VERSION "dbc-export 1 2025.20.8"

NS_ :

BS_:

BU_: ADSP APB APP APS APSB BB BMS CC CMP CMPD CP DAS DI DIF DIR DPB EPAS3P EPAS3S EPASTP EPASTS EPBL EPBR ESP EVSE FC GTW HCML HCMR HVP IBST ICR IDB LS OCS1P ODIN PARK PCS PLG PM PMF PMR PNCD PTC RADC RCM RCM2 RCM3 RCU SCCM SCM SCS SDCR TAS TCU TPMS TRCM UDS UI UIS UMC USM VC VCFRONT VCLEFT VCRIGHT VCSEC VEH

BO_ 1835 TAS_alertLog: 8 TAS
 SG_ TAS_alertID M : 0|9@1+ (1,0) [0|511] "" Vector__XXX
 SG_ TAS_alertState : 15|1@1+ (1,0) [0|1] "" Vector__XXX
 SG_ TAS_a001_InternalWatchdog m1 : 16|1@1+ (1,0) [0|1] "" Vector__XXX
 SG_ TAS_a002_CPUUndervoltage m2 : 16|1@1+ (1,0) [0|1] "" Vector__XXX
 SG_ TAS_a002_PowerOnReset m2 : 17|1@1+ (1,0) [0|1] "" Vector__XXX
 SG_ TAS_a003_AssertID m3 : 16|16@1+ (1,0) [0|65535] "" Vector__XXX
 SG_ TAS_a003_LineNumber m3 : 32|16@1+ (1,0) [0|65535] "" Vector__XXX
 SG_ TAS_a003_Data m3 : 48|16@1+ (1,0) [0|65535] "" Vector__XXX
 SG_ TAS_a012_ClockError m12 : 16|1@1+ (1,0) [0|1] "" Vector__XXX
 SG_ TAS_a012_FlashError m12 : 17|1@1+ (1,0) [0|1] "" Vector__XXX
 SG_ TAS_a012_SoftwareReset m12 : 18|1@1+ (1,0) [0|1] "" Vector__XXX
 SG_ TAS_a012_CheckstopReset m12 : 19|1@1+ (1,0) [0|1] "" Vector__XXX
 SG_ TAS_a012_DebugReset m12 : 20|1@1+ (1,0) [0|1] "" Vector__XXX
 SG_ TAS_a012_ExternalReset m12 : 21|1@1+ (1,0) [0|1] "" Vector__XXX
 SG_ TAS_a021_Task1msLate m21 : 16|1@1+ (1,0) [0|1] "" Vector__XXX
 SG_ TAS_a021_Task1msStarved m21 : 17|1@1+ (1,0) [0|1] "" Vector__XXX
 SG_ TAS_a021_Task1msMissed m21 : 18|1@1+ (1,0) [0|1] "" Vector__XXX
 SG_ TAS_a021_Task10msLate m21 : 19|1@1+ (1,0) [0|1] "" Vector__XXX
 SG_ TAS_a021_Task10msStarved m21 : 20|1@1+ (1,0) [0|1] "" Vector__XXX
 SG_ TAS_a021_Task10msMissed m21 : 21|1@1+ (1,0) [0|1] "" Vector__XXX
 SG_ TAS_a021_Task100msLate m21 : 22|1@1+ (1,0) [0|1] "" Vector__XXX
 SG_ TAS_a021_Task100msStarved m21 : 23|1@1+ (1,0) [0|1] "" Vector__XXX
 SG_ TAS_a021_Task100msMissed m21 : 24|1@1+ (1,0) [0|1] "" Vector__XXX
 SG_ TAS_a021_Task1000msLate m21 : 25|1@1+ (1,0) [0|1] "" Vector__XXX
 SG_ TAS_a021_Task1000msStarved m21 : 26|1@1+ (1,0) [0|1] "" Vector__XXX
 SG_ TAS_a021_Task1000msMissed m21 : 27|1@1+ (1,0) [0|1] "" Vector__XXX
 SG_ TAS_a022_TaskInitErrorCount m22 : 16|8@1+ (1,0) [0|255] "" Vector__XXX
 SG_ TAS_a022_TaskInitError0 m22 : 24|8@1+ (1,0) [0|255] "" Vector__XXX
 SG_ TAS_a022_TaskInitError1 m22 : 32|8@1+ (1,0) [0|255] "" Vector__XXX
 SG_ TAS_a022_TaskInitError2 m22 : 40|8@1+ (1,0) [0|255] "" Vector__XXX
 SG_ TAS_a022_TaskInitError3 m22 : 48|8@1+ (1,0) [0|255] "" Vector__XXX
 SG_ TAS_a022_TaskInitError4 m22 : 56|8@1+ (1,0) [0|255] "" Vector__XXX
 SG_ TAS_a025_vehicleLockAtCrash m25 : 16|1@1+ (1,0) [0|1] "" Vector__XXX
 SG_ TAS_a025_CANCrashIsActive m25 : 17|1@1+ (1,0) [0|1] "" Vector__XXX
 SG_ TAS_a025_appCrashIsActive m25 : 18|1@1+ (1,0) [0|1] "" Vector__XXX
 SG_ TAS_a025_lastCrashEvent m25 : 24|32@1+ (1,0) [0|4294967295] "" Vector__XXX
 SG_ TAS_a030_PWMdutyCycleFL m30 : 16|16@1+ (0.0025,0) [0|163.8375] "%" Vector__XXX
 SG_ TAS_a030_PWMfrequencyFL m30 : 32|16@1+ (0.025,0) [0|1638.375] "Hz" Vector__XXX
 SG_ TAS_a030_PWMfaultFL m30 : 48|4@1+ (1,0) [0|15] "" Vector__XXX
 SG_ TAS_a031_PWMdutyCycleFR m31 : 16|16@1+ (0.0025,0) [0|163.8375] "%" Vector__XXX
 SG_ TAS_a031_PWMfrequencyFR m31 : 32|16@1+ (0.025,0) [0|1638.375] "Hz" Vector__XXX
 SG_ TAS_a031_PWMfaultFR m31 : 48|4@1+ (1,0) [0|15] "" Vector__XXX
 SG_ TAS_a032_PWMdutyCycleRL m32 : 16|16@1+ (0.0025,0) [0|163.8375] "%" Vector__XXX
 SG_ TAS_a032_PWMfrequencyRL m32 : 32|16@1+ (0.025,0) [0|1638.375] "Hz" Vector__XXX
 SG_ TAS_a032_PWMfaultRL m32 : 48|4@1+ (1,0) [0|15] "" Vector__XXX
 SG_ TAS_a033_PWMdutyCycleRR m33 : 16|16@1+ (0.0025,0) [0|163.8375] "%" Vector__XXX
 SG_ TAS_a033_PWMfrequencyRR m33 : 32|16@1+ (0.025,0) [0|1638.375] "Hz" Vector__XXX
 SG_ TAS_a033_PWMfaultRR m33 : 48|4@1+ (1,0) [0|15] "" Vector__XXX
 SG_ TAS_a034_PWMdutyCycleFL m34 : 16|16@1+ (0.0025,0) [0|163.8375] "%" Vector__XXX
 SG_ TAS_a034_PWMfrequencyFL m34 : 32|16@1+ (0.025,0) [0|1638.375] "Hz" Vector__XXX
 SG_ TAS_a034_PWMfaultFL m34 : 48|4@1+ (1,0) [0|15] "" Vector__XXX
 SG_ TAS_a035_PWMdutyCycleFR m35 : 16|16@1+ (0.0025,0) [0|163.8375] "%" Vector__XXX
 SG_ TAS_a035_PWMfrequencyFR m35 : 32|16@1+ (0.025,0) [0|1638.375] "Hz" Vector__XXX
 SG_ TAS_a035_PWMfaultFR m35 : 48|4@1+ (1,0) [0|15] "" Vector__XXX
 SG_ TAS_a036_PWMdutyCycleRL m36 : 16|16@1+ (0.0025,0) [0|163.8375] "%" Vector__XXX
 SG_ TAS_a036_PWMfrequencyRL m36 : 32|16@1+ (0.025,0) [0|1638.375] "Hz" Vector__XXX
 SG_ TAS_a036_PWMfaultRL m36 : 48|4@1+ (1,0) [0|15] "" Vector__XXX
 SG_ TAS_a037_PWMdutyCycleRR m37 : 16|16@1+ (0.0025,0) [0|163.8375] "%" Vector__XXX
 SG_ TAS_a037_PWMfrequencyRR m37 : 32|16@1+ (0.025,0) [0|1638.375] "Hz" Vector__XXX
 SG_ TAS_a037_PWMfaultRR m37 : 48|4@1+ (1,0) [0|15] "" Vector__XXX
 SG_ TAS_a038_PWMdutyCycleFL m38 : 16|16@1+ (0.0025,0) [0|163.8375] "%" Vector__XXX
 SG_ TAS_a038_PWMfrequencyFL m38 : 32|16@1+ (0.025,0) [0|1638.375] "Hz" Vector__XXX
 SG_ TAS_a038_PWMfaultFL m38 : 48|4@1+ (1,0) [0|15] "" Vector__XXX
 SG_ TAS_a039_PWMdutyCycleFR m39 : 16|16@1+ (0.0025,0) [0|163.8375] "%" Vector__XXX
 SG_ TAS_a039_PWMfrequencyFR m39 : 32|16@1+ (0.025,0) [0|1638.375] "Hz" Vector__XXX
 SG_ TAS_a039_PWMfaultFR m39 : 48|4@1+ (1,0) [0|15] "" Vector__XXX
 SG_ TAS_a040_PWMdutyCycleRL m40 : 16|16@1+ (0.0025,0) [0|163.8375] "%" Vector__XXX
 SG_ TAS_a040_PWMfrequencyRL m40 : 32|16@1+ (0.025,0) [0|1638.375] "Hz" Vector__XXX
 SG_ TAS_a040_PWMfaultRL m40 : 48|4@1+ (1,0) [0|15] "" Vector__XXX
 SG_ TAS_a041_PWMdutyCycleRR m41 : 16|16@1+ (0.0025,0) [0|163.8375] "%" Vector__XXX
 SG_ TAS_a041_PWMfrequencyRR m41 : 32|16@1+ (0.025,0) [0|1638.375] "Hz" Vector__XXX
 SG_ TAS_a041_PWMfaultRR m41 : 48|4@1+ (1,0) [0|15] "" Vector__XXX
 SG_ TAS_a070_voltage12V m70 : 16|16@1+ (0.001,0) [0|65.535] "V" Vector__XXX
 SG_ TAS_a071_voltage12V m71 : 16|16@1+ (0.001,0) [0|65.535] "V" Vector__XXX
 SG_ TAS_a072_voltage5VOnBoard m72 : 16|16@1+ (0.001,0) [0|65.535] "V" Vector__XXX
 SG_ TAS_a073_voltage5VOnBoard m73 : 16|16@1+ (0.001,0) [0|65.535] "V" Vector__XXX
 SG_ TAS_a074_voltage5VOffBoard m74 : 16|16@1+ (0.001,0) [0|65.535] "V" Vector__XXX
 SG_ TAS_a075_voltage5VOffBoard m75 : 16|16@1+ (0.001,0) [0|65.535] "V" Vector__XXX
 SG_ TAS_a076_voltage5VOffBoard m76 : 16|16@1+ (0.001,0) [0|65.535] "V" Vector__XXX
 SG_ TAS_a077_sensorVoltage m77 : 16|16@1+ (0.001,0) [0|65.535] "V" Vector__XXX
 SG_ TAS_a077_sensorRefVoltage m77 : 32|16@1+ (0.001,0) [0|65.535] "V" Vector__XXX
 SG_ TAS_a078_sensorVoltage m78 : 16|16@1+ (0.001,0) [0|65.535] "V" Vector__XXX
 SG_ TAS_a078_sensorRefVoltage m78 : 32|16@1+ (0.001,0) [0|65.535] "V" Vector__XXX
 SG_ TAS_a080_voltage5VHeight m80 : 16|16@1+ (0.001,0) [0|65.535] "V" Vector__XXX
 SG_ TAS_a081_voltage5VHeight m81 : 16|16@1+ (0.001,0) [0|65.535] "V" Vector__XXX
 SG_ TAS_a082_voltage5VHeight m82 : 16|16@1+ (0.001,0) [0|65.535] "V" Vector__XXX
 SG_ TAS_a083_voltage5VAnalog m83 : 16|16@1+ (0.001,0) [0|65.535] "V" Vector__XXX
 SG_ TAS_a084_voltage5VAnalog m84 : 16|16@1+ (0.001,0) [0|65.535] "V" Vector__XXX
 SG_ TAS_a085_voltage5VAnalog m85 : 16|16@1+ (0.001,0) [0|65.535] "V" Vector__XXX
 SG_ TAS_a086_voltage12VSwitched m86 : 16|16@1+ (0.001,0) [0|65.535] "V" Vector__XXX
 SG_ TAS_a087_voltage12VSwitched m87 : 16|16@1+ (0.001,0) [0|65.535] "V" Vector__XXX
 SG_ TAS_a093_readError m93 : 16|1@1+ (1,0) [0|1] "" Vector__XXX
 SG_ TAS_a093_IVOR2Exception m93 : 17|1@1+ (1,0) [0|1] "" Vector__XXX
 SG_ TAS_a098_VCFRONT_LVPowerState_MI m98 : 16|1@1+ (1,0) [0|1] "" Vector__XXX
 SG_ TAS_a098_VCFRONT_sensors_MIA m98 : 17|1@1+ (1,0) [0|1] "" Vector__XXX
 SG_ TAS_a098_VCFRONT_status_MIA m98 : 18|1@1+ (1,0) [0|1] "" Vector__XXX
 SG_ TAS_a098_VCFRONT_systemStatus_MI m98 : 19|1@1+ (1,0) [0|1] "" Vector__XXX
 SG_ TAS_a098_VCFRONT_vehNm_MIA m98 : 20|1@1+ (1,0) [0|1] "" Vector__XXX
 SG_ TAS_a099_UI_chassisControl_MIA m99 : 16|1@1+ (1,0) [0|1] "" Vector__XXX
 SG_ TAS_a099_UI_driverAssistMapData_ m99 : 17|1@1+ (1,0) [0|1] "" Vector__XXX
 SG_ TAS_a099_UI_suspensionControl_MI m99 : 18|1@1+ (1,0) [0|1] "" Vector__XXX
 SG_ TAS_a099_UI_vehicleModes_MIA m99 : 19|1@1+ (1,0) [0|1] "" Vector__XXX
 SG_ TAS_a100_RCM_inertial1_MIA m100 : 16|1@1+ (1,0) [0|1] "" Vector__XXX
 SG_ TAS_a100_RCM_inertial2_MIA m100 : 17|1@1+ (1,0) [0|1] "" Vector__XXX
 SG_ TAS_a101_ESP_brakeTorque_MIA m101 : 16|1@1+ (1,0) [0|1] "" Vector__XXX
 SG_ TAS_a101_ESP_status_MIA m101 : 17|1@1+ (1,0) [0|1] "" Vector__XXX
 SG_ TAS_a101_ESP_wheelRotation_MIA m101 : 18|1@1+ (1,0) [0|1] "" Vector__XXX
 SG_ TAS_a102_DI_chassisControl_MIA m102 : 16|1@1+ (1,0) [0|1] "" Vector__XXX
 SG_ TAS_a102_DI_locStatus_MIA m102 : 17|1@1+ (1,0) [0|1] "" Vector__XXX
 SG_ TAS_a102_DI_speed_MIA m102 : 18|1@1+ (1,0) [0|1] "" Vector__XXX
 SG_ TAS_a102_DI_systemStatus_MIA m102 : 19|1@1+ (1,0) [0|1] "" Vector__XXX
 SG_ TAS_a102_DI_vehicleEstimates_MIA m102 : 20|1@1+ (1,0) [0|1] "" Vector__XXX
 SG_ TAS_a102_DIF_torque_MIA m102 : 21|1@1+ (1,0) [0|1] "" Vector__XXX
 SG_ TAS_a102_DIR_torque_MIA m102 : 22|1@1+ (1,0) [0|1] "" Vector__XXX
 SG_ TAS_a103_GTW_carConfig_MIA m103 : 16|1@1+ (1,0) [0|1] "" Vector__XXX
 SG_ TAS_a103_GTW_time_MIA m103 : 17|1@1+ (1,0) [0|1] "" Vector__XXX
 SG_ TAS_a103_GTW_vehNm_MIA m103 : 18|1@1+ (1,0) [0|1] "" Vector__XXX
 SG_ TAS_a103_GTW_vin_MIA m103 : 19|1@1+ (1,0) [0|1] "" Vector__XXX
 SG_ TAS_a164_detectedDamperSolenoid m164 : 16|3@1+ (1,0) [0|7] "" Vector__XXX
 SG_ TAS_a164_expectedDamperSolenoid m164 : 19|3@1+ (1,0) [0|7] "" Vector__XXX
 SG_ TAS_a165_damperValveFault m165 : 16|4@1+ (1,0) [0|15] "" Vector__XXX
 SG_ TAS_a166_damperValveFault m166 : 16|4@1+ (1,0) [0|15] "" Vector__XXX
 SG_ TAS_a167_damperValveFault m167 : 16|4@1+ (1,0) [0|15] "" Vector__XXX
 SG_ TAS_a168_damperValveFault m168 : 16|4@1+ (1,0) [0|15] "" Vector__XXX
 SG_ TAS_a169_damperValveFault m169 : 16|4@1+ (1,0) [0|15] "" Vector__XXX
 SG_ TAS_a170_damperValveFault m170 : 16|4@1+ (1,0) [0|15] "" Vector__XXX
 SG_ TAS_a171_damperValveFault m171 : 16|4@1+ (1,0) [0|15] "" Vector__XXX
 SG_ TAS_a172_damperValveFault m172 : 16|4@1+ (1,0) [0|15] "" Vector__XXX
 SG_ TAS_a173_heightDelta_mm m173 : 16|8@1+ (1,-128) [-128|127] "mm" Vector__XXX
 SG_ TAS_a174_heightDelta_mm m174 : 16|8@1+ (1,-128) [-128|127] "mm" Vector__XXX
 SG_ TAS_a175_heightDelta_mm m175 : 16|8@1+ (1,-128) [-128|127] "mm" Vector__XXX
 SG_ TAS_a176_heightDelta_mm m176 : 16|8@1+ (1,-128) [-128|127] "mm" Vector__XXX
 SG_ TAS_a190_a2bFaultType m190 : 16|4@1+ (1,0) [0|15] "" Vector__XXX
 SG_ TAS_a190_a2bInterruptType m190 : 24|8@1+ (1,0) [0|255] "" Vector__XXX
 SG_ TAS_a190_a2bFaultSource m190 : 32|2@1+ (1,0) [0|3] "" Vector__XXX
 SG_ TAS_a191_a2bFaultType m191 : 16|4@1+ (1,0) [0|15] "" Vector__XXX
 SG_ TAS_a191_a2bInterruptType m191 : 24|8@1+ (1,0) [0|255] "" Vector__XXX
 SG_ TAS_a191_a2bFaultSource m191 : 32|2@1+ (1,0) [0|3] "" Vector__XXX
 SG_ TAS_a192_rideHeightVelDspFL m192 : 16|5@1- (0.2,0) [-3.2|3] "mps" Vector__XXX
 SG_ TAS_a192_rideHeightVelDspFR m192 : 24|5@1- (0.2,0) [-3.2|3] "mps" Vector__XXX
 SG_ TAS_a192_rideHeightVelDspRL m192 : 32|5@1- (0.2,0) [-3.2|3] "mps" Vector__XXX
 SG_ TAS_a192_rideHeightVelDspRR m192 : 37|5@1- (0.2,0) [-3.2|3] "mps" Vector__XXX
 SG_ TAS_a192_rideHeightVelObserverFL m192 : 42|5@1- (0.2,0) [-3.2|3] "mps" Vector__XXX
 SG_ TAS_a192_rideHeightVelObserverFR m192 : 47|5@1- (0.2,0) [-3.2|3] "mps" Vector__XXX
 SG_ TAS_a192_rideHeightVelObserverRL m192 : 52|5@1- (0.2,0) [-3.2|3] "mps" Vector__XXX
 SG_ TAS_a192_rideHeightVelObserverRR m192 : 57|5@1- (0.2,0) [-3.2|3] "mps" Vector__XXX
 SG_ TAS_a192_alertVersion m192 : 62|2@1+ (1,0) [0|3] "" Vector__XXX
 SG_ TAS_a193_EPAS3P_sysStatus_MIA m193 : 16|1@1+ (1,0) [0|1] "" Vector__XXX
 SG_ TAS_a210_heightSensorDeltaFL m210 : 16|8@1+ (1,-128) [-128|127] "mm" Vector__XXX
 SG_ TAS_a210_heightSensorDeltaFR m210 : 24|8@1+ (1,-128) [-128|127] "mm" Vector__XXX
 SG_ TAS_a210_heightSensorDeltaRL m210 : 32|8@1+ (1,-128) [-128|127] "mm" Vector__XXX
 SG_ TAS_a210_heightSensorDeltaRR m210 : 40|8@1+ (1,-128) [-128|127] "mm" Vector__XXX
 SG_ TAS_a220_galleryPressure m220 : 16|8@1+ (0.1,0) [0|25.5] "bara" Vector__XXX
 SG_ TAS_a220_timeInExhaust m220 : 24|32@1+ (1,0) [0|4294967295] "ms" Vector__XXX
 SG_ TAS_a221_galleryPressureDelta m221 : 16|8@1+ (0.1,0) [0|25.5] "bar" Vector__XXX
 SG_ TAS_a221_timeInIdle m221 : 24|32@1+ (1,0) [0|4294967295] "ms" Vector__XXX
 SG_ TAS_a222_galleryPressureDelta m222 : 16|8@1+ (0.1,0) [0|25.5] "bar" Vector__XXX
 SG_ TAS_a223_galleryPressure m223 : 16|8@1+ (0.1,0) [0|25.5] "bara" Vector__XXX
 SG_ TAS_a223_valveOnFL m223 : 24|1@1+ (1,0) [0|1] "" Vector__XXX
 SG_ TAS_a223_valveOnFR m223 : 25|1@1+ (1,0) [0|1] "" Vector__XXX
 SG_ TAS_a223_valveOnRL m223 : 26|1@1+ (1,0) [0|1] "" Vector__XXX
 SG_ TAS_a223_valveOnRR m223 : 27|1@1+ (1,0) [0|1] "" Vector__XXX
 SG_ TAS_a223_valveOnReservoir m223 : 28|1@1+ (1,0) [0|1] "" Vector__XXX
 SG_ TAS_a224_galleryPressure m224 : 16|8@1+ (0.1,0) [0|25.5] "bara" Vector__XXX
 SG_ TAS_a224_valveOnFL m224 : 24|1@1+ (1,0) [0|1] "" Vector__XXX
 SG_ TAS_a224_valveOnFR m224 : 25|1@1+ (1,0) [0|1] "" Vector__XXX
 SG_ TAS_a224_valveOnRL m224 : 26|1@1+ (1,0) [0|1] "" Vector__XXX
 SG_ TAS_a224_valveOnRR m224 : 27|1@1+ (1,0) [0|1] "" Vector__XXX
 SG_ TAS_a224_valveOnReservoir m224 : 28|1@1+ (1,0) [0|1] "" Vector__XXX
 SG_ TAS_a225_galleryPressure m225 : 16|8@1+ (0.1,0) [0|25.5] "bara" Vector__XXX
 SG_ TAS_a226_PWMdutyCycleFL m226 : 16|16@1+ (0.0025,0) [0|163.8375] "%" Vector__XXX
 SG_ TAS_a226_PWMfrequencyFL m226 : 32|16@1+ (0.025,0) [0|1638.375] "Hz" Vector__XXX
 SG_ TAS_a226_PWMfaultFL m226 : 48|4@1+ (1,0) [0|15] "" Vector__XXX
 SG_ TAS_a227_PWMdutyCycleFR m227 : 16|16@1+ (0.0025,0) [0|163.8375] "%" Vector__XXX
 SG_ TAS_a227_PWMfrequencyFR m227 : 32|16@1+ (0.025,0) [0|1638.375] "Hz" Vector__XXX
 SG_ TAS_a227_PWMfaultFR m227 : 48|4@1+ (1,0) [0|15] "" Vector__XXX
 SG_ TAS_a228_PWMdutyCycleRL m228 : 16|16@1+ (0.0025,0) [0|163.8375] "%" Vector__XXX
 SG_ TAS_a228_PWMfrequencyRL m228 : 32|16@1+ (0.025,0) [0|1638.375] "Hz" Vector__XXX
 SG_ TAS_a228_PWMfaultRL m228 : 48|4@1+ (1,0) [0|15] "" Vector__XXX
 SG_ TAS_a229_PWMdutyCycleRR m229 : 16|16@1+ (0.0025,0) [0|163.8375] "%" Vector__XXX
 SG_ TAS_a229_PWMfrequencyRR m229 : 32|16@1+ (0.025,0) [0|1638.375] "Hz" Vector__XXX
 SG_ TAS_a229_PWMfaultRR m229 : 48|4@1+ (1,0) [0|15] "" Vector__XXX
 SG_ TAS_a232_detectedSuspensionType m232 : 16|3@1+ (1,0) [0|7] "" Vector__XXX
 SG_ TAS_a232_expectedSuspensionType m232 : 19|3@1+ (1,0) [0|7] "" Vector__XXX
 SG_ TAS_a234_detectedDamperHydraulic m234 : 16|2@1+ (1,0) [0|3] "" Vector__XXX
 SG_ TAS_a234_expectedDamperHydraulic m234 : 18|2@1+ (1,0) [0|3] "" Vector__XXX
 SG_ TAS_a240_highAdjustCountRatio m240 : 16|1@1+ (1,0) [0|1] "" Vector__XXX
 SG_ TAS_a240_highAdjustTimeRatio m240 : 17|1@1+ (1,0) [0|1] "" Vector__XXX
 SG_ TAS_a240_highCrossPressure m240 : 18|1@1+ (1,0) [0|1] "" Vector__XXX
 SG_ TAS_a240_highCompExhTimeRatio m240 : 19|1@1+ (1,0) [0|1] "" Vector__XXX
 SG_ TAS_a240_adjustCountRatioSpring m240 : 20|3@1+ (1,0) [0|7] "" Vector__XXX
 SG_ TAS_a240_adjustCountRatio m240 : 24|8@1+ (0.02952756,0) [0|7.50000024] "InflateCount/DeflateCount" Vector__XXX
 SG_ TAS_a240_adjustTimeRatioSpring m240 : 32|3@1+ (1,0) [0|7] "" Vector__XXX
 SG_ TAS_a240_adjustTimeRatio m240 : 40|8@1+ (0.02952756,0) [0|7.50000024] "InflateTime/DeflateTime" Vector__XXX
 SG_ TAS_a240_compExhTimeRatio m240 : 48|8@1+ (0.0294117648154,0) [0|7.50000002793] "CompressorTime/ExhaustTime" Vector__XXX
 SG_ TAS_a240_crossPressure m240 : 56|8@1- (0.1,0) [-12.8|12.7] "bara/bara" Vector__XXX
 SG_ TAS_a285_twistLevel m285 : 16|8@1+ (1,-128) [-128|127] "mm" Vector__XXX
 SG_ TAS_a290_twistLevel m290 : 16|8@1+ (1,-128) [-128|127] "mm" Vector__XXX
 SG_ TAS_a291_frontAxleHeight m291 : 16|8@1+ (1,-128) [-128|127] "mm" Vector__XXX
 SG_ TAS_a292_rearAxleHeight m292 : 16|8@1+ (1,-128) [-128|127] "mm" Vector__XXX
 SG_ TAS_a293_frontAxleHeight m293 : 16|8@1+ (1,-128) [-128|127] "mm" Vector__XXX
 SG_ TAS_a294_rearAxleHeight m294 : 16|8@1+ (1,-128) [-128|127] "mm" Vector__XXX
 SG_ TAS_a295_targetHeight m295 : 16|8@1+ (1,-128) [-128|127] "mm" Vector__XXX
 SG_ TAS_a296_detectedChassisType m296 : 16|3@1+ (1,0) [0|7] "" Vector__XXX
 SG_ TAS_a296_expectedChassisType m296 : 19|3@1+ (1,0) [0|7] "" Vector__XXX
 SG_ TAS_a319_detectedDrivetrainType m319 : 16|2@1+ (1,0) [0|3] "" Vector__XXX
 SG_ TAS_a319_expectedDrivetrainType m319 : 18|2@1+ (1,0) [0|3] "" Vector__XXX

BO_ 852 TAS_alertMatrix: 8 TAS
 SG_ TAS_matrixIndex M : 0|4@1+ (1,0) [0|15] "" Vector__XXX
 SG_ TAS_a001_WatchdogReset m0 : 4|1@1+ (1,0) [0|1] "" Vector__XXX
 SG_ TAS_a002_PowerLossReset m0 : 5|1@1+ (1,0) [0|1] "" Vector__XXX
 SG_ TAS_a003_SWAssertion m0 : 6|1@1+ (1,0) [0|1] "" Vector__XXX
 SG_ TAS_a012_CPUReset m0 : 15|1@1+ (1,0) [0|1] "" Vector__XXX
 SG_ TAS_a015_NVMMError m0 : 18|1@1+ (1,0) [0|1] "" Vector__XXX
 SG_ TAS_a016_NVMMRecordError m0 : 19|1@1+ (1,0) [0|1] "" Vector__XXX
 SG_ TAS_a021_TaskSchedulerError m0 : 24|1@1+ (1,0) [0|1] "" Vector__XXX
 SG_ TAS_a022_TaskInitError m0 : 25|1@1+ (1,0) [0|1] "" Vector__XXX
 SG_ TAS_a023_rtosResetRequested m0 : 26|1@1+ (1,0) [0|1] "" Vector__XXX
 SG_ TAS_a024_prefetchAbort m0 : 27|1@1+ (1,0) [0|1] "" Vector__XXX
 SG_ TAS_a025_CrashEvent m0 : 28|1@1+ (1,0) [0|1] "" Vector__XXX
 SG_ TAS_a030_PWMerrorFL m0 : 33|1@1+ (1,0) [0|1] "" Vector__XXX
 SG_ TAS_a031_PWMerrorFR m0 : 34|1@1+ (1,0) [0|1] "" Vector__XXX
 SG_ TAS_a032_PWMerrorRL m0 : 35|1@1+ (1,0) [0|1] "" Vector__XXX
 SG_ TAS_a033_PWMerrorRR m0 : 36|1@1+ (1,0) [0|1] "" Vector__XXX
 SG_ TAS_a034_PWMshortFL m0 : 37|1@1+ (1,0) [0|1] "" Vector__XXX
 SG_ TAS_a035_PWMshortFR m0 : 38|1@1+ (1,0) [0|1] "" Vector__XXX
 SG_ TAS_a036_PWMshortRL m0 : 39|1@1+ (1,0) [0|1] "" Vector__XXX
 SG_ TAS_a037_PWMshortRR m0 : 40|1@1+ (1,0) [0|1] "" Vector__XXX
 SG_ TAS_a038_PWMopenFL m0 : 41|1@1+ (1,0) [0|1] "" Vector__XXX
 SG_ TAS_a039_PWMopenFR m0 : 42|1@1+ (1,0) [0|1] "" Vector__XXX
 SG_ TAS_a040_PWMopenRL m0 : 43|1@1+ (1,0) [0|1] "" Vector__XXX
 SG_ TAS_a041_PWMopenRR m0 : 44|1@1+ (1,0) [0|1] "" Vector__XXX
 SG_ TAS_a043_Task1msError m0 : 46|1@1+ (1,0) [0|1] "" Vector__XXX
 SG_ TAS_a044_Task10msError m0 : 47|1@1+ (1,0) [0|1] "" Vector__XXX
 SG_ TAS_a045_Task100msError m0 : 48|1@1+ (1,0) [0|1] "" Vector__XXX
 SG_ TAS_a046_Task1000msError m0 : 49|1@1+ (1,0) [0|1] "" Vector__XXX
 SG_ TAS_a061_XCPConnected m1 : 4|1@1+ (1,0) [0|1] "" Vector__XXX
 SG_ TAS_a062_XCPWasConnected m1 : 5|1@1+ (1,0) [0|1] "" Vector__XXX
 SG_ TAS_a063_abortFault m1 : 6|1@1+ (1,0) [0|1] "" Vector__XXX
 SG_ TAS_a064_abortFaultExt m1 : 7|1@1+ (1,0) [0|1] "" Vector__XXX
 SG_ TAS_a065_ahbWriteFault m1 : 8|1@1+ (1,0) [0|1] "" Vector__XXX
 SG_ TAS_a066_undefinedInstructionAbo m1 : 9|1@1+ (1,0) [0|1] "" Vector__XXX
 SG_ TAS_a067_reservedHandlerAbort m1 : 10|1@1+ (1,0) [0|1] "" Vector__XXX
 SG_ TAS_a070_underVoltage12V m1 : 13|1@1+ (1,0) [0|1] "" Vector__XXX
 SG_ TAS_a071_overVoltage12V m1 : 14|1@1+ (1,0) [0|1] "" Vector__XXX
 SG_ TAS_a072_shortCircuit5VOnBoard m1 : 15|1@1+ (1,0) [0|1] "" Vector__XXX
 SG_ TAS_a073_underVoltage5VOnBoard m1 : 16|1@1+ (1,0) [0|1] "" Vector__XXX
 SG_ TAS_a074_shortCircuit5VOffBoard m1 : 17|1@1+ (1,0) [0|1] "" Vector__XXX
 SG_ TAS_a075_underVoltage5VOffBoard m1 : 18|1@1+ (1,0) [0|1] "" Vector__XXX
 SG_ TAS_a076_overVoltage5VOffBoard m1 : 19|1@1+ (1,0) [0|1] "" Vector__XXX
 SG_ TAS_a077_pressureSigVTooLow m1 : 20|1@1+ (1,0) [0|1] "" Vector__XXX
 SG_ TAS_a078_pressureSigVTooHigh m1 : 21|1@1+ (1,0) [0|1] "" Vector__XXX
 SG_ TAS_a080_shortCircuit5VHeight m1 : 23|1@1+ (1,0) [0|1] "" Vector__XXX
 SG_ TAS_a081_underVoltage5VHeight m1 : 24|1@1+ (1,0) [0|1] "" Vector__XXX
 SG_ TAS_a082_overVoltage5VHeight m1 : 25|1@1+ (1,0) [0|1] "" Vector__XXX
 SG_ TAS_a083_shortCircuit5VAnalog m1 : 26|1@1+ (1,0) [0|1] "" Vector__XXX
 SG_ TAS_a084_underVoltage5VAnalog m1 : 27|1@1+ (1,0) [0|1] "" Vector__XXX
 SG_ TAS_a085_overVoltage5VAnalog m1 : 28|1@1+ (1,0) [0|1] "" Vector__XXX
 SG_ TAS_a086_underVoltage12VSwtchd m1 : 29|1@1+ (1,0) [0|1] "" Vector__XXX
 SG_ TAS_a087_overVoltage12VSwtchd m1 : 30|1@1+ (1,0) [0|1] "" Vector__XXX
 SG_ TAS_a093_OTPError m1 : 36|1@1+ (1,0) [0|1] "" Vector__XXX
 SG_ TAS_a098_VCFRONT_MIA m1 : 41|1@1+ (1,0) [0|1] "" Vector__XXX
 SG_ TAS_a099_UI_MIA m1 : 42|1@1+ (1,0) [0|1] "" Vector__XXX
 SG_ TAS_a100_RCM_MIA m1 : 43|1@1+ (1,0) [0|1] "" Vector__XXX
 SG_ TAS_a101_ESP_MIA m1 : 44|1@1+ (1,0) [0|1] "" Vector__XXX
 SG_ TAS_a102_DI_MIA m1 : 45|1@1+ (1,0) [0|1] "" Vector__XXX
 SG_ TAS_a103_GTW_MIA m1 : 46|1@1+ (1,0) [0|1] "" Vector__XXX
 SG_ TAS_a105_ECUDebugMode m1 : 48|1@1+ (1,0) [0|1] "" Vector__XXX
 SG_ TAS_a106_HighCPULoad m1 : 49|1@1+ (1,0) [0|1] "" Vector__XXX
 SG_ TAS_a107_HighStackUsage m1 : 50|1@1+ (1,0) [0|1] "" Vector__XXX
 SG_ TAS_a150_accelAvgImplausible_FL_ m2 : 33|1@1+ (1,0) [0|1] "" Vector__XXX
 SG_ TAS_a151_accelAvgImplausible_FL_ m2 : 34|1@1+ (1,0) [0|1] "" Vector__XXX
 SG_ TAS_a152_accelAvgImplausible_FL_ m2 : 35|1@1+ (1,0) [0|1] "" Vector__XXX
 SG_ TAS_a153_accelAvgImplausible_FR_ m2 : 36|1@1+ (1,0) [0|1] "" Vector__XXX
 SG_ TAS_a154_accelAvgImplausible_FR_ m2 : 37|1@1+ (1,0) [0|1] "" Vector__XXX
 SG_ TAS_a155_accelAvgImplausible_FR_ m2 : 38|1@1+ (1,0) [0|1] "" Vector__XXX
 SG_ TAS_a156_accelAvgImplausible_RL_ m2 : 39|1@1+ (1,0) [0|1] "" Vector__XXX
 SG_ TAS_a157_accelAvgImplausible_RL_ m2 : 40|1@1+ (1,0) [0|1] "" Vector__XXX
 SG_ TAS_a158_accelAvgImplausible_RL_ m2 : 41|1@1+ (1,0) [0|1] "" Vector__XXX
 SG_ TAS_a159_accelAvgImplausible_RR_ m2 : 42|1@1+ (1,0) [0|1] "" Vector__XXX
 SG_ TAS_a160_accelAvgImplausible_RR_ m2 : 43|1@1+ (1,0) [0|1] "" Vector__XXX
 SG_ TAS_a161_accelAvgImplausible_RR_ m2 : 44|1@1+ (1,0) [0|1] "" Vector__XXX
 SG_ TAS_a164_damperSolenoidMismatch m2 : 47|1@1+ (1,0) [0|1] "" Vector__XXX
 SG_ TAS_a165_damperValveCompFL m2 : 48|1@1+ (1,0) [0|1] "" Vector__XXX
 SG_ TAS_a166_damperValveRbndFL m2 : 49|1@1+ (1,0) [0|1] "" Vector__XXX
 SG_ TAS_a167_damperValveCompFR m2 : 50|1@1+ (1,0) [0|1] "" Vector__XXX
 SG_ TAS_a168_damperValveRbndFR m2 : 51|1@1+ (1,0) [0|1] "" Vector__XXX
 SG_ TAS_a169_damperValveCompRL m2 : 52|1@1+ (1,0) [0|1] "" Vector__XXX
 SG_ TAS_a170_damperValveRbndRL m2 : 53|1@1+ (1,0) [0|1] "" Vector__XXX
 SG_ TAS_a171_damperValveCompRR m2 : 54|1@1+ (1,0) [0|1] "" Vector__XXX
 SG_ TAS_a172_damperValveRbndRR m2 : 55|1@1+ (1,0) [0|1] "" Vector__XXX
 SG_ TAS_a173_staticLeakDetectFL m2 : 56|1@1+ (1,0) [0|1] "" Vector__XXX
 SG_ TAS_a174_staticLeakDetectFR m2 : 57|1@1+ (1,0) [0|1] "" Vector__XXX
 SG_ TAS_a175_staticLeakDetectRL m2 : 58|1@1+ (1,0) [0|1] "" Vector__XXX
 SG_ TAS_a176_staticLeakDetectRR m2 : 59|1@1+ (1,0) [0|1] "" Vector__XXX
 SG_ TAS_a190_a2bFrontAxleFault m3 : 13|1@1+ (1,0) [0|1] "" Vector__XXX
 SG_ TAS_a191_a2bRearAxleFault m3 : 14|1@1+ (1,0) [0|1] "" Vector__XXX
 SG_ TAS_a192_rideHeightObserverDiver m3 : 15|1@1+ (1,0) [0|1] "" Vector__XXX
 SG_ TAS_a193_EPAS3P_MIA m3 : 16|1@1+ (1,0) [0|1] "" Vector__XXX
 SG_ TAS_a194_a2bFrontAxleDataError m3 : 17|1@1+ (1,0) [0|1] "" Vector__XXX
 SG_ TAS_a195_a2bRearAxleDataError m3 : 18|1@1+ (1,0) [0|1] "" Vector__XXX
 SG_ TAS_a196_adaptiveDampingUsingDSP m3 : 19|1@1+ (1,0) [0|1] "" Vector__XXX
 SG_ TAS_a197_invalidAdaptiveModeRequ m3 : 20|1@1+ (1,0) [0|1] "" Vector__XXX
 SG_ TAS_a200_jackModeActive m3 : 23|1@1+ (1,0) [0|1] "" Vector__XXX
 SG_ TAS_a201_low12VBattery m3 : 24|1@1+ (1,0) [0|1] "" Vector__XXX
 SG_ TAS_a210_outOfRangeCalibration m3 : 33|1@1+ (1,0) [0|1] "" Vector__XXX
 SG_ TAS_a211_noRideHeightCalib m3 : 34|1@1+ (1,0) [0|1] "" Vector__XXX
 SG_ TAS_a213_yellowWarningLamp m3 : 36|1@1+ (1,0) [0|1] "" Vector__XXX
 SG_ TAS_a214_redWarningLamp m3 : 37|1@1+ (1,0) [0|1] "" Vector__XXX
 SG_ TAS_a215_limpHomeMode10 m3 : 38|1@1+ (1,0) [0|1] "" Vector__XXX
 SG_ TAS_a216_limpHomeMode20 m3 : 39|1@1+ (1,0) [0|1] "" Vector__XXX
 SG_ TAS_a217_limpHomeMode30 m3 : 40|1@1+ (1,0) [0|1] "" Vector__XXX
 SG_ TAS_a218_limpHomeMode40 m3 : 41|1@1+ (1,0) [0|1] "" Vector__XXX
 SG_ TAS_a220_exhaustGalleryFault m3 : 43|1@1+ (1,0) [0|1] "" Vector__XXX
 SG_ TAS_a221_valveLeakDetected m3 : 44|1@1+ (1,0) [0|1] "" Vector__XXX
 SG_ TAS_a222_compressorPrefillFault m3 : 45|1@1+ (1,0) [0|1] "" Vector__XXX
 SG_ TAS_a223_blockedAirline m3 : 46|1@1+ (1,0) [0|1] "" Vector__XXX
 SG_ TAS_a224_openAirline m3 : 47|1@1+ (1,0) [0|1] "" Vector__XXX
 SG_ TAS_a225_galleryPressureTooHigh m3 : 48|1@1+ (1,0) [0|1] "" Vector__XXX
 SG_ TAS_a226_PWMfastDetectFL m3 : 49|1@1+ (1,0) [0|1] "" Vector__XXX
 SG_ TAS_a227_PWMfastDetectFR m3 : 50|1@1+ (1,0) [0|1] "" Vector__XXX
 SG_ TAS_a228_PWMfastDetectRL m3 : 51|1@1+ (1,0) [0|1] "" Vector__XXX
 SG_ TAS_a229_PWMfastDetectRR m3 : 52|1@1+ (1,0) [0|1] "" Vector__XXX
 SG_ TAS_a230_notifyGeofence m3 : 53|1@1+ (1,0) [0|1] "" Vector__XXX
 SG_ TAS_a231_notifyRoughRoadRaise m3 : 54|1@1+ (1,0) [0|1] "" Vector__XXX
 SG_ TAS_a232_suspensionTypeMismatch m3 : 55|1@1+ (1,0) [0|1] "" Vector__XXX
 SG_ TAS_a233_compressorStuckOn m3 : 56|1@1+ (1,0) [0|1] "" Vector__XXX
 SG_ TAS_a234_damperHydraulicMismatch m3 : 57|1@1+ (1,0) [0|1] "" Vector__XXX
 SG_ TAS_a240_airSpringLeak m3 : 63|1@1+ (1,0) [0|1] "" Vector__XXX
 SG_ TAS_a284_serviceRunModeActive m4 : 47|1@1+ (1,0) [0|1] "" Vector__XXX
 SG_ TAS_a285_twistSustainedUserVis m4 : 48|1@1+ (1,0) [0|1] "" Vector__XXX
 SG_ TAS_a286_driveCycleStats1 m4 : 49|1@1+ (1,0) [0|1] "" Vector__XXX
 SG_ TAS_a287_driveCycleStats2 m4 : 50|1@1+ (1,0) [0|1] "" Vector__XXX
 SG_ TAS_a288_driveCycleStats3 m4 : 51|1@1+ (1,0) [0|1] "" Vector__XXX
 SG_ TAS_a289_driveCycleStats4 m4 : 52|1@1+ (1,0) [0|1] "" Vector__XXX
 SG_ TAS_a290_twistSustainedAtSpeed m4 : 53|1@1+ (1,0) [0|1] "" Vector__XXX
 SG_ TAS_a291_frontAxleTooHigh m4 : 54|1@1+ (1,0) [0|1] "" Vector__XXX
 SG_ TAS_a292_rearAxleTooHigh m4 : 55|1@1+ (1,0) [0|1] "" Vector__XXX
 SG_ TAS_a293_frontAxleTooLow m4 : 56|1@1+ (1,0) [0|1] "" Vector__XXX
 SG_ TAS_a294_rearAxleTooLow m4 : 57|1@1+ (1,0) [0|1] "" Vector__XXX
 SG_ TAS_a295_targetHeightNotMet m4 : 58|1@1+ (1,0) [0|1] "" Vector__XXX
 SG_ TAS_a296_chassisTypeMismatch m4 : 59|1@1+ (1,0) [0|1] "" Vector__XXX
 SG_ TAS_a297_vinMismatch m4 : 60|1@1+ (1,0) [0|1] "" Vector__XXX
 SG_ TAS_a298_vinNotLearned m4 : 61|1@1+ (1,0) [0|1] "" Vector__XXX
 SG_ TAS_a299_offsetEstimateTooLarge m4 : 62|1@1+ (1,0) [0|1] "" Vector__XXX
 SG_ TAS_a300_offsetEstimateData1 m4 : 63|1@1+ (1,0) [0|1] "" Vector__XXX
 SG_ TAS_a301_offsetEstimateData2 m5 : 4|1@1+ (1,0) [0|1] "" Vector__XXX
 SG_ TAS_a303_massEstimateFrozen m5 : 6|1@1+ (1,0) [0|1] "" Vector__XXX
 SG_ TAS_a304_massEstimateFrozenData m5 : 7|1@1+ (1,0) [0|1] "" Vector__XXX
 SG_ TAS_a305_newEndstopPosition m5 : 8|1@1+ (1,0) [0|1] "" Vector__XXX
 SG_ TAS_a306_hardwareProtectFrozen m5 : 9|1@1+ (1,0) [0|1] "" Vector__XXX
 SG_ TAS_a307_endstopBoundaryComp m5 : 10|1@1+ (1,0) [0|1] "" Vector__XXX
 SG_ TAS_a308_endstopBoundaryRbnd m5 : 11|1@1+ (1,0) [0|1] "" Vector__XXX
 SG_ TAS_a309_controlFrozen m5 : 12|1@1+ (1,0) [0|1] "" Vector__XXX
 SG_ TAS_a310_controlFrozenData m5 : 13|1@1+ (1,0) [0|1] "" Vector__XXX
 SG_ TAS_a311_accelsMIA m5 : 14|1@1+ (1,0) [0|1] "" Vector__XXX
 SG_ TAS_a312_rotationalRatesMIA m5 : 15|1@1+ (1,0) [0|1] "" Vector__XXX
 SG_ TAS_a313_dampingCntrlDisabled m5 : 16|1@1+ (1,0) [0|1] "" Vector__XXX
 SG_ TAS_a314_dampingReduced m5 : 17|1@1+ (1,0) [0|1] "" Vector__XXX
 SG_ TAS_a315_pcbaHighTemp m5 : 18|1@1+ (1,0) [0|1] "" Vector__XXX
 SG_ TAS_a316_offsetsAccels m5 : 19|1@1+ (1,0) [0|1] "" Vector__XXX
 SG_ TAS_a317_offsetsRotationalRates m5 : 20|1@1+ (1,0) [0|1] "" Vector__XXX
 SG_ TAS_a318_dampingCntrlInputMIA m5 : 21|1@1+ (1,0) [0|1] "" Vector__XXX
 SG_ TAS_a319_drivetrainTypeMismatch m5 : 22|1@1+ (1,0) [0|1] "" Vector__XXX
 SG_ TAS_a320_offsetsRotationalRates m5 : 23|1@1+ (1,0) [0|1] "" Vector__XXX
 SG_ TAS_a321_speedBumpAttributes1 m5 : 24|1@1+ (1,0) [0|1] "" Vector__XXX
 SG_ TAS_a322_speedBumpAttributes2 m5 : 25|1@1+ (1,0) [0|1] "" Vector__XXX
 SG_ TAS_a332_levelingThresholds1 m5 : 35|1@1+ (1,0) [0|1] "" Vector__XXX
 SG_ TAS_a333_levelingThresholds2 m5 : 36|1@1+ (1,0) [0|1] "" Vector__XXX

BO_ 523 TAS_axleData: 8 TAS
 SG_ TAS_axleIndex M : 0|1@1+ (1,0) [0|1] "" Vector__XXX
 SG_ TAS_rawHeightFL m0 : 4|10@1+ (1,-512) [-512|510] "mm" Vector__XXX
 SG_ TAS_staticHeightEstimateFL m0 : 14|10@1+ (1,-512) [-512|510] "mm" Vector__XXX
 SG_ TAS_componentPressureFL m0 : 24|8@1+ (0.1,0) [0|25.4] "bara" Vector__XXX
 SG_ TAS_rawHeightFR m0 : 32|10@1+ (1,-512) [-512|510] "mm" Vector__XXX
 SG_ TAS_staticHeightEstimateFR m0 : 42|10@1+ (1,-512) [-512|510] "mm" Vector__XXX
 SG_ TAS_componentPressureFR m0 : 52|8@1+ (0.1,0) [0|25.4] "bara" Vector__XXX
 SG_ TAS_rawHeightRL m1 : 4|10@1+ (1,-512) [-512|510] "mm" Vector__XXX
 SG_ TAS_staticHeightEstimateRL m1 : 14|10@1+ (1,-512) [-512|510] "mm" Vector__XXX
 SG_ TAS_componentPressureRL m1 : 24|8@1+ (0.1,0) [0|25.4] "bara" Vector__XXX
 SG_ TAS_rawHeightRR m1 : 32|10@1+ (1,-512) [-512|510] "mm" Vector__XXX
 SG_ TAS_staticHeightEstimateRR m1 : 42|10@1+ (1,-512) [-512|510] "mm" Vector__XXX
 SG_ TAS_componentPressureRR m1 : 52|8@1+ (0.1,0) [0|25.4] "bara" Vector__XXX

BO_ 1398 TAS_dampingStates: 8 TAS
 SG_ TAS_endstopState : 0|1@1+ (1,0) [0|1] "" Vector__XXX
 SG_ TAS_continuousControlState : 1|1@1+ (1,0) [0|1] "" Vector__XXX
 SG_ TAS_activeTireTune : 2|1@1+ (1,0) [0|1] "" Vector__XXX
 SG_ TAS_roughnessRaiseReason : 3|2@1+ (1,0) [0|3] "" Vector__XXX
 SG_ TAS_frontMetricDrivesRear : 5|2@1+ (1,0) [0|3] "" Vector__XXX
 SG_ TAS_roadCondition : 8|8@1+ (0.005,0) [0|1.27] "-" Vector__XXX
 SG_ TAS_bellyProtect : 16|2@1+ (1,0) [0|3] "" Vector__XXX
 SG_ TAS_frontMetricDrivesFront : 18|2@1+ (1,0) [0|3] "" Vector__XXX
 SG_ TAS_speedBumpAxleFront : 20|3@1+ (1,0) [0|7] "" Vector__XXX
 SG_ TAS_speedBumpAxleRear : 23|3@1+ (1,0) [0|7] "" Vector__XXX
 SG_ TAS_holeProtectFL : 26|2@1+ (1,0) [0|3] "" Vector__XXX
 SG_ TAS_holeProtectFR : 28|2@1+ (1,0) [0|3] "" Vector__XXX
 SG_ TAS_holeProtectRL : 30|2@1+ (1,0) [0|3] "" Vector__XXX
 SG_ TAS_holeProtectRR : 32|2@1+ (1,0) [0|3] "" Vector__XXX
 SG_ TAS_stepProtectFL : 34|2@1+ (1,0) [0|3] "" Vector__XXX
 SG_ TAS_stepProtectFR : 36|2@1+ (1,0) [0|3] "" Vector__XXX
 SG_ TAS_stepProtectRL : 38|2@1+ (1,0) [0|3] "" Vector__XXX
 SG_ TAS_stepProtectRR : 40|2@1+ (1,0) [0|3] "" Vector__XXX
 SG_ TAS_FDUTorqueCorruptionScale : 42|4@1+ (0.075,0) [0|1.05] "-" Vector__XXX
 SG_ TAS_sprungMassEstimate : 46|5@1+ (64,1800) [1800|3720] "kg" Vector__XXX
 SG_ TAS_anyDamperActive : 51|1@1+ (1,0) [0|1] "" Vector__XXX
 SG_ TAS_dampingStatesCounter : 52|4@1+ (1,0) [0|15] "" Vector__XXX
 SG_ TAS_dampingStatesChecksum : 56|8@1+ (1,0) [0|255] "" Vector__XXX

BO_ 1357 TAS_info: 8 TAS
 SG_ TAS_infoIndex M : 0|8@1+ (1,0) [0|255] "" Vector__XXX
 SG_ TAS_infoBuildType m10 : 8|8@1+ (1,0) [0|255] "" Vector__XXX
 SG_ TAS_infoBuildConfigId m10 : 16|16@1+ (1,0) [0|65535] "" Vector__XXX
 SG_ TAS_infoHardwareId m10 : 32|1@1+ (1,0) [0|1] "" Vector__XXX
 SG_ TAS_infoComponentId m10 : 48|16@1+ (1,0) [0|65535] "" Vector__XXX
 SG_ TAS_infoPcbaId m11 : 16|8@1+ (1,0) [0|255] "" Vector__XXX
 SG_ TAS_infoAssemblyId m11 : 24|8@1+ (1,0) [0|254] "" Vector__XXX
 SG_ TAS_infoUsageId m11 : 32|16@1+ (1,0) [0|65535] "" Vector__XXX
 SG_ TAS_infoSubUsageId m11 : 48|16@1+ (1,0) [0|65535] "" Vector__XXX
 SG_ TAS_infoAppCrc m13 : 32|32@1+ (1,0) [0|4294967295] "" Vector__XXX
 SG_ TAS_infoAppGitHash m17 : 8|56@1+ (1,0) [0|7.20575940379e+16] "" Vector__XXX
 SG_ TAS_infoBootGitHash m18 : 8|56@1+ (1,0) [0|7.20575940379e+16] "" Vector__XXX
 SG_ TAS_infoPlatformType m19 : 8|8@1+ (1,0) [0|255] "" Vector__XXX
 SG_ TAS_infoMajorVersion m19 : 16|8@1+ (1,0) [0|254] "" Vector__XXX
 SG_ TAS_infoBranchOrigin m19 : 24|8@1+ (1,0) [0|254] "" Vector__XXX
 SG_ TAS_infoMaturity m19 : 32|8@1+ (1,0) [0|254] "" Vector__XXX
 SG_ TAS_infoHardwareRevision m19 : 40|8@1+ (1,0) [0|254] "" Vector__XXX

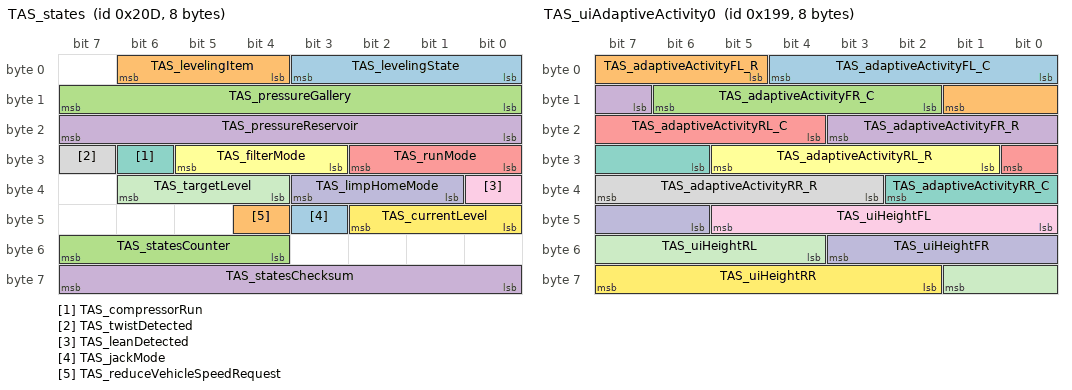
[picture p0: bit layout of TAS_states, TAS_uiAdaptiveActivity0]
BO_ 525 TAS_states: 8 TAS
 SG_ TAS_levelingState : 0|4@1+ (1,0) [0|15] "" Vector__XXX
 SG_ TAS_levelingItem : 4|3@1+ (1,0) [0|7] "" Vector__XXX
 SG_ TAS_pressureGallery : 8|8@1+ (0.1,0) [0|25.4] "bara" Vector__XXX
 SG_ TAS_pressureReservoir : 16|8@1+ (0.1,0) [0|25.4] "bara" Vector__XXX
 SG_ TAS_runMode : 24|3@1+ (1,0) [0|7] "" Vector__XXX
 SG_ TAS_filterMode : 27|3@1+ (1,0) [0|7] "" Vector__XXX
 SG_ TAS_compressorRun : 30|1@1+ (1,0) [0|1] "" Vector__XXX
 SG_ TAS_twistDetected : 31|1@1+ (1,0) [0|1] "" Vector__XXX
 SG_ TAS_leanDetected : 32|1@1+ (1,0) [0|1] "" Vector__XXX
 SG_ TAS_limpHomeMode : 33|3@1+ (1,0) [0|7] "" Vector__XXX
 SG_ TAS_targetLevel : 36|3@1+ (1,0) [0|7] "" Vector__XXX
 SG_ TAS_currentLevel : 40|3@1+ (1,0) [0|7] "" Vector__XXX
 SG_ TAS_jackMode : 43|1@1+ (1,0) [0|1] "" Vector__XXX
 SG_ TAS_reduceVehicleSpeedRequest : 44|1@1+ (1,0) [0|1] "" Vector__XXX
 SG_ TAS_statesCounter : 52|4@1+ (1,0) [0|15] "" Vector__XXX
 SG_ TAS_statesChecksum : 56|8@1+ (1,0) [0|255] "" Vector__XXX

BO_ 1627 TAS_udsResponse: 8 TAS
 SG_ TAS_udsResponseData : 7|64@0+ (1,0) [0|1.84467440737e+19] "" Vector__XXX

BO_ 409 TAS_uiAdaptiveActivity0: 8 TAS
 SG_ TAS_adaptiveActivityFL_C : 0|5@1+ (0.04,0) [0|1] "-" Vector__XXX
 SG_ TAS_adaptiveActivityFL_R : 5|5@1+ (0.04,0) [0|1] "-" Vector__XXX
 SG_ TAS_adaptiveActivityFR_C : 10|5@1+ (0.04,0) [0|1] "-" Vector__XXX
 SG_ TAS_adaptiveActivityFR_R : 15|5@1+ (0.04,0) [0|1] "-" Vector__XXX
 SG_ TAS_adaptiveActivityRL_C : 20|5@1+ (0.04,0) [0|1] "-" Vector__XXX
 SG_ TAS_adaptiveActivityRL_R : 25|5@1+ (0.04,0) [0|1] "-" Vector__XXX
 SG_ TAS_adaptiveActivityRR_C : 30|5@1+ (0.04,0) [0|1] "-" Vector__XXX
 SG_ TAS_adaptiveActivityRR_R : 35|5@1+ (0.04,0) [0|1] "-" Vector__XXX
 SG_ TAS_uiHeightFL : 40|6@1+ (4,-128) [-128|120] "mm" Vector__XXX
 SG_ TAS_uiHeightFR : 46|6@1+ (4,-128) [-128|120] "mm" Vector__XXX
 SG_ TAS_uiHeightRL : 52|6@1+ (4,-128) [-128|120] "mm" Vector__XXX
 SG_ TAS_uiHeightRR : 58|6@1+ (4,-128) [-128|120] "mm" Vector__XXX

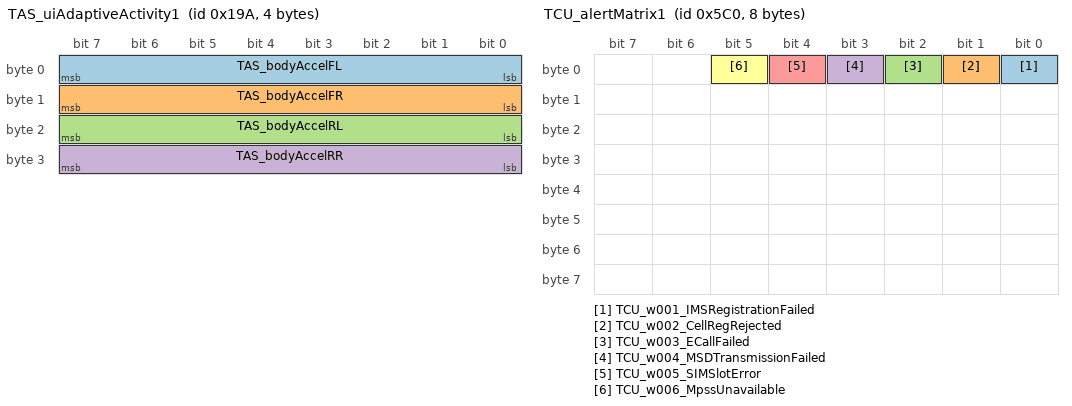
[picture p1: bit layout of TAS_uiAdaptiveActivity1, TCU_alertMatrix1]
BO_ 410 TAS_uiAdaptiveActivity1: 4 TAS
 SG_ TAS_bodyAccelFL : 0|8@1+ (0.05,-5) [-5|5] "g" Vector__XXX
 SG_ TAS_bodyAccelFR : 8|8@1+ (0.05,-5) [-5|5] "g" Vector__XXX
 SG_ TAS_bodyAccelRL : 16|8@1+ (0.05,-5) [-5|5] "g" Vector__XXX
 SG_ TAS_bodyAccelRR : 24|8@1+ (0.05,-5) [-5|5] "g" Vector__XXX

BO_ 538 TAS_uiControl: 5 TAS
 SG_ TAS_yellowWarningLamp : 0|1@1+ (1,0) [0|1] "" Vector__XXX
 SG_ TAS_redWarningLamp : 1|1@1+ (1,0) [0|1] "" Vector__XXX
 SG_ TAS_veryLowAllowed : 2|1@1+ (1,0) [0|1] "" Vector__XXX
 SG_ TAS_lowAllowed : 3|1@1+ (1,0) [0|1] "" Vector__XXX
 SG_ TAS_standardAllowed : 4|1@1+ (1,0) [0|1] "" Vector__XXX
 SG_ TAS_highAllowed : 5|1@1+ (1,0) [0|1] "" Vector__XXX
 SG_ TAS_veryHighAllowed : 6|1@1+ (1,0) [0|1] "" Vector__XXX
 SG_ TAS_extractAllowed : 7|1@1+ (1,0) [0|1] "" Vector__XXX
 SG_ TAS_showSpinner : 9|1@1+ (1,0) [0|1] "" Vector__XXX
 SG_ TAS_adaptiveRideModeOverride : 10|2@1+ (1,0) [0|2] "" Vector__XXX
 SG_ TAS_levelSelectEnabled : 12|1@1+ (1,0) [0|1] "" Vector__XXX
 SG_ TAS_jackModeToggleEnabled : 13|1@1+ (1,0) [0|1] "" Vector__XXX
 SG_ TAS_adaptiveRideSelectEnabled : 14|1@1+ (1,0) [0|1] "" Vector__XXX
 SG_ TAS_launchModeState : 16|3@1+ (1,0) [0|7] "" Vector__XXX
 SG_ TAS_restrictUpLevelingFalcons : 19|1@1+ (1,0) [0|1] "" Vector__XXX
 SG_ TAS_restrictUpLevelingTrunk : 20|1@1+ (1,0) [0|1] "" Vector__XXX
 SG_ TAS_restrictDownLevelingDoors : 21|1@1+ (1,0) [0|1] "" Vector__XXX
 SG_ TAS_restrictLevelingChargeCable : 22|1@1+ (1,0) [0|1] "" Vector__XXX
 SG_ TAS_restrictLevelingSystemCheck : 23|1@1+ (1,0) [0|1] "" Vector__XXX
 SG_ TAS_restrictLevelingTransport : 24|1@1+ (1,0) [0|1] "" Vector__XXX
 SG_ TAS_restrictLevelingShowroom : 25|1@1+ (1,0) [0|1] "" Vector__XXX
 SG_ TAS_uiControlCounter : 28|4@1+ (1,0) [0|15] "" Vector__XXX
 SG_ TAS_uiControlChecksum : 32|8@1+ (1,0) [0|255] "" Vector__XXX

BO_ 1410 TCU_alertLog: 8 TCU
 SG_ TCU_alertID M : 0|3@1+ (1,0) [0|7] "" Vector__XXX
 SG_ TCU_alertState : 15|1@1+ (1,0) [0|1] "" Vector__XXX
 SG_ TCU_w001_FailCode m1 : 16|32@1+ (1,0) [0|4294967295] "" Vector__XXX
 SG_ TCU_w002_RejCause m2 : 16|32@1+ (1,0) [0|4294967295] "" Vector__XXX
 SG_ TCU_w003_CallFailCode m3 : 16|32@1+ (1,0) [0|4294967295] "" Vector__XXX
 SG_ TCU_w004_MSDFailCode m4 : 16|32@1+ (1,0) [0|4294967295] "" Vector__XXX
 SG_ TCU_w006_Count m6 : 16|32@1+ (1,0) [0|4294967295] "" Vector__XXX

BO_ 1472 TCU_alertMatrix1: 8 TCU
 SG_ TCU_w001_IMSRegistrationFailed : 0|1@1+ (1,0) [0|1] "" Vector__XXX
 SG_ TCU_w002_CellRegRejected : 1|1@1+ (1,0) [0|1] "" Vector__XXX
 SG_ TCU_w003_ECallFailed : 2|1@1+ (1,0) [0|1] "" Vector__XXX
 SG_ TCU_w004_MSDTransmissionFailed : 3|1@1+ (1,0) [0|1] "" Vector__XXX
 SG_ TCU_w005_SIMSlotError : 4|1@1+ (1,0) [0|1] "" Vector__XXX
 SG_ TCU_w006_MpssUnavailable : 5|1@1+ (1,0) [0|1] "" Vector__XXX

BO_ 1409 TCU_log: 8 TCU
 SG_ TCU_logMux M : 0|32@1+ (1,0) [0|4294967295] "" Vector__XXX
 SG_ TCU_cpuTemp m0 : 32|32@1+ (1,0) [0|4294967295] "C" Vector__XXX
 SG_ TCU_cpuUsage m1 : 32|32@1+ (1,0) [0|4294967295] "%" Vector__XXX
 SG_ TCU_mdmCoreTemperature m2 : 32|32@1+ (1,0) [0|4294967295] "C" Vector__XXX
 SG_ TCU_availableMemory m3 : 32|32@1+ (1,0) [0|4294967295] "KB" Vector__XXX
 SG_ TCU_pwm m4 : 32|32@1+ (1,0) [0|4294967295] "" Vector__XXX
 SG_ TCU_pwmcap m5 : 32|32@1+ (1,0) [0|4294967295] "" Vector__XXX
 SG_ TCU_totalResumes m6 : 32|32@1+ (1,0) [0|4294967295] "" Vector__XXX
 SG_ TCU_mdmUplinkQueueSize m7 : 32|32@1+ (1,0) [0|4294967295] "bytes" Vector__XXX
 SG_ TCU_mdmRSRP m8 : 32|32@1- (1,0) [-2147483648|2147483647] "dBm" Vector__XXX
 SG_ TCU_mdmSINR m9 : 32|32@1- (1,0) [-2147483648|2147483647] "dBm" Vector__XXX
 SG_ TCU_mdmUplinkAllowedRate m10 : 32|32@1+ (1,0) [0|4294967295] "Kbps" Vector__XXX
 SG_ TCU_mdmUplinkAvgRage m11 : 32|32@1+ (1,0) [0|4294967295] "" Vector__XXX
 SG_ TCU_mdmServiceState m12 : 32|32@1+ (1,0) [0|4294967295] "" Vector__XXX
 SG_ TCU_mdmIMSStatus m13 : 32|32@1+ (1,0) [0|4294967295] "" Vector__XXX
 SG_ TCU_mdmSIMStatus m14 : 32|32@1+ (1,0) [0|4294967295] "" Vector__XXX
 SG_ TCU_mdmBusyActive m15 : 32|32@1+ (1,0) [0|4294967294] "" Vector__XXX

BO_ 1408 TCU_status: 8 TCU
 SG_ TCU_statusMux M : 0|32@1+ (1,0) [0|4294967295] "" Vector__XXX
 SG_ TCU_wakeUpReason m0 : 32|32@1+ (1,0) [0|4294967294] "" Vector__XXX
 SG_ TCU_tcuCmdId m1 : 32|1@1+ (1,0) [0|1] "" Vector__XXX
 SG_ TCU_goingToSleep m2 : 32|32@1+ (1,0) [0|4294967294] "" Vector__XXX

BO_ 879 TPMS_StatusC: 8 TPMS
 SG_ TPMS_c_globalHardWarning : 0|1@1+ (1,0) [0|1] "" Vector__XXX
 SG_ TPMS_c_globalSoftWarning : 1|1@1+ (1,0) [0|1] "" Vector__XXX
 SG_ TPMS_systemMalfunction : 2|1@1+ (1,0) [0|1] "" Vector__XXX
 SG_ TPMS_WA_version : 3|1@1+ (1,0) [0|1] "" Vector__XXX
 SG_ TPMS_globalDeltaPressure : 4|1@1+ (1,0) [0|1] "" Vector__XXX
 SG_ TPMS_newSensorLearnt : 5|3@1+ (1,0) [0|7] "" Vector__XXX
 SG_ TPMS_softWarningRR : 8|1@1+ (1,0) [0|1] "" Vector__XXX
 SG_ TPMS_hardWarningRR : 9|1@1+ (1,0) [0|1] "" Vector__XXX
 SG_ TPMS_softWarningRL : 10|1@1+ (1,0) [0|1] "" Vector__XXX
 SG_ TPMS_hardWarningRL : 11|1@1+ (1,0) [0|1] "" Vector__XXX
 SG_ TPMS_softWarningFR : 12|1@1+ (1,0) [0|1] "" Vector__XXX
 SG_ TPMS_hardWarningFR : 13|1@1+ (1,0) [0|1] "" Vector__XXX
 SG_ TPMS_softWarningFL : 14|1@1+ (1,0) [0|1] "" Vector__XXX
 SG_ TPMS_hardWarningFL : 15|1@1+ (1,0) [0|1] "" Vector__XXX
 SG_ TPMS_learningStatus : 16|2@1+ (1,0) [0|3] "" Vector__XXX
 SG_ TPMS_localisationStatus : 18|2@1+ (1,0) [0|3] "" Vector__XXX
 SG_ TPMS_deltaPressWarningFL : 20|1@1+ (1,0) [0|1] "" Vector__XXX
 SG_ TPMS_deltaPressWarningFR : 21|1@1+ (1,0) [0|1] "" Vector__XXX
 SG_ TPMS_deltaPressWarningRL : 22|1@1+ (1,0) [0|1] "" Vector__XXX
 SG_ TPMS_deltaPressWarningRR : 23|1@1+ (1,0) [0|1] "" Vector__XXX
 SG_ TPMS_sensorNoResponseFL : 24|1@1+ (1,0) [0|1] "" Vector__XXX
 SG_ TPMS_sensorNoResponseFR : 25|1@1+ (1,0) [0|1] "" Vector__XXX
 SG_ TPMS_sensorNoResponseRL : 26|1@1+ (1,0) [0|1] "" Vector__XXX
 SG_ TPMS_sensorNoResponseRR : 27|1@1+ (1,0) [0|1] "" Vector__XXX
 SG_ TPMS_sensorThermShutdownFL : 28|1@1+ (1,0) [0|1] "" Vector__XXX
 SG_ TPMS_sensorThermShutdownFR : 29|1@1+ (1,0) [0|1] "" Vector__XXX
 SG_ TPMS_sensorThermShutdownRL : 30|1@1+ (1,0) [0|1] "" Vector__XXX
 SG_ TPMS_sensorThermShutdownRR : 31|1@1+ (1,0) [0|1] "" Vector__XXX
 SG_ TPMS_sensorBatteryLowFL : 32|1@1+ (1,0) [0|1] "" Vector__XXX
 SG_ TPMS_sensorBatteryLowFR : 33|1@1+ (1,0) [0|1] "" Vector__XXX
 SG_ TPMS_sensorBatteryLowRL : 34|1@1+ (1,0) [0|1] "" Vector__XXX
 SG_ TPMS_sensorBatteryLowRR : 35|1@1+ (1,0) [0|1] "" Vector__XXX
 SG_ TPMS_sensorDefectiveFL : 36|1@1+ (1,0) [0|1] "" Vector__XXX
 SG_ TPMS_sensorDefectiveFR : 37|1@1+ (1,0) [0|1] "" Vector__XXX
 SG_ TPMS_sensorDefectiveRL : 38|1@1+ (1,0) [0|1] "" Vector__XXX
 SG_ TPMS_sensorDefectiveRR : 39|1@1+ (1,0) [0|1] "" Vector__XXX
 SG_ TPMS_ecuUnderVoltage : 40|1@1+ (1,0) [0|1] "" Vector__XXX
 SG_ TPMS_ecuOverVoltage : 41|1@1+ (1,0) [0|1] "" Vector__XXX
 SG_ TPMS_ecuRamRomNvMFail : 42|1@1+ (1,0) [0|1] "" Vector__XXX
 SG_ TPMS_rfReceiverFail : 43|1@1+ (1,0) [0|1] "" Vector__XXX
 SG_ TPMS_wheelPulseMissing : 44|1@1+ (1,0) [0|1] "" Vector__XXX
 SG_ TPMS_vehicleSpeedFail : 45|1@1+ (1,0) [0|1] "" Vector__XXX
 SG_ TPMS_externalTemperatureFail : 46|1@1+ (1,0) [0|1] "" Vector__XXX
 SG_ TPMS_eolNotCompleted : 47|1@1+ (1,0) [0|1] "" Vector__XXX
 SG_ TPMS_rcpFront : 48|8@1+ (0.025,0) [0|6.375] "bar" Vector__XXX
 SG_ TPMS_rcpRear : 56|8@1+ (0.025,0) [0|6.375] "bar" Vector__XXX

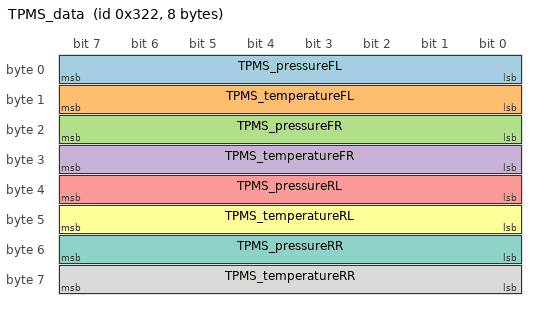
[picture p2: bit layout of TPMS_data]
BO_ 802 TPMS_data: 8 TPMS
 SG_ TPMS_pressureFL : 0|8@1+ (0.025,0) [0|6.35] "bar" Vector__XXX
 SG_ TPMS_temperatureFL : 8|8@1+ (1,-40) [-40|214] "degC" Vector__XXX
 SG_ TPMS_pressureFR : 16|8@1+ (0.025,0) [0|6.35] "bar" Vector__XXX
 SG_ TPMS_temperatureFR : 24|8@1+ (1,-40) [-40|214] "degC" Vector__XXX
 SG_ TPMS_pressureRL : 32|8@1+ (0.025,0) [0|6.35] "bar" Vector__XXX
 SG_ TPMS_temperatureRL : 40|8@1+ (1,-40) [-40|214] "degC" Vector__XXX
 SG_ TPMS_pressureRR : 48|8@1+ (0.025,0) [0|6.35] "bar" Vector__XXX
 SG_ TPMS_temperatureRR : 56|8@1+ (1,-40) [-40|214] "degC" Vector__XXX

BO_ 1519 TPMS_info: 8 TPMS
 SG_ TPMS_infoIndex M : 0|8@1+ (1,0) [0|255] "" Vector__XXX
 SG_ TPMS_infoComponentID m10 : 48|16@1+ (1,0) [0|65535] "" Vector__XXX
 SG_ TPMS_infoPcbaID m11 : 16|8@1+ (1,0) [0|255] "" Vector__XXX
 SG_ TPMS_infoAssemblyID m11 : 24|8@1+ (1,0) [0|255] "" Vector__XXX
 SG_ TPMS_infoUsageID m11 : 32|16@1+ (1,0) [0|65535] "" Vector__XXX
 SG_ TPMS_infoApplicationCRC m13 : 32|32@1+ (1,0) [0|4294967295] "" Vector__XXX
 SG_ TPMS_infoBootUdsProtoVersion m20 : 8|8@1+ (1,0) [0|255] "" Vector__XXX
 SG_ TPMS_infoBootloaderCRC m20 : 32|32@1+ (1,0) [0|4294967295] "" Vector__XXX

BO_ 1631 TPMS_udsResponse: 8 TPMS
 SG_ TPMS_udsResponseData : 7|64@0+ (1,0) [0|1.84467440737e+19] "" Vector__XXX

BO_TX_BU_ 1835 : TAS;
BO_TX_BU_ 852 : TAS;
BO_TX_BU_ 523 : TAS;
BO_TX_BU_ 1398 : TAS;
BO_TX_BU_ 1357 : TAS;
BO_TX_BU_ 525 : TAS;
BO_TX_BU_ 1627 : TAS;
BO_TX_BU_ 409 : TAS;
BO_TX_BU_ 410 : TAS;
BO_TX_BU_ 538 : TAS;
BO_TX_BU_ 1410 : TCU;
BO_TX_BU_ 1472 : TCU;
BO_TX_BU_ 1409 : TCU;
BO_TX_BU_ 1408 : TCU;
BO_TX_BU_ 879 : TPMS;
BO_TX_BU_ 802 : TPMS;
BO_TX_BU_ 1519 : TPMS;
BO_TX_BU_ 1631 : TPMS;
CM_ BO_ 1835 "Air suspension controller message: alert log";
CM_ SG_ 1835 TAS_alertID "Air suspension controller: alert ID";
CM_ SG_ 1835 TAS_alertState "Air suspension controller: alert state";
CM_ SG_ 1835 TAS_a001_InternalWatchdog "Air suspension controller: a001 internal watchdog";
CM_ SG_ 1835 TAS_a002_CPUUndervoltage "Air suspension controller: a002 CPU undervoltage";
CM_ SG_ 1835 TAS_a002_PowerOnReset "Air suspension controller: a002 power on reset";
CM_ SG_ 1835 TAS_a003_AssertID "Air suspension controller: a003 assert ID";
CM_ SG_ 1835 TAS_a003_LineNumber "Air suspension controller: a003 line number";
CM_ SG_ 1835 TAS_a003_Data "Air suspension controller: a003 data";
CM_ SG_ 1835 TAS_a012_ClockError "Air suspension controller: a012 clock error";
CM_ SG_ 1835 TAS_a012_FlashError "Air suspension controller: a012 flash error";
CM_ SG_ 1835 TAS_a012_SoftwareReset "Air suspension controller: a012 software reset";
CM_ SG_ 1835 TAS_a012_CheckstopReset "Air suspension controller: a012 checkstop reset";
CM_ SG_ 1835 TAS_a012_DebugReset "Air suspension controller: a012 debug reset";
CM_ SG_ 1835 TAS_a012_ExternalReset "Air suspension controller: a012 external reset";
CM_ SG_ 1835 TAS_a021_Task1msLate "Air suspension controller: a021 task1ms late";
CM_ SG_ 1835 TAS_a021_Task1msStarved "Air suspension controller: a021 task1ms starved";
CM_ SG_ 1835 TAS_a021_Task1msMissed "Air suspension controller: a021 task1ms missed";
CM_ SG_ 1835 TAS_a021_Task10msLate "Air suspension controller: a021 task10ms late";
CM_ SG_ 1835 TAS_a021_Task10msStarved "Air suspension controller: a021 task10ms starved";
CM_ SG_ 1835 TAS_a021_Task10msMissed "Air suspension controller: a021 task10ms missed";
CM_ SG_ 1835 TAS_a021_Task100msLate "Air suspension controller: a021 task100ms late";
CM_ SG_ 1835 TAS_a021_Task100msStarved "Air suspension controller: a021 task100ms starved";
CM_ SG_ 1835 TAS_a021_Task100msMissed "Air suspension controller: a021 task100ms missed";
CM_ SG_ 1835 TAS_a021_Task1000msLate "Air suspension controller: a021 task1000ms late";
CM_ SG_ 1835 TAS_a021_Task1000msStarved "Air suspension controller: a021 task1000ms starved";
CM_ SG_ 1835 TAS_a021_Task1000msMissed "Air suspension controller: a021 task1000ms missed";
CM_ SG_ 1835 TAS_a022_TaskInitErrorCount "Air suspension controller: a022 task init error count";
CM_ SG_ 1835 TAS_a022_TaskInitError0 "Air suspension controller: a022 task init error0";
CM_ SG_ 1835 TAS_a022_TaskInitError1 "Air suspension controller: a022 task init error1";
CM_ SG_ 1835 TAS_a022_TaskInitError2 "Air suspension controller: a022 task init error2";
CM_ SG_ 1835 TAS_a022_TaskInitError3 "Air suspension controller: a022 task init error3";
CM_ SG_ 1835 TAS_a022_TaskInitError4 "Air suspension controller: a022 task init error4";
CM_ SG_ 1835 TAS_a025_vehicleLockAtCrash "Air suspension controller: a025 vehicle lock at crash";
CM_ SG_ 1835 TAS_a025_CANCrashIsActive "Air suspension controller: a025 CAN crash is active";
CM_ SG_ 1835 TAS_a025_appCrashIsActive "Air suspension controller: a025 app crash is active";
CM_ SG_ 1835 TAS_a025_lastCrashEvent "Air suspension controller: a025 last crash event";
CM_ SG_ 1835 TAS_a030_PWMdutyCycleFL "Air suspension controller: a030 PW mduty cycle FL";
CM_ SG_ 1835 TAS_a030_PWMfrequencyFL "Air suspension controller: a030 PW mfrequency FL";
CM_ SG_ 1835 TAS_a030_PWMfaultFL "Air suspension controller: a030 PW mfault FL";
CM_ SG_ 1835 TAS_a031_PWMdutyCycleFR "Air suspension controller: a031 PW mduty cycle FR";
CM_ SG_ 1835 TAS_a031_PWMfrequencyFR "Air suspension controller: a031 PW mfrequency FR";
CM_ SG_ 1835 TAS_a031_PWMfaultFR "Air suspension controller: a031 PW mfault FR";
CM_ SG_ 1835 TAS_a032_PWMdutyCycleRL "Air suspension controller: a032 PW mduty cycle RL";
CM_ SG_ 1835 TAS_a032_PWMfrequencyRL "Air suspension controller: a032 PW mfrequency RL";
CM_ SG_ 1835 TAS_a032_PWMfaultRL "Air suspension controller: a032 PW mfault RL";
CM_ SG_ 1835 TAS_a033_PWMdutyCycleRR "Air suspension controller: a033 PW mduty cycle RR";
CM_ SG_ 1835 TAS_a033_PWMfrequencyRR "Air suspension controller: a033 PW mfrequency RR";
CM_ SG_ 1835 TAS_a033_PWMfaultRR "Air suspension controller: a033 PW mfault RR";
CM_ SG_ 1835 TAS_a034_PWMdutyCycleFL "Air suspension controller: a034 PW mduty cycle FL";
CM_ SG_ 1835 TAS_a034_PWMfrequencyFL "Air suspension controller: a034 PW mfrequency FL";
CM_ SG_ 1835 TAS_a034_PWMfaultFL "Air suspension controller: a034 PW mfault FL";
CM_ SG_ 1835 TAS_a035_PWMdutyCycleFR "Air suspension controller: a035 PW mduty cycle FR";
CM_ SG_ 1835 TAS_a035_PWMfrequencyFR "Air suspension controller: a035 PW mfrequency FR";
CM_ SG_ 1835 TAS_a035_PWMfaultFR "Air suspension controller: a035 PW mfault FR";
CM_ SG_ 1835 TAS_a036_PWMdutyCycleRL "Air suspension controller: a036 PW mduty cycle RL";
CM_ SG_ 1835 TAS_a036_PWMfrequencyRL "Air suspension controller: a036 PW mfrequency RL";
CM_ SG_ 1835 TAS_a036_PWMfaultRL "Air suspension controller: a036 PW mfault RL";
CM_ SG_ 1835 TAS_a037_PWMdutyCycleRR "Air suspension controller: a037 PW mduty cycle RR";
CM_ SG_ 1835 TAS_a037_PWMfrequencyRR "Air suspension controller: a037 PW mfrequency RR";
CM_ SG_ 1835 TAS_a037_PWMfaultRR "Air suspension controller: a037 PW mfault RR";
CM_ SG_ 1835 TAS_a038_PWMdutyCycleFL "Air suspension controller: a038 PW mduty cycle FL";
CM_ SG_ 1835 TAS_a038_PWMfrequencyFL "Air suspension controller: a038 PW mfrequency FL";
CM_ SG_ 1835 TAS_a038_PWMfaultFL "Air suspension controller: a038 PW mfault FL";
CM_ SG_ 1835 TAS_a039_PWMdutyCycleFR "Air suspension controller: a039 PW mduty cycle FR";
CM_ SG_ 1835 TAS_a039_PWMfrequencyFR "Air suspension controller: a039 PW mfrequency FR";
CM_ SG_ 1835 TAS_a039_PWMfaultFR "Air suspension controller: a039 PW mfault FR";
CM_ SG_ 1835 TAS_a040_PWMdutyCycleRL "Air suspension controller: a040 PW mduty cycle RL";
CM_ SG_ 1835 TAS_a040_PWMfrequencyRL "Air suspension controller: a040 PW mfrequency RL";
CM_ SG_ 1835 TAS_a040_PWMfaultRL "Air suspension controller: a040 PW mfault RL";
CM_ SG_ 1835 TAS_a041_PWMdutyCycleRR "Air suspension controller: a041 PW mduty cycle RR";
CM_ SG_ 1835 TAS_a041_PWMfrequencyRR "Air suspension controller: a041 PW mfrequency RR";
CM_ SG_ 1835 TAS_a041_PWMfaultRR "Air suspension controller: a041 PW mfault RR";
CM_ SG_ 1835 TAS_a070_voltage12V "Air suspension controller: a070 voltage12 v";
CM_ SG_ 1835 TAS_a071_voltage12V "Air suspension controller: a071 voltage12 v";
CM_ SG_ 1835 TAS_a072_voltage5VOnBoard "Air suspension controller: a072 voltage5 v on board";
CM_ SG_ 1835 TAS_a073_voltage5VOnBoard "Air suspension controller: a073 voltage5 v on board";
CM_ SG_ 1835 TAS_a074_voltage5VOffBoard "Air suspension controller: a074 voltage5 v off board";
CM_ SG_ 1835 TAS_a075_voltage5VOffBoard "Air suspension controller: a075 voltage5 v off board";
CM_ SG_ 1835 TAS_a076_voltage5VOffBoard "Air suspension controller: a076 voltage5 v off board";
CM_ SG_ 1835 TAS_a077_sensorVoltage "Air suspension controller: a077 sensor voltage";
CM_ SG_ 1835 TAS_a077_sensorRefVoltage "Air suspension controller: a077 sensor ref voltage";
CM_ SG_ 1835 TAS_a078_sensorVoltage "Air suspension controller: a078 sensor voltage";
CM_ SG_ 1835 TAS_a078_sensorRefVoltage "Air suspension controller: a078 sensor ref voltage";
CM_ SG_ 1835 TAS_a080_voltage5VHeight "Air suspension controller: a080 voltage5 v height";
CM_ SG_ 1835 TAS_a081_voltage5VHeight "Air suspension controller: a081 voltage5 v height";
CM_ SG_ 1835 TAS_a082_voltage5VHeight "Air suspension controller: a082 voltage5 v height";
CM_ SG_ 1835 TAS_a083_voltage5VAnalog "Air suspension controller: a083 voltage5 v analog";
CM_ SG_ 1835 TAS_a084_voltage5VAnalog "Air suspension controller: a084 voltage5 v analog";
CM_ SG_ 1835 TAS_a085_voltage5VAnalog "Air suspension controller: a085 voltage5 v analog";
CM_ SG_ 1835 TAS_a086_voltage12VSwitched "Air suspension controller: a086 voltage12 v switched";
CM_ SG_ 1835 TAS_a087_voltage12VSwitched "Air suspension controller: a087 voltage12 v switched";
CM_ SG_ 1835 TAS_a093_readError "Air suspension controller: a093 read error";
CM_ SG_ 1835 TAS_a093_IVOR2Exception "Air suspension controller: a093 IVOR2 exception";
CM_ SG_ 1835 TAS_a098_VCFRONT_LVPowerState_MI "Air suspension controller: a098 VCFRONT LV power state MIA";
CM_ SG_ 1835 TAS_a098_VCFRONT_sensors_MIA "Air suspension controller: a098 VCFRONT sensors MIA";
CM_ SG_ 1835 TAS_a098_VCFRONT_status_MIA "Air suspension controller: a098 VCFRONT status MIA";
CM_ SG_ 1835 TAS_a098_VCFRONT_systemStatus_MI "Air suspension controller: a098 VCFRONT system status MIA";
CM_ SG_ 1835 TAS_a098_VCFRONT_vehNm_MIA "Air suspension controller: a098 VCFRONT veh nm MIA";
CM_ SG_ 1835 TAS_a099_UI_chassisControl_MIA "Air suspension controller: a099 UI chassis control MIA";
CM_ SG_ 1835 TAS_a099_UI_driverAssistMapData_ "Air suspension controller: a099 UI driver assist map data MIA";
CM_ SG_ 1835 TAS_a099_UI_suspensionControl_MI "Air suspension controller: a099 UI suspension control MIA";
CM_ SG_ 1835 TAS_a099_UI_vehicleModes_MIA "Air suspension controller: a099 UI vehicle modes MIA";
CM_ SG_ 1835 TAS_a100_RCM_inertial1_MIA "Air suspension controller: a100 RCM inertial1 MIA";
CM_ SG_ 1835 TAS_a100_RCM_inertial2_MIA "Air suspension controller: a100 RCM inertial2 MIA";
CM_ SG_ 1835 TAS_a101_ESP_brakeTorque_MIA "Air suspension controller: a101 ESP brake torque MIA";
CM_ SG_ 1835 TAS_a101_ESP_status_MIA "Air suspension controller: a101 ESP status MIA";
CM_ SG_ 1835 TAS_a101_ESP_wheelRotation_MIA "Air suspension controller: a101 ESP wheel rotation MIA";
CM_ SG_ 1835 TAS_a102_DI_chassisControl_MIA "Air suspension controller: a102 DI chassis control MIA";
CM_ SG_ 1835 TAS_a102_DI_locStatus_MIA "Air suspension controller: a102 DI loc status MIA";
CM_ SG_ 1835 TAS_a102_DI_speed_MIA "Air suspension controller: a102 DI speed MIA";
CM_ SG_ 1835 TAS_a102_DI_systemStatus_MIA "Air suspension controller: a102 DI system status MIA";
CM_ SG_ 1835 TAS_a102_DI_vehicleEstimates_MIA "Air suspension controller: a102 DI vehicle estimates MIA";
CM_ SG_ 1835 TAS_a102_DIF_torque_MIA "Air suspension controller: a102 DIF torque MIA";
CM_ SG_ 1835 TAS_a102_DIR_torque_MIA "Air suspension controller: a102 DIR torque MIA";
CM_ SG_ 1835 TAS_a103_GTW_carConfig_MIA "Air suspension controller: a103 GTW car config MIA";
CM_ SG_ 1835 TAS_a103_GTW_time_MIA "Air suspension controller: a103 GTW time MIA";
CM_ SG_ 1835 TAS_a103_GTW_vehNm_MIA "Air suspension controller: a103 GTW veh nm MIA";
CM_ SG_ 1835 TAS_a103_GTW_vin_MIA "Air suspension controller: a103 GTW vin MIA";
CM_ SG_ 1835 TAS_a164_detectedDamperSolenoid "Air suspension controller: a164 detected damper solenoid";
CM_ SG_ 1835 TAS_a164_expectedDamperSolenoid "Air suspension controller: a164 expected damper solenoid";
CM_ SG_ 1835 TAS_a165_damperValveFault "Air suspension controller: a165 damper valve fault";
CM_ SG_ 1835 TAS_a166_damperValveFault "Air suspension controller: a166 damper valve fault";
CM_ SG_ 1835 TAS_a167_damperValveFault "Air suspension controller: a167 damper valve fault";
CM_ SG_ 1835 TAS_a168_damperValveFault "Air suspension controller: a168 damper valve fault";
CM_ SG_ 1835 TAS_a169_damperValveFault "Air suspension controller: a169 damper valve fault";
CM_ SG_ 1835 TAS_a170_damperValveFault "Air suspension controller: a170 damper valve fault";
CM_ SG_ 1835 TAS_a171_damperValveFault "Air suspension controller: a171 damper valve fault";
CM_ SG_ 1835 TAS_a172_damperValveFault "Air suspension controller: a172 damper valve fault";
CM_ SG_ 1835 TAS_a173_heightDelta_mm "Air suspension controller: a173 height delta mm";
CM_ SG_ 1835 TAS_a174_heightDelta_mm "Air suspension controller: a174 height delta mm";
CM_ SG_ 1835 TAS_a175_heightDelta_mm "Air suspension controller: a175 height delta mm";
CM_ SG_ 1835 TAS_a176_heightDelta_mm "Air suspension controller: a176 height delta mm";
CM_ SG_ 1835 TAS_a190_a2bFaultType "Air suspension controller: a190 a2b fault type";
CM_ SG_ 1835 TAS_a190_a2bInterruptType "Air suspension controller: a190 a2b interrupt type";
CM_ SG_ 1835 TAS_a190_a2bFaultSource "Air suspension controller: a190 a2b fault source";
CM_ SG_ 1835 TAS_a191_a2bFaultType "Air suspension controller: a191 a2b fault type";
CM_ SG_ 1835 TAS_a191_a2bInterruptType "Air suspension controller: a191 a2b interrupt type";
CM_ SG_ 1835 TAS_a191_a2bFaultSource "Air suspension controller: a191 a2b fault source";
CM_ SG_ 1835 TAS_a192_rideHeightVelDspFL "Air suspension controller: a192 ride height vel dsp FL";
CM_ SG_ 1835 TAS_a192_rideHeightVelDspFR "Air suspension controller: a192 ride height vel dsp FR";
CM_ SG_ 1835 TAS_a192_rideHeightVelDspRL "Air suspension controller: a192 ride height vel dsp RL";
CM_ SG_ 1835 TAS_a192_rideHeightVelDspRR "Air suspension controller: a192 ride height vel dsp RR";
CM_ SG_ 1835 TAS_a192_rideHeightVelObserverFL "Air suspension controller: a192 ride height vel observer FL";
CM_ SG_ 1835 TAS_a192_rideHeightVelObserverFR "Air suspension controller: a192 ride height vel observer FR";
CM_ SG_ 1835 TAS_a192_rideHeightVelObserverRL "Air suspension controller: a192 ride height vel observer RL";
CM_ SG_ 1835 TAS_a192_rideHeightVelObserverRR "Air suspension controller: a192 ride height vel observer RR";
CM_ SG_ 1835 TAS_a192_alertVersion "Air suspension controller: a192 alert version";
CM_ SG_ 1835 TAS_a193_EPAS3P_sysStatus_MIA "Air suspension controller: a193 EPAS3 p sys status MIA";
CM_ SG_ 1835 TAS_a210_heightSensorDeltaFL "Air suspension controller: a210 height sensor delta FL";
CM_ SG_ 1835 TAS_a210_heightSensorDeltaFR "Air suspension controller: a210 height sensor delta FR";
CM_ SG_ 1835 TAS_a210_heightSensorDeltaRL "Air suspension controller: a210 height sensor delta RL";
CM_ SG_ 1835 TAS_a210_heightSensorDeltaRR "Air suspension controller: a210 height sensor delta RR";
CM_ SG_ 1835 TAS_a220_galleryPressure "Air suspension controller: a220 gallery pressure";
CM_ SG_ 1835 TAS_a220_timeInExhaust "Air suspension controller: a220 time in exhaust";
CM_ SG_ 1835 TAS_a221_galleryPressureDelta "Air suspension controller: a221 gallery pressure delta";
CM_ SG_ 1835 TAS_a221_timeInIdle "Air suspension controller: a221 time in idle";
CM_ SG_ 1835 TAS_a222_galleryPressureDelta "Air suspension controller: a222 gallery pressure delta";
CM_ SG_ 1835 TAS_a223_galleryPressure "Air suspension controller: a223 gallery pressure";
CM_ SG_ 1835 TAS_a223_valveOnFL "Air suspension controller: a223 valve on FL";
CM_ SG_ 1835 TAS_a223_valveOnFR "Air suspension controller: a223 valve on FR";
CM_ SG_ 1835 TAS_a223_valveOnRL "Air suspension controller: a223 valve on RL";
CM_ SG_ 1835 TAS_a223_valveOnRR "Air suspension controller: a223 valve on RR";
CM_ SG_ 1835 TAS_a223_valveOnReservoir "Air suspension controller: a223 valve on reservoir";
CM_ SG_ 1835 TAS_a224_galleryPressure "Air suspension controller: a224 gallery pressure";
CM_ SG_ 1835 TAS_a224_valveOnFL "Air suspension controller: a224 valve on FL";
CM_ SG_ 1835 TAS_a224_valveOnFR "Air suspension controller: a224 valve on FR";
CM_ SG_ 1835 TAS_a224_valveOnRL "Air suspension controller: a224 valve on RL";
CM_ SG_ 1835 TAS_a224_valveOnRR "Air suspension controller: a224 valve on RR";
CM_ SG_ 1835 TAS_a224_valveOnReservoir "Air suspension controller: a224 valve on reservoir";
CM_ SG_ 1835 TAS_a225_galleryPressure "Air suspension controller: a225 gallery pressure";
CM_ SG_ 1835 TAS_a226_PWMdutyCycleFL "Air suspension controller: a226 PW mduty cycle FL";
CM_ SG_ 1835 TAS_a226_PWMfrequencyFL "Air suspension controller: a226 PW mfrequency FL";
CM_ SG_ 1835 TAS_a226_PWMfaultFL "Air suspension controller: a226 PW mfault FL";
CM_ SG_ 1835 TAS_a227_PWMdutyCycleFR "Air suspension controller: a227 PW mduty cycle FR";
CM_ SG_ 1835 TAS_a227_PWMfrequencyFR "Air suspension controller: a227 PW mfrequency FR";
CM_ SG_ 1835 TAS_a227_PWMfaultFR "Air suspension controller: a227 PW mfault FR";
CM_ SG_ 1835 TAS_a228_PWMdutyCycleRL "Air suspension controller: a228 PW mduty cycle RL";
CM_ SG_ 1835 TAS_a228_PWMfrequencyRL "Air suspension controller: a228 PW mfrequency RL";
CM_ SG_ 1835 TAS_a228_PWMfaultRL "Air suspension controller: a228 PW mfault RL";
CM_ SG_ 1835 TAS_a229_PWMdutyCycleRR "Air suspension controller: a229 PW mduty cycle RR";
CM_ SG_ 1835 TAS_a229_PWMfrequencyRR "Air suspension controller: a229 PW mfrequency RR";
CM_ SG_ 1835 TAS_a229_PWMfaultRR "Air suspension controller: a229 PW mfault RR";
CM_ SG_ 1835 TAS_a232_detectedSuspensionType "Air suspension controller: a232 detected suspension type";
CM_ SG_ 1835 TAS_a232_expectedSuspensionType "Air suspension controller: a232 expected suspension type";
CM_ SG_ 1835 TAS_a234_detectedDamperHydraulic "Air suspension controller: a234 detected damper hydraulic";
CM_ SG_ 1835 TAS_a234_expectedDamperHydraulic "Air suspension controller: a234 expected damper hydraulic";
CM_ SG_ 1835 TAS_a240_highAdjustCountRatio "Air suspension controller: a240 high adjust count ratio";
CM_ SG_ 1835 TAS_a240_highAdjustTimeRatio "Air suspension controller: a240 high adjust time ratio";
CM_ SG_ 1835 TAS_a240_highCrossPressure "Air suspension controller: a240 high cross pressure";
CM_ SG_ 1835 TAS_a240_highCompExhTimeRatio "Air suspension controller: a240 high comp exh time ratio";
CM_ SG_ 1835 TAS_a240_adjustCountRatioSpring "Air suspension controller: a240 adjust count ratio spring";
CM_ SG_ 1835 TAS_a240_adjustCountRatio "Air suspension controller: a240 adjust count ratio; raw 255 = signal not available (SNA)";
CM_ SG_ 1835 TAS_a240_adjustTimeRatioSpring "Air suspension controller: a240 adjust time ratio spring";
CM_ SG_ 1835 TAS_a240_adjustTimeRatio "Air suspension controller: a240 adjust time ratio; raw 255 = signal not available (SNA)";
CM_ SG_ 1835 TAS_a240_compExhTimeRatio "Air suspension controller: a240 comp exh time ratio";
CM_ SG_ 1835 TAS_a240_crossPressure "Air suspension controller: a240 cross pressure";
CM_ SG_ 1835 TAS_a285_twistLevel "Air suspension controller: a285 twist level";
CM_ SG_ 1835 TAS_a290_twistLevel "Air suspension controller: a290 twist level";
CM_ SG_ 1835 TAS_a291_frontAxleHeight "Air suspension controller: a291 front axle height";
CM_ SG_ 1835 TAS_a292_rearAxleHeight "Air suspension controller: a292 rear axle height";
CM_ SG_ 1835 TAS_a293_frontAxleHeight "Air suspension controller: a293 front axle height";
CM_ SG_ 1835 TAS_a294_rearAxleHeight "Air suspension controller: a294 rear axle height";
CM_ SG_ 1835 TAS_a295_targetHeight "Air suspension controller: a295 target height";
CM_ SG_ 1835 TAS_a296_detectedChassisType "Air suspension controller: a296 detected chassis type";
CM_ SG_ 1835 TAS_a296_expectedChassisType "Air suspension controller: a296 expected chassis type";
CM_ SG_ 1835 TAS_a319_detectedDrivetrainType "Air suspension controller: a319 detected drivetrain type";
CM_ SG_ 1835 TAS_a319_expectedDrivetrainType "Air suspension controller: a319 expected drivetrain type";
CM_ BO_ 852 "Air suspension controller message: alert matrix";
CM_ SG_ 852 TAS_matrixIndex "Air suspension controller: matrix index";
CM_ SG_ 852 TAS_a001_WatchdogReset "Air suspension controller: a001 watchdog reset";
CM_ SG_ 852 TAS_a002_PowerLossReset "Air suspension controller: a002 power loss reset";
CM_ SG_ 852 TAS_a003_SWAssertion "Air suspension controller: a003 SW assertion";
CM_ SG_ 852 TAS_a012_CPUReset "Air suspension controller: a012 CPU reset";
CM_ SG_ 852 TAS_a015_NVMMError "Air suspension controller: a015 NVMM error";
CM_ SG_ 852 TAS_a016_NVMMRecordError "Air suspension controller: a016 NVMM record error";
CM_ SG_ 852 TAS_a021_TaskSchedulerError "Air suspension controller: a021 task scheduler error";
CM_ SG_ 852 TAS_a022_TaskInitError "Air suspension controller: a022 task init error";
CM_ SG_ 852 TAS_a023_rtosResetRequested "Air suspension controller: a023 rtos reset requested";
CM_ SG_ 852 TAS_a024_prefetchAbort "Air suspension controller: a024 prefetch abort";
CM_ SG_ 852 TAS_a025_CrashEvent "Air suspension controller: a025 crash event";
CM_ SG_ 852 TAS_a030_PWMerrorFL "Air suspension controller: a030 PW merror FL";
CM_ SG_ 852 TAS_a031_PWMerrorFR "Air suspension controller: a031 PW merror FR";
CM_ SG_ 852 TAS_a032_PWMerrorRL "Air suspension controller: a032 PW merror RL";
CM_ SG_ 852 TAS_a033_PWMerrorRR "Air suspension controller: a033 PW merror RR";
CM_ SG_ 852 TAS_a034_PWMshortFL "Air suspension controller: a034 PW mshort FL";
CM_ SG_ 852 TAS_a035_PWMshortFR "Air suspension controller: a035 PW mshort FR";
CM_ SG_ 852 TAS_a036_PWMshortRL "Air suspension controller: a036 PW mshort RL";
CM_ SG_ 852 TAS_a037_PWMshortRR "Air suspension controller: a037 PW mshort RR";
CM_ SG_ 852 TAS_a038_PWMopenFL "Air suspension controller: a038 PW mopen FL";
CM_ SG_ 852 TAS_a039_PWMopenFR "Air suspension controller: a039 PW mopen FR";
CM_ SG_ 852 TAS_a040_PWMopenRL "Air suspension controller: a040 PW mopen RL";
CM_ SG_ 852 TAS_a041_PWMopenRR "Air suspension controller: a041 PW mopen RR";
CM_ SG_ 852 TAS_a043_Task1msError "Air suspension controller: a043 task1ms error";
CM_ SG_ 852 TAS_a044_Task10msError "Air suspension controller: a044 task10ms error";
CM_ SG_ 852 TAS_a045_Task100msError "Air suspension controller: a045 task100ms error";
CM_ SG_ 852 TAS_a046_Task1000msError "Air suspension controller: a046 task1000ms error";
CM_ SG_ 852 TAS_a061_XCPConnected "Air suspension controller: a061 XCP connected";
CM_ SG_ 852 TAS_a062_XCPWasConnected "Air suspension controller: a062 XCP was connected";
CM_ SG_ 852 TAS_a063_abortFault "Air suspension controller: a063 abort fault";
CM_ SG_ 852 TAS_a064_abortFaultExt "Air suspension controller: a064 abort fault ext";
CM_ SG_ 852 TAS_a065_ahbWriteFault "Air suspension controller: a065 ahb write fault";
CM_ SG_ 852 TAS_a066_undefinedInstructionAbo "Air suspension controller: a066 undefined instruction abort";
CM_ SG_ 852 TAS_a067_reservedHandlerAbort "Air suspension controller: a067 reserved handler abort";
CM_ SG_ 852 TAS_a070_underVoltage12V "Air suspension controller: a070 under voltage12 v";
CM_ SG_ 852 TAS_a071_overVoltage12V "Air suspension controller: a071 over voltage12 v";
CM_ SG_ 852 TAS_a072_shortCircuit5VOnBoard "Air suspension controller: a072 short circuit5 v on board";
CM_ SG_ 852 TAS_a073_underVoltage5VOnBoard "Air suspension controller: a073 under voltage5 v on board";
CM_ SG_ 852 TAS_a074_shortCircuit5VOffBoard "Air suspension controller: a074 short circuit5 v off board";
CM_ SG_ 852 TAS_a075_underVoltage5VOffBoard "Air suspension controller: a075 under voltage5 v off board";
CM_ SG_ 852 TAS_a076_overVoltage5VOffBoard "Air suspension controller: a076 over voltage5 v off board";
CM_ SG_ 852 TAS_a077_pressureSigVTooLow "Air suspension controller: a077 pressure sig v too low";
CM_ SG_ 852 TAS_a078_pressureSigVTooHigh "Air suspension controller: a078 pressure sig v too high";
CM_ SG_ 852 TAS_a080_shortCircuit5VHeight "Air suspension controller: a080 short circuit5 v height";
CM_ SG_ 852 TAS_a081_underVoltage5VHeight "Air suspension controller: a081 under voltage5 v height";
CM_ SG_ 852 TAS_a082_overVoltage5VHeight "Air suspension controller: a082 over voltage5 v height";
CM_ SG_ 852 TAS_a083_shortCircuit5VAnalog "Air suspension controller: a083 short circuit5 v analog";
CM_ SG_ 852 TAS_a084_underVoltage5VAnalog "Air suspension controller: a084 under voltage5 v analog";
CM_ SG_ 852 TAS_a085_overVoltage5VAnalog "Air suspension controller: a085 over voltage5 v analog";
CM_ SG_ 852 TAS_a086_underVoltage12VSwtchd "Air suspension controller: a086 under voltage12 v swtchd";
CM_ SG_ 852 TAS_a087_overVoltage12VSwtchd "Air suspension controller: a087 over voltage12 v swtchd";
CM_ SG_ 852 TAS_a093_OTPError "Air suspension controller: a093 OTP error";
CM_ SG_ 852 TAS_a098_VCFRONT_MIA "Air suspension controller: a098 VCFRONT MIA";
CM_ SG_ 852 TAS_a099_UI_MIA "Air suspension controller: a099 UI MIA";
CM_ SG_ 852 TAS_a100_RCM_MIA "Air suspension controller: a100 RCM MIA";
CM_ SG_ 852 TAS_a101_ESP_MIA "Air suspension controller: a101 ESP MIA";
CM_ SG_ 852 TAS_a102_DI_MIA "Air suspension controller: a102 DI MIA";
CM_ SG_ 852 TAS_a103_GTW_MIA "Air suspension controller: a103 GTW MIA";
CM_ SG_ 852 TAS_a105_ECUDebugMode "Air suspension controller: a105 ECU debug mode";
CM_ SG_ 852 TAS_a106_HighCPULoad "Air suspension controller: a106 high CPU load";
CM_ SG_ 852 TAS_a107_HighStackUsage "Air suspension controller: a107 high stack usage";
CM_ SG_ 852 TAS_a150_accelAvgImplausible_FL_ "Air suspension controller: a150 accel avg implausible FL x";
CM_ SG_ 852 TAS_a151_accelAvgImplausible_FL_ "Air suspension controller: a151 accel avg implausible FL y";
CM_ SG_ 852 TAS_a152_accelAvgImplausible_FL_ "Air suspension controller: a152 accel avg implausible FL z";
CM_ SG_ 852 TAS_a153_accelAvgImplausible_FR_ "Air suspension controller: a153 accel avg implausible FR x";
CM_ SG_ 852 TAS_a154_accelAvgImplausible_FR_ "Air suspension controller: a154 accel avg implausible FR y";
CM_ SG_ 852 TAS_a155_accelAvgImplausible_FR_ "Air suspension controller: a155 accel avg implausible FR z";
CM_ SG_ 852 TAS_a156_accelAvgImplausible_RL_ "Air suspension controller: a156 accel avg implausible RL x";
CM_ SG_ 852 TAS_a157_accelAvgImplausible_RL_ "Air suspension controller: a157 accel avg implausible RL y";
CM_ SG_ 852 TAS_a158_accelAvgImplausible_RL_ "Air suspension controller: a158 accel avg implausible RL z";
CM_ SG_ 852 TAS_a159_accelAvgImplausible_RR_ "Air suspension controller: a159 accel avg implausible RR x";
CM_ SG_ 852 TAS_a160_accelAvgImplausible_RR_ "Air suspension controller: a160 accel avg implausible RR y";
CM_ SG_ 852 TAS_a161_accelAvgImplausible_RR_ "Air suspension controller: a161 accel avg implausible RR z";
CM_ SG_ 852 TAS_a164_damperSolenoidMismatch "Air suspension controller: a164 damper solenoid mismatch";
CM_ SG_ 852 TAS_a165_damperValveCompFL "Air suspension controller: a165 damper valve comp FL";
CM_ SG_ 852 TAS_a166_damperValveRbndFL "Air suspension controller: a166 damper valve rbnd FL";
CM_ SG_ 852 TAS_a167_damperValveCompFR "Air suspension controller: a167 damper valve comp FR";
CM_ SG_ 852 TAS_a168_damperValveRbndFR "Air suspension controller: a168 damper valve rbnd FR";
CM_ SG_ 852 TAS_a169_damperValveCompRL "Air suspension controller: a169 damper valve comp RL";
CM_ SG_ 852 TAS_a170_damperValveRbndRL "Air suspension controller: a170 damper valve rbnd RL";
CM_ SG_ 852 TAS_a171_damperValveCompRR "Air suspension controller: a171 damper valve comp RR";
CM_ SG_ 852 TAS_a172_damperValveRbndRR "Air suspension controller: a172 damper valve rbnd RR";
CM_ SG_ 852 TAS_a173_staticLeakDetectFL "Air suspension controller: a173 static leak detect FL";
CM_ SG_ 852 TAS_a174_staticLeakDetectFR "Air suspension controller: a174 static leak detect FR";
CM_ SG_ 852 TAS_a175_staticLeakDetectRL "Air suspension controller: a175 static leak detect RL";
CM_ SG_ 852 TAS_a176_staticLeakDetectRR "Air suspension controller: a176 static leak detect RR";
CM_ SG_ 852 TAS_a190_a2bFrontAxleFault "Air suspension controller: a190 a2b front axle fault";
CM_ SG_ 852 TAS_a191_a2bRearAxleFault "Air suspension controller: a191 a2b rear axle fault";
CM_ SG_ 852 TAS_a192_rideHeightObserverDiver "Air suspension controller: a192 ride height observer divergence";
CM_ SG_ 852 TAS_a193_EPAS3P_MIA "Air suspension controller: a193 EPAS3 p MIA";
CM_ SG_ 852 TAS_a194_a2bFrontAxleDataError "Air suspension controller: a194 a2b front axle data error";
CM_ SG_ 852 TAS_a195_a2bRearAxleDataError "Air suspension controller: a195 a2b rear axle data error";
CM_ SG_ 852 TAS_a196_adaptiveDampingUsingDSP "Air suspension controller: a196 adaptive damping using DSP";
CM_ SG_ 852 TAS_a197_invalidAdaptiveModeRequ "Air suspension controller: a197 invalid adaptive mode requested";
CM_ SG_ 852 TAS_a200_jackModeActive "Air suspension controller: a200 jack mode active";
CM_ SG_ 852 TAS_a201_low12VBattery "Air suspension controller: a201 low12 v battery";
CM_ SG_ 852 TAS_a210_outOfRangeCalibration "Air suspension controller: a210 out of range calibration";
CM_ SG_ 852 TAS_a211_noRideHeightCalib "Air suspension controller: a211 no ride height calib";
CM_ SG_ 852 TAS_a213_yellowWarningLamp "Air suspension controller: a213 yellow warning lamp";
CM_ SG_ 852 TAS_a214_redWarningLamp "Air suspension controller: a214 red warning lamp";
CM_ SG_ 852 TAS_a215_limpHomeMode10 "Air suspension controller: a215 limp home mode10";
CM_ SG_ 852 TAS_a216_limpHomeMode20 "Air suspension controller: a216 limp home mode20";
CM_ SG_ 852 TAS_a217_limpHomeMode30 "Air suspension controller: a217 limp home mode30";
CM_ SG_ 852 TAS_a218_limpHomeMode40 "Air suspension controller: a218 limp home mode40";
CM_ SG_ 852 TAS_a220_exhaustGalleryFault "Air suspension controller: a220 exhaust gallery fault";
CM_ SG_ 852 TAS_a221_valveLeakDetected "Air suspension controller: a221 valve leak detected";
CM_ SG_ 852 TAS_a222_compressorPrefillFault "Air suspension controller: a222 compressor prefill fault";
CM_ SG_ 852 TAS_a223_blockedAirline "Air suspension controller: a223 blocked airline";
CM_ SG_ 852 TAS_a224_openAirline "Air suspension controller: a224 open airline";
CM_ SG_ 852 TAS_a225_galleryPressureTooHigh "Air suspension controller: a225 gallery pressure too high";
CM_ SG_ 852 TAS_a226_PWMfastDetectFL "Air suspension controller: a226 PW mfast detect FL";
CM_ SG_ 852 TAS_a227_PWMfastDetectFR "Air suspension controller: a227 PW mfast detect FR";
CM_ SG_ 852 TAS_a228_PWMfastDetectRL "Air suspension controller: a228 PW mfast detect RL";
CM_ SG_ 852 TAS_a229_PWMfastDetectRR "Air suspension controller: a229 PW mfast detect RR";
CM_ SG_ 852 TAS_a230_notifyGeofence "Air suspension controller: a230 notify geofence";
CM_ SG_ 852 TAS_a231_notifyRoughRoadRaise "Air suspension controller: a231 notify rough road raise";
CM_ SG_ 852 TAS_a232_suspensionTypeMismatch "Air suspension controller: a232 suspension type mismatch";
CM_ SG_ 852 TAS_a233_compressorStuckOn "Air suspension controller: a233 compressor stuck on";
CM_ SG_ 852 TAS_a234_damperHydraulicMismatch "Air suspension controller: a234 damper hydraulic mismatch";
CM_ SG_ 852 TAS_a240_airSpringLeak "Air suspension controller: a240 air spring leak";
CM_ SG_ 852 TAS_a284_serviceRunModeActive "Air suspension controller: a284 service run mode active";
CM_ SG_ 852 TAS_a285_twistSustainedUserVis "Air suspension controller: a285 twist sustained user vis";
CM_ SG_ 852 TAS_a286_driveCycleStats1 "Air suspension controller: a286 drive cycle stats1";
CM_ SG_ 852 TAS_a287_driveCycleStats2 "Air suspension controller: a287 drive cycle stats2";
CM_ SG_ 852 TAS_a288_driveCycleStats3 "Air suspension controller: a288 drive cycle stats3";
CM_ SG_ 852 TAS_a289_driveCycleStats4 "Air suspension controller: a289 drive cycle stats4";
CM_ SG_ 852 TAS_a290_twistSustainedAtSpeed "Air suspension controller: a290 twist sustained at speed";
CM_ SG_ 852 TAS_a291_frontAxleTooHigh "Air suspension controller: a291 front axle too high";
CM_ SG_ 852 TAS_a292_rearAxleTooHigh "Air suspension controller: a292 rear axle too high";
CM_ SG_ 852 TAS_a293_frontAxleTooLow "Air suspension controller: a293 front axle too low";
CM_ SG_ 852 TAS_a294_rearAxleTooLow "Air suspension controller: a294 rear axle too low";
CM_ SG_ 852 TAS_a295_targetHeightNotMet "Air suspension controller: a295 target height not met";
CM_ SG_ 852 TAS_a296_chassisTypeMismatch "Air suspension controller: a296 chassis type mismatch";
CM_ SG_ 852 TAS_a297_vinMismatch "Air suspension controller: a297 vin mismatch";
CM_ SG_ 852 TAS_a298_vinNotLearned "Air suspension controller: a298 vin not learned";
CM_ SG_ 852 TAS_a299_offsetEstimateTooLarge "Air suspension controller: a299 offset estimate too large";
CM_ SG_ 852 TAS_a300_offsetEstimateData1 "Air suspension controller: a300 offset estimate data1";
CM_ SG_ 852 TAS_a301_offsetEstimateData2 "Air suspension controller: a301 offset estimate data2";
CM_ SG_ 852 TAS_a303_massEstimateFrozen "Air suspension controller: a303 mass estimate frozen";
CM_ SG_ 852 TAS_a304_massEstimateFrozenData "Air suspension controller: a304 mass estimate frozen data";
CM_ SG_ 852 TAS_a305_newEndstopPosition "Air suspension controller: a305 new endstop position";
CM_ SG_ 852 TAS_a306_hardwareProtectFrozen "Air suspension controller: a306 hardware protect frozen";
CM_ SG_ 852 TAS_a307_endstopBoundaryComp "Air suspension controller: a307 endstop boundary comp";
CM_ SG_ 852 TAS_a308_endstopBoundaryRbnd "Air suspension controller: a308 endstop boundary rbnd";
CM_ SG_ 852 TAS_a309_controlFrozen "Air suspension controller: a309 control frozen";
CM_ SG_ 852 TAS_a310_controlFrozenData "Air suspension controller: a310 control frozen data";
CM_ SG_ 852 TAS_a311_accelsMIA "Air suspension controller: a311 accels MIA";
CM_ SG_ 852 TAS_a312_rotationalRatesMIA "Air suspension controller: a312 rotational rates MIA";
CM_ SG_ 852 TAS_a313_dampingCntrlDisabled "Air suspension controller: a313 damping cntrl disabled";
CM_ SG_ 852 TAS_a314_dampingReduced "Air suspension controller: a314 damping reduced";
CM_ SG_ 852 TAS_a315_pcbaHighTemp "Air suspension controller: a315 pcba high temp";
CM_ SG_ 852 TAS_a316_offsetsAccels "Air suspension controller: a316 offsets accels";
CM_ SG_ 852 TAS_a317_offsetsRotationalRates "Air suspension controller: a317 offsets rotational rates";
CM_ SG_ 852 TAS_a318_dampingCntrlInputMIA "Air suspension controller: a318 damping cntrl input MIA";
CM_ SG_ 852 TAS_a319_drivetrainTypeMismatch "Air suspension controller: a319 drivetrain type mismatch";
CM_ SG_ 852 TAS_a320_offsetsRotationalRates "Air suspension controller: a320 offsets rotational rates";
CM_ SG_ 852 TAS_a321_speedBumpAttributes1 "Air suspension controller: a321 speed bump attributes1";
CM_ SG_ 852 TAS_a322_speedBumpAttributes2 "Air suspension controller: a322 speed bump attributes2";
CM_ SG_ 852 TAS_a332_levelingThresholds1 "Air suspension controller: a332 leveling thresholds1";
CM_ SG_ 852 TAS_a333_levelingThresholds2 "Air suspension controller: a333 leveling thresholds2";
CM_ BO_ 523 "Air suspension controller message: axle data";
CM_ SG_ 523 TAS_axleIndex "Air suspension controller: axle index";
CM_ SG_ 523 TAS_rawHeightFL "Current height of the FL air spring; raw 1023 = signal not available (SNA)";
CM_ SG_ 523 TAS_staticHeightEstimateFL "Current static height estimate of the FL air spring; raw 1023 = signal not available (SNA)";
CM_ SG_ 523 TAS_componentPressureFL "Current static pressure of the FL air spring; raw 255 = signal not available (SNA)";
CM_ SG_ 523 TAS_rawHeightFR "Current height of the FR air spring; raw 1023 = signal not available (SNA)";
CM_ SG_ 523 TAS_staticHeightEstimateFR "Current static height estimate of the FR air spring; raw 1023 = signal not available (SNA)";
CM_ SG_ 523 TAS_componentPressureFR "Current static pressure of the FR air spring; raw 255 = signal not available (SNA)";
CM_ SG_ 523 TAS_rawHeightRL "Current height of the RL air spring; raw 1023 = signal not available (SNA)";
CM_ SG_ 523 TAS_staticHeightEstimateRL "Current static height estimate of the RL air spring; raw 1023 = signal not available (SNA)";
CM_ SG_ 523 TAS_componentPressureRL "Current static pressure of the RL air spring; raw 255 = signal not available (SNA)";
CM_ SG_ 523 TAS_rawHeightRR "Current height of the RR air spring; raw 1023 = signal not available (SNA)";
CM_ SG_ 523 TAS_staticHeightEstimateRR "Current static height estimate of the RR air spring; raw 1023 = signal not available (SNA)";
CM_ SG_ 523 TAS_componentPressureRR "Current static pressure of the RR air spring; raw 255 = signal not available (SNA)";
CM_ BO_ 1398 "Air suspension controller message: damping states";
CM_ SG_ 1398 TAS_endstopState "Air suspension controller: endstop state";
CM_ SG_ 1398 TAS_continuousControlState "SW-237496";
CM_ SG_ 1398 TAS_activeTireTune "Air suspension controller: active tire tune";
CM_ SG_ 1398 TAS_roughnessRaiseReason "Air suspension controller: roughness raise reason";
CM_ SG_ 1398 TAS_frontMetricDrivesRear "Air suspension controller: front metric drives rear";
CM_ SG_ 1398 TAS_roadCondition "Air suspension controller: road condition; raw 255 = signal not available (SNA)";
CM_ SG_ 1398 TAS_bellyProtect "Air suspension controller: belly protect";
CM_ SG_ 1398 TAS_frontMetricDrivesFront "Air suspension controller: front metric drives front";
CM_ SG_ 1398 TAS_speedBumpAxleFront "Air suspension controller: speed bump axle front";
CM_ SG_ 1398 TAS_speedBumpAxleRear "Air suspension controller: speed bump axle rear";
CM_ SG_ 1398 TAS_holeProtectFL "Air suspension controller: hole protect FL";
CM_ SG_ 1398 TAS_holeProtectFR "Air suspension controller: hole protect FR";
CM_ SG_ 1398 TAS_holeProtectRL "Air suspension controller: hole protect RL";
CM_ SG_ 1398 TAS_holeProtectRR "Air suspension controller: hole protect RR";
CM_ SG_ 1398 TAS_stepProtectFL "Air suspension controller: step protect FL";
CM_ SG_ 1398 TAS_stepProtectFR "Air suspension controller: step protect FR";
CM_ SG_ 1398 TAS_stepProtectRL "Air suspension controller: step protect RL";
CM_ SG_ 1398 TAS_stepProtectRR "Air suspension controller: step protect RR";
CM_ SG_ 1398 TAS_FDUTorqueCorruptionScale "Air suspension controller: FDU torque corruption scale; raw 15 = signal not available (SNA)";
CM_ SG_ 1398 TAS_sprungMassEstimate "Air suspension controller: sprung mass estimate; raw 31 = signal not available (SNA)";
CM_ SG_ 1398 TAS_anyDamperActive "Air suspension controller: any damper active";
CM_ SG_ 1398 TAS_dampingStatesCounter "Air suspension controller: damping states counter";
CM_ SG_ 1398 TAS_dampingStatesChecksum "Air suspension controller: damping states checksum";
CM_ BO_ 1357 "Air suspension controller message: info";
CM_ SG_ 1357 TAS_infoIndex "Air suspension controller: info index";
CM_ SG_ 1357 TAS_infoBuildType "Air suspension controller: info build type";
CM_ SG_ 1357 TAS_infoBuildConfigId "Air suspension controller: info build config id";
CM_ SG_ 1357 TAS_infoHardwareId "Air suspension controller: info hardware id";
CM_ SG_ 1357 TAS_infoComponentId "Air suspension controller: info component id";
CM_ SG_ 1357 TAS_infoPcbaId "Air suspension controller: info pcba id";
CM_ SG_ 1357 TAS_infoAssemblyId "Air suspension controller: info assembly id; raw 255 = signal not available (SNA)";
CM_ SG_ 1357 TAS_infoUsageId "Air suspension controller: info usage id";
CM_ SG_ 1357 TAS_infoSubUsageId "Air suspension controller: info sub usage id";
CM_ SG_ 1357 TAS_infoAppCrc "Air suspension controller: info app crc";
CM_ SG_ 1357 TAS_infoAppGitHash "Air suspension controller: info app git hash";
CM_ SG_ 1357 TAS_infoBootGitHash "Air suspension controller: info boot git hash";
CM_ SG_ 1357 TAS_infoPlatformType "Air suspension controller: info platform type";
CM_ SG_ 1357 TAS_infoMajorVersion "Air suspension controller: info major version; raw 255 = signal not available (SNA)";
CM_ SG_ 1357 TAS_infoBranchOrigin "Air suspension controller: info branch origin; raw 255 = signal not available (SNA)";
CM_ SG_ 1357 TAS_infoMaturity "Air suspension controller: info maturity; raw 255 = signal not available (SNA)";
CM_ SG_ 1357 TAS_infoHardwareRevision "Air suspension controller: info hardware revision; raw 255 = signal not available (SNA)";
CM_ BO_ 525 "Air suspension controller message: states";
CM_ SG_ 525 TAS_levelingState "Indicates air suspension leveling state.";
CM_ SG_ 525 TAS_levelingItem "Indicates the currently active air suspension components.";
CM_ SG_ 525 TAS_pressureGallery "Current air suspension valve block gallery pressure; raw 255 = signal not available (SNA)";
CM_ SG_ 525 TAS_pressureReservoir "Indicates the latest valid reservoir pressure; raw 255 = signal not available (SNA)";
CM_ SG_ 525 TAS_runMode "Indicates the status of run mode.";
CM_ SG_ 525 TAS_filterMode "Indicates the status of filter mode.";
CM_ SG_ 525 TAS_compressorRun "Either an indication that the compressor is running or a request to run the air compressor";
CM_ SG_ 525 TAS_twistDetected "TAS has detected large amount of twist.";
CM_ SG_ 525 TAS_leanDetected "TAS has detected vehicle to be leaning left or right.";
CM_ SG_ 525 TAS_limpHomeMode "Indicates which limp home mode is active.";
CM_ SG_ 525 TAS_targetLevel "Indicates target ride height.";
CM_ SG_ 525 TAS_currentLevel "Indicates current ride height.";
CM_ SG_ 525 TAS_jackMode "Indicates the status of Jack mode.";
CM_ SG_ 525 TAS_reduceVehicleSpeedRequest "Air suspension controller: reduce vehicle speed request";
CM_ SG_ 525 TAS_statesCounter "Air suspension controller: states counter";
CM_ SG_ 525 TAS_statesChecksum "Air suspension controller: states checksum";
CM_ BO_ 1627 "Air suspension controller message: uds response";
CM_ SG_ 1627 TAS_udsResponseData "Air suspension controller: uds response data";
CM_ BO_ 409 "Air suspension controller message: ui adaptive activity0";
CM_ SG_ 409 TAS_adaptiveActivityFL_C "Air suspension controller: adaptive activity FL c; raw 31 = signal not available (SNA)";
CM_ SG_ 409 TAS_adaptiveActivityFL_R "Air suspension controller: adaptive activity FL r; raw 31 = signal not available (SNA)";
CM_ SG_ 409 TAS_adaptiveActivityFR_C "Air suspension controller: adaptive activity FR c; raw 31 = signal not available (SNA)";
CM_ SG_ 409 TAS_adaptiveActivityFR_R "Air suspension controller: adaptive activity FR r; raw 31 = signal not available (SNA)";
CM_ SG_ 409 TAS_adaptiveActivityRL_C "Air suspension controller: adaptive activity RL c; raw 31 = signal not available (SNA)";
CM_ SG_ 409 TAS_adaptiveActivityRL_R "Air suspension controller: adaptive activity RL r; raw 31 = signal not available (SNA)";
CM_ SG_ 409 TAS_adaptiveActivityRR_C "Air suspension controller: adaptive activity RR c; raw 31 = signal not available (SNA)";
CM_ SG_ 409 TAS_adaptiveActivityRR_R "Air suspension controller: adaptive activity RR r; raw 31 = signal not available (SNA)";
CM_ SG_ 409 TAS_uiHeightFL "Air suspension controller: ui height FL; raw 63 = signal not available (SNA)";
CM_ SG_ 409 TAS_uiHeightFR "Air suspension controller: ui height FR; raw 63 = signal not available (SNA)";
CM_ SG_ 409 TAS_uiHeightRL "Air suspension controller: ui height RL; raw 63 = signal not available (SNA)";
CM_ SG_ 409 TAS_uiHeightRR "Air suspension controller: ui height RR; raw 63 = signal not available (SNA)";
CM_ BO_ 410 "Air suspension controller message: ui adaptive activity1";
CM_ SG_ 410 TAS_bodyAccelFL "Air suspension controller: body accel FL; raw 255 = signal not available (SNA)";
CM_ SG_ 410 TAS_bodyAccelFR "Air suspension controller: body accel FR; raw 255 = signal not available (SNA)";
CM_ SG_ 410 TAS_bodyAccelRL "Air suspension controller: body accel RL; raw 255 = signal not available (SNA)";
CM_ SG_ 410 TAS_bodyAccelRR "Air suspension controller: body accel RR; raw 255 = signal not available (SNA)";
CM_ BO_ 538 "Air suspension controller message: ui control";
CM_ SG_ 538 TAS_yellowWarningLamp "Air suspension controller: yellow warning lamp";
CM_ SG_ 538 TAS_redWarningLamp "Air suspension controller: red warning lamp";
CM_ SG_ 538 TAS_veryLowAllowed "Air suspension controller: very low allowed";
CM_ SG_ 538 TAS_lowAllowed "Air suspension controller: low allowed";
CM_ SG_ 538 TAS_standardAllowed "Air suspension controller: standard allowed";
CM_ SG_ 538 TAS_highAllowed "Air suspension controller: high allowed";
CM_ SG_ 538 TAS_veryHighAllowed "Air suspension controller: very high allowed";
CM_ SG_ 538 TAS_extractAllowed "Air suspension controller: extract allowed";
CM_ SG_ 538 TAS_showSpinner "Air suspension controller: show spinner";
CM_ SG_ 538 TAS_adaptiveRideModeOverride "Air suspension controller: adaptive ride mode override; raw 3 = signal not available (SNA)";
CM_ SG_ 538 TAS_levelSelectEnabled "Air suspension controller: level select enabled";
CM_ SG_ 538 TAS_jackModeToggleEnabled "Air suspension controller: jack mode toggle enabled";
CM_ SG_ 538 TAS_adaptiveRideSelectEnabled "Air suspension controller: adaptive ride select enabled";
CM_ SG_ 538 TAS_launchModeState "Air suspension controller: launch mode state";
CM_ SG_ 538 TAS_restrictUpLevelingFalcons "Air suspension controller: restrict up leveling falcons";
CM_ SG_ 538 TAS_restrictUpLevelingTrunk "Air suspension controller: restrict up leveling trunk";
CM_ SG_ 538 TAS_restrictDownLevelingDoors "Air suspension controller: restrict down leveling doors";
CM_ SG_ 538 TAS_restrictLevelingChargeCable "Air suspension controller: restrict leveling charge cable";
CM_ SG_ 538 TAS_restrictLevelingSystemCheck "Air suspension controller: restrict leveling system check";
CM_ SG_ 538 TAS_restrictLevelingTransport "Air suspension controller: restrict leveling transport";
CM_ SG_ 538 TAS_restrictLevelingShowroom "Indication that up and down leveling are restricted while showroom mode is active.";
CM_ SG_ 538 TAS_uiControlCounter "Air suspension controller: ui control counter";
CM_ SG_ 538 TAS_uiControlChecksum "Air suspension controller: ui control checksum";
CM_ BO_ 1410 "TCU ECU message: alert log";
CM_ SG_ 1410 TCU_alertID "TCU ECU: alert ID";
CM_ SG_ 1410 TCU_alertState "TCU ECU: alert state";
CM_ SG_ 1410 TCU_w001_FailCode "TCU ECU: w001 fail code";
CM_ SG_ 1410 TCU_w002_RejCause "TCU ECU: w002 rej cause";
CM_ SG_ 1410 TCU_w003_CallFailCode "TCU ECU: w003 call fail code";
CM_ SG_ 1410 TCU_w004_MSDFailCode "TCU ECU: w004 MSD fail code";
CM_ SG_ 1410 TCU_w006_Count "TCU ECU: w006 count";
CM_ BO_ 1472 "TCU ECU message: alert matrix1";
CM_ SG_ 1472 TCU_w001_IMSRegistrationFailed "TCU ECU: w001 IMS registration failed";
CM_ SG_ 1472 TCU_w002_CellRegRejected "TCU ECU: w002 cell reg rejected";
CM_ SG_ 1472 TCU_w003_ECallFailed "TCU ECU: w003 e call failed";
CM_ SG_ 1472 TCU_w004_MSDTransmissionFailed "TCU ECU: w004 MSD transmission failed";
CM_ SG_ 1472 TCU_w005_SIMSlotError "TCU ECU: w005 SIM slot error";
CM_ SG_ 1472 TCU_w006_MpssUnavailable "TCU ECU: w006 mpss unavailable";
CM_ BO_ 1409 "TCU ECU message: log";
CM_ SG_ 1409 TCU_logMux "TCU ECU: log mux";
CM_ SG_ 1409 TCU_cpuTemp "Indicates the current temperature reported by the Central Processing Unit (CPU) in the modem application processor";
CM_ SG_ 1409 TCU_cpuUsage "Indicates the current CPU usage in percentage reported by the modem application processor";
CM_ SG_ 1409 TCU_mdmCoreTemperature "Indicates the current Communication Processor (CP) temperature reported by the modem CP.";
CM_ SG_ 1409 TCU_availableMemory "Indicates the currently available Random Access Memory in the modem application processor";
CM_ SG_ 1409 TCU_pwm "Indicates the active Pulse Width Modulation (PWM) duty cycle applied to the modem fan.";
CM_ SG_ 1409 TCU_pwmcap "Indicates the active Pulse Width Modulation (PWM) duty cycle restriciton applied to the modem fan.";
CM_ SG_ 1409 TCU_totalResumes "Indicates the total amount of times the modem has been resumed";
CM_ SG_ 1409 TCU_mdmUplinkQueueSize "TCU ECU: mdm uplink queue size";
CM_ SG_ 1409 TCU_mdmRSRP "TCU ECU: mdm RSRP";
CM_ SG_ 1409 TCU_mdmSINR "TCU ECU: mdm SINR";
CM_ SG_ 1409 TCU_mdmUplinkAllowedRate "TCU ECU: mdm uplink allowed rate";
CM_ SG_ 1409 TCU_mdmUplinkAvgRage "TCU ECU: mdm uplink avg rage";
CM_ SG_ 1409 TCU_mdmServiceState "TCU ECU: mdm service state";
CM_ SG_ 1409 TCU_mdmIMSStatus "Indicates the current IP Multimedia System (IMS) registration state.";
CM_ SG_ 1409 TCU_mdmSIMStatus "TCU ECU: mdm SIM status";
CM_ SG_ 1409 TCU_mdmBusyActive "Reports whether the modem busy service is active on the modem application processor; raw 4294967295 = signal not available (SNA)";
CM_ BO_ 1408 "TCU ECU message: status";
CM_ SG_ 1408 TCU_statusMux "TCU ECU: status mux";
CM_ SG_ 1408 TCU_wakeUpReason "TCU ECU: wake up reason; raw 4294967295 = signal not available (SNA)";
CM_ SG_ 1408 TCU_tcuCmdId "TCU ECU: tcu cmd id";
CM_ SG_ 1408 TCU_goingToSleep "TCU ECU: going to sleep; raw 4294967295 = signal not available (SNA)";
CM_ BO_ 879 "Tire pressure monitoring message: status c";
CM_ SG_ 879 TPMS_c_globalHardWarning "Tire pressure monitoring: c global hard warning";
CM_ SG_ 879 TPMS_c_globalSoftWarning "Tire pressure monitoring: c global soft warning";
CM_ SG_ 879 TPMS_systemMalfunction "Tire pressure monitoring: system malfunction";
CM_ SG_ 879 TPMS_WA_version "Tire pressure monitoring: WA version";
CM_ SG_ 879 TPMS_globalDeltaPressure "Tire pressure monitoring: global delta pressure";
CM_ SG_ 879 TPMS_newSensorLearnt "Tire pressure monitoring: new sensor learnt";
CM_ SG_ 879 TPMS_softWarningRR "Tire pressure monitoring: soft warning RR";
CM_ SG_ 879 TPMS_hardWarningRR "Tire pressure monitoring: hard warning RR";
CM_ SG_ 879 TPMS_softWarningRL "Tire pressure monitoring: soft warning RL";
CM_ SG_ 879 TPMS_hardWarningRL "Tire pressure monitoring: hard warning RL";
CM_ SG_ 879 TPMS_softWarningFR "Tire pressure monitoring: soft warning FR";
CM_ SG_ 879 TPMS_hardWarningFR "Tire pressure monitoring: hard warning FR";
CM_ SG_ 879 TPMS_softWarningFL "Tire pressure monitoring: soft warning FL";
CM_ SG_ 879 TPMS_hardWarningFL "Tire pressure monitoring: hard warning FL";
CM_ SG_ 879 TPMS_learningStatus "Monitors Tire Pressure Monitoring System (TPMS) Learn Status and evaluates issues.";
CM_ SG_ 879 TPMS_localisationStatus "Monitors Tire Pressure Monitoring System (TPMS) Localization Status and evaluates issues.";
CM_ SG_ 879 TPMS_deltaPressWarningFL "Tire pressure monitoring: delta press warning FL";
CM_ SG_ 879 TPMS_deltaPressWarningFR "Tire pressure monitoring: delta press warning FR";
CM_ SG_ 879 TPMS_deltaPressWarningRL "Tire pressure monitoring: delta press warning RL";
CM_ SG_ 879 TPMS_deltaPressWarningRR "Tire pressure monitoring: delta press warning RR";
CM_ SG_ 879 TPMS_sensorNoResponseFL "Count of times Front Left sensor did not respond to message";
CM_ SG_ 879 TPMS_sensorNoResponseFR "Count of times Front Right sensor did not respond to message";
CM_ SG_ 879 TPMS_sensorNoResponseRL "Count of times Rear Left sensor did not respond to message";
CM_ SG_ 879 TPMS_sensorNoResponseRR "Count of times Rear Right sensor did not respond to message";
CM_ SG_ 879 TPMS_sensorThermShutdownFL "Tire pressure monitoring: sensor therm shutdown FL";
CM_ SG_ 879 TPMS_sensorThermShutdownFR "Tire pressure monitoring: sensor therm shutdown FR";
CM_ SG_ 879 TPMS_sensorThermShutdownRL "Tire pressure monitoring: sensor therm shutdown RL";
CM_ SG_ 879 TPMS_sensorThermShutdownRR "Tire pressure monitoring: sensor therm shutdown RR";
CM_ SG_ 879 TPMS_sensorBatteryLowFL "Tracks near end of life sensor batteries in the fleet.";
CM_ SG_ 879 TPMS_sensorBatteryLowFR "Tracks near end of life sensor batteries in the fleet.";
CM_ SG_ 879 TPMS_sensorBatteryLowRL "Tracks near end of life sensor batteries in the fleet.";
CM_ SG_ 879 TPMS_sensorBatteryLowRR "Tracks near end of life sensor batteries in the fleet.";
CM_ SG_ 879 TPMS_sensorDefectiveFL "Tracks malfunctioning sensors in the fleet.";
CM_ SG_ 879 TPMS_sensorDefectiveFR "Tracks malfunctioning sensors in the fleet.";
CM_ SG_ 879 TPMS_sensorDefectiveRL "Tracks malfunctioning sensors in the fleet.";
CM_ SG_ 879 TPMS_sensorDefectiveRR "Tracks malfunctioning sensors in the fleet.";
CM_ SG_ 879 TPMS_ecuUnderVoltage "Tire pressure monitoring: ecu under voltage";
CM_ SG_ 879 TPMS_ecuOverVoltage "Tire pressure monitoring: ecu over voltage";
CM_ SG_ 879 TPMS_ecuRamRomNvMFail "Tire pressure monitoring: ecu ram rom nv m fail";
CM_ SG_ 879 TPMS_rfReceiverFail "Tire pressure monitoring: rf receiver fail";
CM_ SG_ 879 TPMS_wheelPulseMissing "Tire pressure monitoring: wheel pulse missing";
CM_ SG_ 879 TPMS_vehicleSpeedFail "Tire pressure monitoring: vehicle speed fail";
CM_ SG_ 879 TPMS_externalTemperatureFail "Tire pressure monitoring: external temperature fail";
CM_ SG_ 879 TPMS_eolNotCompleted "Monitors sensor completion of End of Line (EOL) routine.";
CM_ SG_ 879 TPMS_rcpFront "Front tire recommended cold pressure";
CM_ SG_ 879 TPMS_rcpRear "Rear tire recommended cold pressure";
CM_ BO_ 802 "Tire pressure monitoring message: data";
CM_ SG_ 802 TPMS_pressureFL "front left tire pressure; raw 255 = signal not available (SNA)";
CM_ SG_ 802 TPMS_temperatureFL "front left tire temperature; raw 255 = signal not available (SNA)";
CM_ SG_ 802 TPMS_pressureFR "front right tire pressure; raw 255 = signal not available (SNA)";
CM_ SG_ 802 TPMS_temperatureFR "front right tire temperature; raw 255 = signal not available (SNA)";
CM_ SG_ 802 TPMS_pressureRL "rear left tire pressure; raw 255 = signal not available (SNA)";
CM_ SG_ 802 TPMS_temperatureRL "rear left tire temperature; raw 255 = signal not available (SNA)";
CM_ SG_ 802 TPMS_pressureRR "rear right tire pressure; raw 255 = signal not available (SNA)";
CM_ SG_ 802 TPMS_temperatureRR "rear right tire temperature; raw 255 = signal not available (SNA)";
CM_ BO_ 1519 "Tire pressure monitoring message: info";
CM_ SG_ 1519 TPMS_infoIndex "Tire pressure monitoring: info index";
CM_ SG_ 1519 TPMS_infoComponentID "Tire pressure monitoring: info component ID";
CM_ SG_ 1519 TPMS_infoPcbaID "Tire pressure monitoring: info pcba ID";
CM_ SG_ 1519 TPMS_infoAssemblyID "Tire pressure monitoring: info assembly ID";
CM_ SG_ 1519 TPMS_infoUsageID "Tire pressure monitoring: info usage ID";
CM_ SG_ 1519 TPMS_infoApplicationCRC "Tire pressure monitoring: info application CRC";
CM_ SG_ 1519 TPMS_infoBootUdsProtoVersion "Tire pressure monitoring: info boot uds proto version";
CM_ SG_ 1519 TPMS_infoBootloaderCRC "Tire pressure monitoring: info bootloader CRC";
CM_ BO_ 1631 "Tire pressure monitoring message: uds response";
CM_ SG_ 1631 TPMS_udsResponseData "Tire pressure monitoring: uds response data";
BA_DEF_ BO_ "GenMsgCycleTime" INT 0 3600000;
BA_DEF_ BO_ "GenMsgSendType" ENUM "Cyclic","NotUsed","NotUsed","NotUsed","NotUsed","NotUsed","NotUsed","IfActive","NoMsgSendType","NotUsed";
BA_DEF_ BO_ "VFrameFormat" ENUM "StandardCAN","ExtendedCAN","reserved","J1939PG","reserved","reserved","reserved","reserved","reserved","reserved","reserved","reserved","reserved","reserved","StandardCAN_FD","ExtendedCAN_FD";
BA_DEF_ BO_ "CANFD_BRS" ENUM "0","1";
BA_DEF_ SG_ "GenSigSNA" STRING;
BA_DEF_ SG_ "SystemSignalLongSymbol" STRING;
BA_DEF_ SG_ "Confidence" ENUM "validated","plausible","layout-only","contradicted";
BA_DEF_DEF_ "GenMsgCycleTime" 0;
BA_DEF_DEF_ "GenMsgSendType" "NoMsgSendType";
BA_DEF_DEF_ "VFrameFormat" "StandardCAN";
BA_DEF_DEF_ "CANFD_BRS" "1";
BA_DEF_DEF_ "GenSigSNA" "";
BA_DEF_DEF_ "SystemSignalLongSymbol" "";
BA_DEF_DEF_ "Confidence" "layout-only";
BA_ "GenMsgCycleTime" BO_ 852 100;
BA_ "GenMsgSendType" BO_ 852 0;
BA_ "GenMsgCycleTime" BO_ 523 20;
BA_ "GenMsgSendType" BO_ 523 0;
BA_ "GenMsgCycleTime" BO_ 1398 100;
BA_ "GenMsgSendType" BO_ 1398 0;
BA_ "GenMsgCycleTime" BO_ 1357 1000;
BA_ "GenMsgSendType" BO_ 1357 0;
BA_ "GenMsgCycleTime" BO_ 525 100;
BA_ "GenMsgSendType" BO_ 525 0;
BA_ "GenMsgCycleTime" BO_ 409 50;
BA_ "GenMsgSendType" BO_ 409 0;
BA_ "GenMsgCycleTime" BO_ 410 50;
BA_ "GenMsgSendType" BO_ 410 0;
BA_ "GenMsgCycleTime" BO_ 538 100;
BA_ "GenMsgSendType" BO_ 538 0;
BA_ "GenMsgCycleTime" BO_ 1472 1000;
BA_ "GenMsgSendType" BO_ 1472 0;
BA_ "GenMsgCycleTime" BO_ 1409 1000;
BA_ "GenMsgSendType" BO_ 1409 0;
BA_ "GenMsgCycleTime" BO_ 1408 1000;
BA_ "GenMsgSendType" BO_ 1408 0;
BA_ "GenMsgCycleTime" BO_ 879 1000;
BA_ "GenMsgSendType" BO_ 879 0;
BA_ "GenMsgCycleTime" BO_ 802 1000;
BA_ "GenMsgSendType" BO_ 802 0;
BA_ "GenMsgCycleTime" BO_ 1519 1000;
BA_ "GenMsgSendType" BO_ 1519 0;
BA_ "Confidence" SG_ 1835 TAS_alertID 1;
BA_ "Confidence" SG_ 1835 TAS_alertState 1;
BA_ "Confidence" SG_ 1835 TAS_a030_PWMdutyCycleFL 1;
BA_ "Confidence" SG_ 1835 TAS_a030_PWMfrequencyFL 1;
BA_ "Confidence" SG_ 1835 TAS_a030_PWMfaultFL 1;
BA_ "Confidence" SG_ 1835 TAS_a031_PWMdutyCycleFR 1;
BA_ "Confidence" SG_ 1835 TAS_a031_PWMfrequencyFR 1;
BA_ "Confidence" SG_ 1835 TAS_a031_PWMfaultFR 1;
BA_ "Confidence" SG_ 1835 TAS_a032_PWMdutyCycleRL 1;
BA_ "Confidence" SG_ 1835 TAS_a032_PWMfrequencyRL 1;
BA_ "Confidence" SG_ 1835 TAS_a032_PWMfaultRL 1;
BA_ "Confidence" SG_ 1835 TAS_a033_PWMdutyCycleRR 1;
BA_ "Confidence" SG_ 1835 TAS_a033_PWMfrequencyRR 1;
BA_ "Confidence" SG_ 1835 TAS_a033_PWMfaultRR 1;
BA_ "Confidence" SG_ 1835 TAS_a034_PWMdutyCycleFL 1;
BA_ "Confidence" SG_ 1835 TAS_a034_PWMfrequencyFL 1;
BA_ "Confidence" SG_ 1835 TAS_a034_PWMfaultFL 1;
BA_ "Confidence" SG_ 1835 TAS_a035_PWMdutyCycleFR 1;
BA_ "Confidence" SG_ 1835 TAS_a035_PWMfrequencyFR 1;
BA_ "Confidence" SG_ 1835 TAS_a035_PWMfaultFR 1;
BA_ "Confidence" SG_ 1835 TAS_a036_PWMdutyCycleRL 1;
BA_ "Confidence" SG_ 1835 TAS_a036_PWMfrequencyRL 1;
BA_ "Confidence" SG_ 1835 TAS_a036_PWMfaultRL 1;
BA_ "Confidence" SG_ 1835 TAS_a037_PWMdutyCycleRR 1;
BA_ "Confidence" SG_ 1835 TAS_a037_PWMfrequencyRR 1;
BA_ "Confidence" SG_ 1835 TAS_a037_PWMfaultRR 1;
BA_ "Confidence" SG_ 1835 TAS_a038_PWMdutyCycleFL 1;
BA_ "Confidence" SG_ 1835 TAS_a038_PWMfrequencyFL 1;
BA_ "Confidence" SG_ 1835 TAS_a038_PWMfaultFL 1;
BA_ "Confidence" SG_ 1835 TAS_a039_PWMdutyCycleFR 1;
BA_ "Confidence" SG_ 1835 TAS_a039_PWMfrequencyFR 1;
BA_ "Confidence" SG_ 1835 TAS_a039_PWMfaultFR 1;
BA_ "Confidence" SG_ 1835 TAS_a040_PWMdutyCycleRL 1;
BA_ "Confidence" SG_ 1835 TAS_a040_PWMfrequencyRL 1;
BA_ "Confidence" SG_ 1835 TAS_a040_PWMfaultRL 1;
BA_ "Confidence" SG_ 1835 TAS_a041_PWMdutyCycleRR 1;
BA_ "Confidence" SG_ 1835 TAS_a041_PWMfrequencyRR 1;
BA_ "Confidence" SG_ 1835 TAS_a041_PWMfaultRR 1;
BA_ "Confidence" SG_ 1835 TAS_a070_voltage12V 1;
BA_ "Confidence" SG_ 1835 TAS_a071_voltage12V 1;
BA_ "Confidence" SG_ 1835 TAS_a072_voltage5VOnBoard 1;
BA_ "Confidence" SG_ 1835 TAS_a073_voltage5VOnBoard 1;
BA_ "Confidence" SG_ 1835 TAS_a074_voltage5VOffBoard 1;
BA_ "Confidence" SG_ 1835 TAS_a075_voltage5VOffBoard 1;
BA_ "Confidence" SG_ 1835 TAS_a076_voltage5VOffBoard 1;
BA_ "Confidence" SG_ 1835 TAS_a077_sensorVoltage 1;
BA_ "Confidence" SG_ 1835 TAS_a077_sensorRefVoltage 1;
BA_ "Confidence" SG_ 1835 TAS_a078_sensorVoltage 1;
BA_ "Confidence" SG_ 1835 TAS_a078_sensorRefVoltage 1;
BA_ "Confidence" SG_ 1835 TAS_a080_voltage5VHeight 1;
BA_ "Confidence" SG_ 1835 TAS_a081_voltage5VHeight 1;
BA_ "Confidence" SG_ 1835 TAS_a082_voltage5VHeight 1;
BA_ "Confidence" SG_ 1835 TAS_a083_voltage5VAnalog 1;
BA_ "Confidence" SG_ 1835 TAS_a084_voltage5VAnalog 1;
BA_ "Confidence" SG_ 1835 TAS_a085_voltage5VAnalog 1;
BA_ "Confidence" SG_ 1835 TAS_a086_voltage12VSwitched 1;
BA_ "Confidence" SG_ 1835 TAS_a087_voltage12VSwitched 1;
BA_ "SystemSignalLongSymbol" SG_ 1835 TAS_a098_VCFRONT_LVPowerState_MI "TAS_a098_VCFRONT_LVPowerState_MIA";
BA_ "SystemSignalLongSymbol" SG_ 1835 TAS_a098_VCFRONT_systemStatus_MI "TAS_a098_VCFRONT_systemStatus_MIA";
BA_ "SystemSignalLongSymbol" SG_ 1835 TAS_a099_UI_driverAssistMapData_ "TAS_a099_UI_driverAssistMapData_MIA";
BA_ "SystemSignalLongSymbol" SG_ 1835 TAS_a099_UI_suspensionControl_MI "TAS_a099_UI_suspensionControl_MIA";
BA_ "Confidence" SG_ 1835 TAS_a164_detectedDamperSolenoid 1;
BA_ "Confidence" SG_ 1835 TAS_a164_expectedDamperSolenoid 1;
BA_ "Confidence" SG_ 1835 TAS_a165_damperValveFault 1;
BA_ "Confidence" SG_ 1835 TAS_a166_damperValveFault 1;
BA_ "Confidence" SG_ 1835 TAS_a167_damperValveFault 1;
BA_ "Confidence" SG_ 1835 TAS_a168_damperValveFault 1;
BA_ "Confidence" SG_ 1835 TAS_a169_damperValveFault 1;
BA_ "Confidence" SG_ 1835 TAS_a170_damperValveFault 1;
BA_ "Confidence" SG_ 1835 TAS_a171_damperValveFault 1;
BA_ "Confidence" SG_ 1835 TAS_a172_damperValveFault 1;
BA_ "Confidence" SG_ 1835 TAS_a173_heightDelta_mm 1;
BA_ "Confidence" SG_ 1835 TAS_a174_heightDelta_mm 1;
BA_ "Confidence" SG_ 1835 TAS_a175_heightDelta_mm 1;
BA_ "Confidence" SG_ 1835 TAS_a176_heightDelta_mm 1;
BA_ "Confidence" SG_ 1835 TAS_a190_a2bFaultType 1;
BA_ "Confidence" SG_ 1835 TAS_a190_a2bInterruptType 1;
BA_ "Confidence" SG_ 1835 TAS_a190_a2bFaultSource 1;
BA_ "Confidence" SG_ 1835 TAS_a191_a2bFaultType 1;
BA_ "Confidence" SG_ 1835 TAS_a191_a2bInterruptType 1;
BA_ "Confidence" SG_ 1835 TAS_a191_a2bFaultSource 1;
BA_ "Confidence" SG_ 1835 TAS_a192_rideHeightVelDspFL 1;
BA_ "Confidence" SG_ 1835 TAS_a192_rideHeightVelDspFR 1;
BA_ "Confidence" SG_ 1835 TAS_a192_rideHeightVelDspRL 1;
BA_ "Confidence" SG_ 1835 TAS_a192_rideHeightVelDspRR 1;
BA_ "Confidence" SG_ 1835 TAS_a192_rideHeightVelObserverFL 1;
BA_ "Confidence" SG_ 1835 TAS_a192_rideHeightVelObserverFR 1;
BA_ "Confidence" SG_ 1835 TAS_a192_rideHeightVelObserverRL 1;
BA_ "Confidence" SG_ 1835 TAS_a192_rideHeightVelObserverRR 1;
BA_ "Confidence" SG_ 1835 TAS_a210_heightSensorDeltaFL 1;
BA_ "Confidence" SG_ 1835 TAS_a210_heightSensorDeltaFR 1;
BA_ "Confidence" SG_ 1835 TAS_a210_heightSensorDeltaRL 1;
BA_ "Confidence" SG_ 1835 TAS_a210_heightSensorDeltaRR 1;
BA_ "Confidence" SG_ 1835 TAS_a220_galleryPressure 1;
BA_ "Confidence" SG_ 1835 TAS_a220_timeInExhaust 1;
BA_ "Confidence" SG_ 1835 TAS_a221_galleryPressureDelta 1;
BA_ "Confidence" SG_ 1835 TAS_a221_timeInIdle 1;
BA_ "Confidence" SG_ 1835 TAS_a222_galleryPressureDelta 1;
BA_ "Confidence" SG_ 1835 TAS_a223_galleryPressure 1;
BA_ "Confidence" SG_ 1835 TAS_a224_galleryPressure 1;
BA_ "Confidence" SG_ 1835 TAS_a225_galleryPressure 1;
BA_ "Confidence" SG_ 1835 TAS_a226_PWMdutyCycleFL 1;
BA_ "Confidence" SG_ 1835 TAS_a226_PWMfrequencyFL 1;
BA_ "Confidence" SG_ 1835 TAS_a226_PWMfaultFL 1;
BA_ "Confidence" SG_ 1835 TAS_a227_PWMdutyCycleFR 1;
BA_ "Confidence" SG_ 1835 TAS_a227_PWMfrequencyFR 1;
BA_ "Confidence" SG_ 1835 TAS_a227_PWMfaultFR 1;
BA_ "Confidence" SG_ 1835 TAS_a228_PWMdutyCycleRL 1;
BA_ "Confidence" SG_ 1835 TAS_a228_PWMfrequencyRL 1;
BA_ "Confidence" SG_ 1835 TAS_a228_PWMfaultRL 1;
BA_ "Confidence" SG_ 1835 TAS_a229_PWMdutyCycleRR 1;
BA_ "Confidence" SG_ 1835 TAS_a229_PWMfrequencyRR 1;
BA_ "Confidence" SG_ 1835 TAS_a229_PWMfaultRR 1;
BA_ "Confidence" SG_ 1835 TAS_a232_detectedSuspensionType 1;
BA_ "Confidence" SG_ 1835 TAS_a232_expectedSuspensionType 1;
BA_ "Confidence" SG_ 1835 TAS_a234_detectedDamperHydraulic 1;
BA_ "Confidence" SG_ 1835 TAS_a234_expectedDamperHydraulic 1;
BA_ "Confidence" SG_ 1835 TAS_a240_adjustCountRatioSpring 1;
BA_ "Confidence" SG_ 1835 TAS_a240_adjustCountRatio 1;
BA_ "GenSigSNA" SG_ 1835 TAS_a240_adjustCountRatio "255";
BA_ "Confidence" SG_ 1835 TAS_a240_adjustTimeRatioSpring 1;
BA_ "Confidence" SG_ 1835 TAS_a240_adjustTimeRatio 1;
BA_ "GenSigSNA" SG_ 1835 TAS_a240_adjustTimeRatio "255";
BA_ "Confidence" SG_ 1835 TAS_a240_compExhTimeRatio 1;
BA_ "Confidence" SG_ 1835 TAS_a240_crossPressure 1;
BA_ "Confidence" SG_ 1835 TAS_a285_twistLevel 1;
BA_ "Confidence" SG_ 1835 TAS_a290_twistLevel 1;
BA_ "Confidence" SG_ 1835 TAS_a291_frontAxleHeight 1;
BA_ "Confidence" SG_ 1835 TAS_a292_rearAxleHeight 1;
BA_ "Confidence" SG_ 1835 TAS_a293_frontAxleHeight 1;
BA_ "Confidence" SG_ 1835 TAS_a294_rearAxleHeight 1;
BA_ "Confidence" SG_ 1835 TAS_a295_targetHeight 1;
BA_ "Confidence" SG_ 1835 TAS_a296_detectedChassisType 1;
BA_ "Confidence" SG_ 1835 TAS_a296_expectedChassisType 1;
BA_ "Confidence" SG_ 1835 TAS_a319_detectedDrivetrainType 1;
BA_ "Confidence" SG_ 1835 TAS_a319_expectedDrivetrainType 1;
BA_ "Confidence" SG_ 852 TAS_matrixIndex 1;
BA_ "SystemSignalLongSymbol" SG_ 852 TAS_a066_undefinedInstructionAbo "TAS_a066_undefinedInstructionAbort";
BA_ "SystemSignalLongSymbol" SG_ 852 TAS_a150_accelAvgImplausible_FL_ "TAS_a150_accelAvgImplausible_FL_X";
BA_ "SystemSignalLongSymbol" SG_ 852 TAS_a151_accelAvgImplausible_FL_ "TAS_a151_accelAvgImplausible_FL_Y";
BA_ "SystemSignalLongSymbol" SG_ 852 TAS_a152_accelAvgImplausible_FL_ "TAS_a152_accelAvgImplausible_FL_Z";
BA_ "SystemSignalLongSymbol" SG_ 852 TAS_a153_accelAvgImplausible_FR_ "TAS_a153_accelAvgImplausible_FR_X";
BA_ "SystemSignalLongSymbol" SG_ 852 TAS_a154_accelAvgImplausible_FR_ "TAS_a154_accelAvgImplausible_FR_Y";
BA_ "SystemSignalLongSymbol" SG_ 852 TAS_a155_accelAvgImplausible_FR_ "TAS_a155_accelAvgImplausible_FR_Z";
BA_ "SystemSignalLongSymbol" SG_ 852 TAS_a156_accelAvgImplausible_RL_ "TAS_a156_accelAvgImplausible_RL_X";
BA_ "SystemSignalLongSymbol" SG_ 852 TAS_a157_accelAvgImplausible_RL_ "TAS_a157_accelAvgImplausible_RL_Y";
BA_ "SystemSignalLongSymbol" SG_ 852 TAS_a158_accelAvgImplausible_RL_ "TAS_a158_accelAvgImplausible_RL_Z";
BA_ "SystemSignalLongSymbol" SG_ 852 TAS_a159_accelAvgImplausible_RR_ "TAS_a159_accelAvgImplausible_RR_X";
BA_ "SystemSignalLongSymbol" SG_ 852 TAS_a160_accelAvgImplausible_RR_ "TAS_a160_accelAvgImplausible_RR_Y";
BA_ "SystemSignalLongSymbol" SG_ 852 TAS_a161_accelAvgImplausible_RR_ "TAS_a161_accelAvgImplausible_RR_Z";
BA_ "SystemSignalLongSymbol" SG_ 852 TAS_a192_rideHeightObserverDiver "TAS_a192_rideHeightObserverDivergence";
BA_ "SystemSignalLongSymbol" SG_ 852 TAS_a197_invalidAdaptiveModeRequ "TAS_a197_invalidAdaptiveModeRequested";
BA_ "Confidence" SG_ 523 TAS_axleIndex 1;
BA_ "Confidence" SG_ 523 TAS_rawHeightFL 0;
BA_ "GenSigSNA" SG_ 523 TAS_rawHeightFL "1023";
BA_ "Confidence" SG_ 523 TAS_staticHeightEstimateFL 0;
BA_ "GenSigSNA" SG_ 523 TAS_staticHeightEstimateFL "1023";
BA_ "Confidence" SG_ 523 TAS_componentPressureFL 0;
BA_ "GenSigSNA" SG_ 523 TAS_componentPressureFL "255";
BA_ "Confidence" SG_ 523 TAS_rawHeightFR 0;
BA_ "GenSigSNA" SG_ 523 TAS_rawHeightFR "1023";
BA_ "Confidence" SG_ 523 TAS_staticHeightEstimateFR 0;
BA_ "GenSigSNA" SG_ 523 TAS_staticHeightEstimateFR "1023";
BA_ "Confidence" SG_ 523 TAS_componentPressureFR 0;
BA_ "GenSigSNA" SG_ 523 TAS_componentPressureFR "255";
BA_ "Confidence" SG_ 523 TAS_rawHeightRL 0;
BA_ "GenSigSNA" SG_ 523 TAS_rawHeightRL "1023";
BA_ "Confidence" SG_ 523 TAS_staticHeightEstimateRL 0;
BA_ "GenSigSNA" SG_ 523 TAS_staticHeightEstimateRL "1023";
BA_ "Confidence" SG_ 523 TAS_componentPressureRL 0;
BA_ "GenSigSNA" SG_ 523 TAS_componentPressureRL "255";
BA_ "Confidence" SG_ 523 TAS_rawHeightRR 0;
BA_ "GenSigSNA" SG_ 523 TAS_rawHeightRR "1023";
BA_ "Confidence" SG_ 523 TAS_staticHeightEstimateRR 0;
BA_ "GenSigSNA" SG_ 523 TAS_staticHeightEstimateRR "1023";
BA_ "Confidence" SG_ 523 TAS_componentPressureRR 0;
BA_ "GenSigSNA" SG_ 523 TAS_componentPressureRR "255";
BA_ "Confidence" SG_ 1398 TAS_endstopState 0;
BA_ "Confidence" SG_ 1398 TAS_continuousControlState 0;
BA_ "Confidence" SG_ 1398 TAS_activeTireTune 0;
BA_ "Confidence" SG_ 1398 TAS_roughnessRaiseReason 0;
BA_ "Confidence" SG_ 1398 TAS_frontMetricDrivesRear 0;
BA_ "Confidence" SG_ 1398 TAS_roadCondition 0;
BA_ "GenSigSNA" SG_ 1398 TAS_roadCondition "255";
BA_ "Confidence" SG_ 1398 TAS_bellyProtect 0;
BA_ "Confidence" SG_ 1398 TAS_frontMetricDrivesFront 0;
BA_ "Confidence" SG_ 1398 TAS_speedBumpAxleFront 0;
BA_ "Confidence" SG_ 1398 TAS_speedBumpAxleRear 0;
BA_ "Confidence" SG_ 1398 TAS_holeProtectFL 0;
BA_ "Confidence" SG_ 1398 TAS_holeProtectFR 0;
BA_ "Confidence" SG_ 1398 TAS_holeProtectRL 0;
BA_ "Confidence" SG_ 1398 TAS_holeProtectRR 0;
BA_ "Confidence" SG_ 1398 TAS_stepProtectFL 0;
BA_ "Confidence" SG_ 1398 TAS_stepProtectFR 0;
BA_ "Confidence" SG_ 1398 TAS_stepProtectRL 0;
BA_ "Confidence" SG_ 1398 TAS_stepProtectRR 0;
BA_ "Confidence" SG_ 1398 TAS_FDUTorqueCorruptionScale 0;
BA_ "GenSigSNA" SG_ 1398 TAS_FDUTorqueCorruptionScale "15";
BA_ "Confidence" SG_ 1398 TAS_sprungMassEstimate 0;
BA_ "GenSigSNA" SG_ 1398 TAS_sprungMassEstimate "31";
BA_ "Confidence" SG_ 1398 TAS_anyDamperActive 0;
BA_ "Confidence" SG_ 1398 TAS_dampingStatesCounter 0;
BA_ "Confidence" SG_ 1398 TAS_dampingStatesChecksum 0;
BA_ "Confidence" SG_ 1357 TAS_infoIndex 1;
BA_ "Confidence" SG_ 1357 TAS_infoBuildType 0;
BA_ "Confidence" SG_ 1357 TAS_infoBuildConfigId 0;
BA_ "Confidence" SG_ 1357 TAS_infoHardwareId 0;
BA_ "Confidence" SG_ 1357 TAS_infoComponentId 0;
BA_ "Confidence" SG_ 1357 TAS_infoPcbaId 0;
BA_ "Confidence" SG_ 1357 TAS_infoAssemblyId 0;
BA_ "GenSigSNA" SG_ 1357 TAS_infoAssemblyId "255";
BA_ "Confidence" SG_ 1357 TAS_infoUsageId 0;
BA_ "Confidence" SG_ 1357 TAS_infoSubUsageId 0;
BA_ "Confidence" SG_ 1357 TAS_infoAppCrc 0;
BA_ "Confidence" SG_ 1357 TAS_infoAppGitHash 0;
BA_ "Confidence" SG_ 1357 TAS_infoBootGitHash 0;
BA_ "Confidence" SG_ 1357 TAS_infoPlatformType 0;
BA_ "Confidence" SG_ 1357 TAS_infoMajorVersion 0;
BA_ "GenSigSNA" SG_ 1357 TAS_infoMajorVersion "255";
BA_ "Confidence" SG_ 1357 TAS_infoBranchOrigin 0;
BA_ "GenSigSNA" SG_ 1357 TAS_infoBranchOrigin "255";
BA_ "Confidence" SG_ 1357 TAS_infoMaturity 0;
BA_ "GenSigSNA" SG_ 1357 TAS_infoMaturity "255";
BA_ "Confidence" SG_ 1357 TAS_infoHardwareRevision 0;
BA_ "GenSigSNA" SG_ 1357 TAS_infoHardwareRevision "255";
BA_ "Confidence" SG_ 525 TAS_levelingState 0;
BA_ "Confidence" SG_ 525 TAS_levelingItem 0;
BA_ "Confidence" SG_ 525 TAS_pressureGallery 0;
BA_ "GenSigSNA" SG_ 525 TAS_pressureGallery "255";
BA_ "Confidence" SG_ 525 TAS_pressureReservoir 0;
BA_ "GenSigSNA" SG_ 525 TAS_pressureReservoir "255";
BA_ "Confidence" SG_ 525 TAS_runMode 0;
BA_ "Confidence" SG_ 525 TAS_filterMode 0;
BA_ "Confidence" SG_ 525 TAS_compressorRun 0;
BA_ "Confidence" SG_ 525 TAS_twistDetected 0;
BA_ "Confidence" SG_ 525 TAS_leanDetected 0;
BA_ "Confidence" SG_ 525 TAS_limpHomeMode 0;
BA_ "Confidence" SG_ 525 TAS_targetLevel 0;
BA_ "Confidence" SG_ 525 TAS_currentLevel 0;
BA_ "Confidence" SG_ 525 TAS_jackMode 0;
BA_ "Confidence" SG_ 525 TAS_reduceVehicleSpeedRequest 0;
BA_ "Confidence" SG_ 525 TAS_statesCounter 0;
BA_ "Confidence" SG_ 525 TAS_statesChecksum 0;
BA_ "Confidence" SG_ 1627 TAS_udsResponseData 1;
BA_ "Confidence" SG_ 409 TAS_adaptiveActivityFL_C 0;
BA_ "GenSigSNA" SG_ 409 TAS_adaptiveActivityFL_C "31";
BA_ "Confidence" SG_ 409 TAS_adaptiveActivityFL_R 0;
BA_ "GenSigSNA" SG_ 409 TAS_adaptiveActivityFL_R "31";
BA_ "Confidence" SG_ 409 TAS_adaptiveActivityFR_C 0;
BA_ "GenSigSNA" SG_ 409 TAS_adaptiveActivityFR_C "31";
BA_ "Confidence" SG_ 409 TAS_adaptiveActivityFR_R 0;
BA_ "GenSigSNA" SG_ 409 TAS_adaptiveActivityFR_R "31";
BA_ "Confidence" SG_ 409 TAS_adaptiveActivityRL_C 0;
BA_ "GenSigSNA" SG_ 409 TAS_adaptiveActivityRL_C "31";
BA_ "Confidence" SG_ 409 TAS_adaptiveActivityRL_R 0;
BA_ "GenSigSNA" SG_ 409 TAS_adaptiveActivityRL_R "31";
BA_ "Confidence" SG_ 409 TAS_adaptiveActivityRR_C 0;
BA_ "GenSigSNA" SG_ 409 TAS_adaptiveActivityRR_C "31";
BA_ "Confidence" SG_ 409 TAS_adaptiveActivityRR_R 0;
BA_ "GenSigSNA" SG_ 409 TAS_adaptiveActivityRR_R "31";
BA_ "Confidence" SG_ 409 TAS_uiHeightFL 0;
BA_ "GenSigSNA" SG_ 409 TAS_uiHeightFL "63";
BA_ "Confidence" SG_ 409 TAS_uiHeightFR 0;
BA_ "GenSigSNA" SG_ 409 TAS_uiHeightFR "63";
BA_ "Confidence" SG_ 409 TAS_uiHeightRL 0;
BA_ "GenSigSNA" SG_ 409 TAS_uiHeightRL "63";
BA_ "Confidence" SG_ 409 TAS_uiHeightRR 0;
BA_ "GenSigSNA" SG_ 409 TAS_uiHeightRR "63";
BA_ "Confidence" SG_ 410 TAS_bodyAccelFL 0;
BA_ "GenSigSNA" SG_ 410 TAS_bodyAccelFL "255";
BA_ "Confidence" SG_ 410 TAS_bodyAccelFR 0;
BA_ "GenSigSNA" SG_ 410 TAS_bodyAccelFR "255";
BA_ "Confidence" SG_ 410 TAS_bodyAccelRL 0;
BA_ "GenSigSNA" SG_ 410 TAS_bodyAccelRL "255";
BA_ "Confidence" SG_ 410 TAS_bodyAccelRR 0;
BA_ "GenSigSNA" SG_ 410 TAS_bodyAccelRR "255";
BA_ "Confidence" SG_ 538 TAS_yellowWarningLamp 0;
BA_ "Confidence" SG_ 538 TAS_redWarningLamp 0;
BA_ "Confidence" SG_ 538 TAS_veryLowAllowed 0;
BA_ "Confidence" SG_ 538 TAS_lowAllowed 0;
BA_ "Confidence" SG_ 538 TAS_standardAllowed 0;
BA_ "Confidence" SG_ 538 TAS_highAllowed 0;
BA_ "Confidence" SG_ 538 TAS_veryHighAllowed 0;
BA_ "Confidence" SG_ 538 TAS_extractAllowed 0;
BA_ "Confidence" SG_ 538 TAS_showSpinner 0;
BA_ "Confidence" SG_ 538 TAS_adaptiveRideModeOverride 0;
BA_ "GenSigSNA" SG_ 538 TAS_adaptiveRideModeOverride "3";
BA_ "Confidence" SG_ 538 TAS_levelSelectEnabled 0;
BA_ "Confidence" SG_ 538 TAS_jackModeToggleEnabled 0;
BA_ "Confidence" SG_ 538 TAS_adaptiveRideSelectEnabled 0;
BA_ "Confidence" SG_ 538 TAS_launchModeState 0;
BA_ "Confidence" SG_ 538 TAS_restrictUpLevelingFalcons 0;
BA_ "Confidence" SG_ 538 TAS_restrictUpLevelingTrunk 0;
BA_ "Confidence" SG_ 538 TAS_restrictDownLevelingDoors 0;
BA_ "Confidence" SG_ 538 TAS_restrictLevelingChargeCable 0;
BA_ "Confidence" SG_ 538 TAS_restrictLevelingSystemCheck 0;
BA_ "Confidence" SG_ 538 TAS_restrictLevelingTransport 0;
BA_ "Confidence" SG_ 538 TAS_restrictLevelingShowroom 0;
BA_ "Confidence" SG_ 538 TAS_uiControlCounter 0;
BA_ "Confidence" SG_ 538 TAS_uiControlChecksum 0;
BA_ "Confidence" SG_ 1410 TCU_alertID 1;
BA_ "Confidence" SG_ 1410 TCU_alertState 1;
BA_ "Confidence" SG_ 1409 TCU_logMux 1;
BA_ "Confidence" SG_ 1409 TCU_cpuTemp 0;
BA_ "Confidence" SG_ 1409 TCU_cpuUsage 0;
BA_ "Confidence" SG_ 1409 TCU_mdmCoreTemperature 0;
BA_ "Confidence" SG_ 1409 TCU_availableMemory 0;
BA_ "Confidence" SG_ 1409 TCU_pwm 0;
BA_ "Confidence" SG_ 1409 TCU_pwmcap 0;
BA_ "Confidence" SG_ 1409 TCU_totalResumes 0;
BA_ "Confidence" SG_ 1409 TCU_mdmUplinkQueueSize 0;
BA_ "Confidence" SG_ 1409 TCU_mdmRSRP 0;
BA_ "Confidence" SG_ 1409 TCU_mdmSINR 0;
BA_ "Confidence" SG_ 1409 TCU_mdmUplinkAllowedRate 0;
BA_ "Confidence" SG_ 1409 TCU_mdmServiceState 0;
BA_ "Confidence" SG_ 1409 TCU_mdmIMSStatus 0;
BA_ "Confidence" SG_ 1409 TCU_mdmSIMStatus 0;
BA_ "Confidence" SG_ 1409 TCU_mdmBusyActive 0;
BA_ "GenSigSNA" SG_ 1409 TCU_mdmBusyActive "4294967295";
BA_ "Confidence" SG_ 1408 TCU_statusMux 1;
BA_ "Confidence" SG_ 1408 TCU_wakeUpReason 1;
BA_ "GenSigSNA" SG_ 1408 TCU_wakeUpReason "4294967295";
BA_ "Confidence" SG_ 1408 TCU_goingToSleep 1;
BA_ "GenSigSNA" SG_ 1408 TCU_goingToSleep "4294967295";
BA_ "Confidence" SG_ 879 TPMS_c_globalHardWarning 0;
BA_ "Confidence" SG_ 879 TPMS_c_globalSoftWarning 0;
BA_ "Confidence" SG_ 879 TPMS_systemMalfunction 0;
BA_ "Confidence" SG_ 879 TPMS_WA_version 0;
BA_ "Confidence" SG_ 879 TPMS_globalDeltaPressure 0;
BA_ "Confidence" SG_ 879 TPMS_newSensorLearnt 0;
BA_ "Confidence" SG_ 879 TPMS_softWarningRR 0;
BA_ "Confidence" SG_ 879 TPMS_hardWarningRR 0;
BA_ "Confidence" SG_ 879 TPMS_softWarningRL 0;
BA_ "Confidence" SG_ 879 TPMS_hardWarningRL 0;
BA_ "Confidence" SG_ 879 TPMS_softWarningFR 0;
BA_ "Confidence" SG_ 879 TPMS_hardWarningFR 0;
BA_ "Confidence" SG_ 879 TPMS_softWarningFL 0;
BA_ "Confidence" SG_ 879 TPMS_hardWarningFL 0;
BA_ "Confidence" SG_ 879 TPMS_learningStatus 0;
BA_ "Confidence" SG_ 879 TPMS_localisationStatus 0;
BA_ "Confidence" SG_ 879 TPMS_deltaPressWarningFL 0;
BA_ "Confidence" SG_ 879 TPMS_deltaPressWarningFR 0;
BA_ "Confidence" SG_ 879 TPMS_deltaPressWarningRL 0;
BA_ "Confidence" SG_ 879 TPMS_deltaPressWarningRR 0;
BA_ "Confidence" SG_ 879 TPMS_sensorNoResponseFL 0;
BA_ "Confidence" SG_ 879 TPMS_sensorNoResponseFR 0;
BA_ "Confidence" SG_ 879 TPMS_sensorNoResponseRL 0;
BA_ "Confidence" SG_ 879 TPMS_sensorNoResponseRR 0;
BA_ "Confidence" SG_ 879 TPMS_sensorThermShutdownFL 0;
BA_ "Confidence" SG_ 879 TPMS_sensorThermShutdownFR 0;
BA_ "Confidence" SG_ 879 TPMS_sensorThermShutdownRL 0;
BA_ "Confidence" SG_ 879 TPMS_sensorThermShutdownRR 0;
BA_ "Confidence" SG_ 879 TPMS_sensorBatteryLowFL 0;
BA_ "Confidence" SG_ 879 TPMS_sensorBatteryLowFR 0;
BA_ "Confidence" SG_ 879 TPMS_sensorBatteryLowRL 0;
BA_ "Confidence" SG_ 879 TPMS_sensorBatteryLowRR 0;
BA_ "Confidence" SG_ 879 TPMS_sensorDefectiveFL 0;
BA_ "Confidence" SG_ 879 TPMS_sensorDefectiveFR 0;
BA_ "Confidence" SG_ 879 TPMS_sensorDefectiveRL 0;
BA_ "Confidence" SG_ 879 TPMS_sensorDefectiveRR 0;
BA_ "Confidence" SG_ 879 TPMS_ecuUnderVoltage 0;
BA_ "Confidence" SG_ 879 TPMS_ecuOverVoltage 0;
BA_ "Confidence" SG_ 879 TPMS_ecuRamRomNvMFail 0;
BA_ "Confidence" SG_ 879 TPMS_rfReceiverFail 0;
BA_ "Confidence" SG_ 879 TPMS_wheelPulseMissing 0;
BA_ "Confidence" SG_ 879 TPMS_vehicleSpeedFail 0;
BA_ "Confidence" SG_ 879 TPMS_externalTemperatureFail 0;
BA_ "Confidence" SG_ 879 TPMS_eolNotCompleted 0;
BA_ "Confidence" SG_ 879 TPMS_rcpFront 0;
BA_ "Confidence" SG_ 879 TPMS_rcpRear 0;
BA_ "Confidence" SG_ 802 TPMS_pressureFL 0;
BA_ "GenSigSNA" SG_ 802 TPMS_pressureFL "255";
BA_ "Confidence" SG_ 802 TPMS_temperatureFL 0;
BA_ "GenSigSNA" SG_ 802 TPMS_temperatureFL "255";
BA_ "Confidence" SG_ 802 TPMS_pressureFR 0;
BA_ "GenSigSNA" SG_ 802 TPMS_pressureFR "255";
BA_ "Confidence" SG_ 802 TPMS_temperatureFR 0;
BA_ "GenSigSNA" SG_ 802 TPMS_temperatureFR "255";
BA_ "Confidence" SG_ 802 TPMS_pressureRL 0;
BA_ "GenSigSNA" SG_ 802 TPMS_pressureRL "255";
BA_ "Confidence" SG_ 802 TPMS_temperatureRL 0;
BA_ "GenSigSNA" SG_ 802 TPMS_temperatureRL "255";
BA_ "Confidence" SG_ 802 TPMS_pressureRR 0;
BA_ "GenSigSNA" SG_ 802 TPMS_pressureRR "255";
BA_ "Confidence" SG_ 802 TPMS_temperatureRR 0;
BA_ "GenSigSNA" SG_ 802 TPMS_temperatureRR "255";
BA_ "Confidence" SG_ 1519 TPMS_infoIndex 1;
BA_ "Confidence" SG_ 1519 TPMS_infoComponentID 0;
BA_ "Confidence" SG_ 1519 TPMS_infoPcbaID 0;
BA_ "Confidence" SG_ 1519 TPMS_infoAssemblyID 0;
BA_ "Confidence" SG_ 1519 TPMS_infoUsageID 0;
BA_ "Confidence" SG_ 1519 TPMS_infoApplicationCRC 0;
BA_ "Confidence" SG_ 1519 TPMS_infoBootUdsProtoVersion 0;
BA_ "Confidence" SG_ 1519 TPMS_infoBootloaderCRC 0;
BA_ "Confidence" SG_ 1631 TPMS_udsResponseData 1;
VAL_ 1835 TAS_alertID 333 "a333_levelingThresholds2" 332 "a332_levelingThresholds1" 322 "a322_speedBumpAttributes2" 321 "a321_speedBumpAttributes1" 320 "a320_offsetsRotationalRates" 319 "a319_drivetrainTypeMismatch" 318 "a318_dampingCntrlInputMIA" 317 "a317_offsetsRotationalRates" 316 "a316_offsetsAccels" 315 "a315_pcbaHighTemp" 314 "a314_dampingReduced" 313 "a313_dampingCntrlDisabled" 312 "a312_rotationalRatesMIA" 311 "a311_accelsMIA" 310 "a310_controlFrozenData" 309 "a309_controlFrozen" 308 "a308_endstopBoundaryRbnd" 307 "a307_endstopBoundaryComp" 306 "a306_hardwareProtectFrozen" 305 "a305_newEndstopPosition" 304 "a304_massEstimateFrozenData" 303 "a303_massEstimateFrozen" 301 "a301_offsetEstimateData2" 300 "a300_offsetEstimateData1" 299 "a299_offsetEstimateTooLarge" 298 "a298_vinNotLearned" 297 "a297_vinMismatch" 296 "a296_chassisTypeMismatch" 295 "a295_targetHeightNotMet" 294 "a294_rearAxleTooLow" 293 "a293_frontAxleTooLow" 292 "a292_rearAxleTooHigh" 291 "a291_frontAxleTooHigh" 290 "a290_twistSustainedAtSpeed" 289 "a289_driveCycleStats4" 288 "a288_driveCycleStats3" 287 "a287_driveCycleStats2" 286 "a286_driveCycleStats1" 285 "a285_twistSustainedUserVis" 284 "a284_serviceRunModeActive" 240 "a240_airSpringLeak" 234 "a234_damperHydraulicMismatch" 233 "a233_compressorStuckOn" 232 "a232_suspensionTypeMismatch" 231 "a231_notifyRoughRoadRaise" 230 "a230_notifyGeofence" 229 "a229_PWMfastDetectRR" 228 "a228_PWMfastDetectRL" 227 "a227_PWMfastDetectFR" 226 "a226_PWMfastDetectFL" 225 "a225_galleryPressureTooHigh" 224 "a224_openAirline" 223 "a223_blockedAirline" 222 "a222_compressorPrefillFault" 221 "a221_valveLeakDetected" 220 "a220_exhaustGalleryFault" 218 "a218_limpHomeMode40" 217 "a217_limpHomeMode30" 216 "a216_limpHomeMode20" 215 "a215_limpHomeMode10" 214 "a214_redWarningLamp" 213 "a213_yellowWarningLamp" 211 "a211_noRideHeightCalib" 210 "a210_outOfRangeCalibration" 201 "a201_low12VBattery" 200 "a200_jackModeActive" 197 "a197_invalidAdaptiveModeRequested" 196 "a196_adaptiveDampingUsingDSP" 195 "a195_a2bRearAxleDataError" 194 "a194_a2bFrontAxleDataError" 193 "a193_EPAS3P_MIA" 192 "a192_rideHeightObserverDivergence" 191 "a191_a2bRearAxleFault" 190 "a190_a2bFrontAxleFault" 176 "a176_staticLeakDetectRR" 175 "a175_staticLeakDetectRL" 174 "a174_staticLeakDetectFR" 173 "a173_staticLeakDetectFL" 172 "a172_damperValveRbndRR" 171 "a171_damperValveCompRR" 170 "a170_damperValveRbndRL" 169 "a169_damperValveCompRL" 168 "a168_damperValveRbndFR" 167 "a167_damperValveCompFR" 166 "a166_damperValveRbndFL" 165 "a165_damperValveCompFL" 164 "a164_damperSolenoidMismatch" 161 "a161_accelAvgImplausible_RR_Z" 160 "a160_accelAvgImplausible_RR_Y" 159 "a159_accelAvgImplausible_RR_X" 158 "a158_accelAvgImplausible_RL_Z" 157 "a157_accelAvgImplausible_RL_Y" 156 "a156_accelAvgImplausible_RL_X" 155 "a155_accelAvgImplausible_FR_Z" 154 "a154_accelAvgImplausible_FR_Y" 153 "a153_accelAvgImplausible_FR_X" 152 "a152_accelAvgImplausible_FL_Z" 151 "a151_accelAvgImplausible_FL_Y" 150 "a150_accelAvgImplausible_FL_X" 107 "a107_HighStackUsage" 106 "a106_HighCPULoad" 105 "a105_ECUDebugMode" 103 "a103_GTW_MIA" 102 "a102_DI_MIA" 101 "a101_ESP_MIA" 100 "a100_RCM_MIA" 99 "a099_UI_MIA" 98 "a098_VCFRONT_MIA" 93 "a093_OTPError" 87 "a087_overVoltage12VSwtchd" 86 "a086_underVoltage12VSwtchd" 85 "a085_overVoltage5VAnalog" 84 "a084_underVoltage5VAnalog" 83 "a083_shortCircuit5VAnalog" 82 "a082_overVoltage5VHeight" 81 "a081_underVoltage5VHeight" 80 "a080_shortCircuit5VHeight" 78 "a078_pressureSigVTooHigh" 77 "a077_pressureSigVTooLow" 76 "a076_overVoltage5VOffBoard" 75 "a075_underVoltage5VOffBoard" 74 "a074_shortCircuit5VOffBoard" 73 "a073_underVoltage5VOnBoard" 72 "a072_shortCircuit5VOnBoard" 71 "a071_overVoltage12V" 70 "a070_underVoltage12V" 67 "a067_reservedHandlerAbort" 66 "a066_undefinedInstructionAbort" 65 "a065_ahbWriteFault" 64 "a064_abortFaultExt" 63 "a063_abortFault" 62 "a062_XCPWasConnected" 61 "a061_XCPConnected" 46 "a046_Task1000msError" 45 "a045_Task100msError" 44 "a044_Task10msError" 43 "a043_Task1msError" 41 "a041_PWMopenRR" 40 "a040_PWMopenRL" 39 "a039_PWMopenFR" 38 "a038_PWMopenFL" 37 "a037_PWMshortRR" 36 "a036_PWMshortRL" 35 "a035_PWMshortFR" 34 "a034_PWMshortFL" 33 "a033_PWMerrorRR" 32 "a032_PWMerrorRL" 31 "a031_PWMerrorFR" 30 "a030_PWMerrorFL" 25 "a025_CrashEvent" 24 "a024_prefetchAbort" 23 "a023_rtosResetRequested" 22 "a022_TaskInitError" 21 "a021_TaskSchedulerError" 16 "a016_NVMMRecordError" 15 "a015_NVMMError" 12 "a012_CPUReset" 3 "a003_SWAssertion" 2 "a002_PowerLossReset" 1 "a001_WatchdogReset" 0 "ALERT_DO_NOT_USE_ZERO" ;
VAL_ 1835 TAS_alertState 1 "SET" 0 "CLEARED" ;
VAL_ 1835 TAS_a030_PWMfaultFL 9 "NONE" 8 "COUNT" 7 "OPEN_CIRCUIT" 6 "SHORT_CIRCUIT" 5 "MIA" 4 "OVER_MAX_DELTA_DUTY" 3 "UNDER_MIN_PERIOD" 2 "OVER_MAX_PERIOD" 1 "UNDER_MIN_DUTY" 0 "OVER_MAX_DUTY" ;
VAL_ 1835 TAS_a031_PWMfaultFR 9 "NONE" 8 "COUNT" 7 "OPEN_CIRCUIT" 6 "SHORT_CIRCUIT" 5 "MIA" 4 "OVER_MAX_DELTA_DUTY" 3 "UNDER_MIN_PERIOD" 2 "OVER_MAX_PERIOD" 1 "UNDER_MIN_DUTY" 0 "OVER_MAX_DUTY" ;
VAL_ 1835 TAS_a032_PWMfaultRL 9 "NONE" 8 "COUNT" 7 "OPEN_CIRCUIT" 6 "SHORT_CIRCUIT" 5 "MIA" 4 "OVER_MAX_DELTA_DUTY" 3 "UNDER_MIN_PERIOD" 2 "OVER_MAX_PERIOD" 1 "UNDER_MIN_DUTY" 0 "OVER_MAX_DUTY" ;
VAL_ 1835 TAS_a033_PWMfaultRR 9 "NONE" 8 "COUNT" 7 "OPEN_CIRCUIT" 6 "SHORT_CIRCUIT" 5 "MIA" 4 "OVER_MAX_DELTA_DUTY" 3 "UNDER_MIN_PERIOD" 2 "OVER_MAX_PERIOD" 1 "UNDER_MIN_DUTY" 0 "OVER_MAX_DUTY" ;
VAL_ 1835 TAS_a034_PWMfaultFL 9 "NONE" 8 "COUNT" 7 "OPEN_CIRCUIT" 6 "SHORT_CIRCUIT" 5 "MIA" 4 "OVER_MAX_DELTA_DUTY" 3 "UNDER_MIN_PERIOD" 2 "OVER_MAX_PERIOD" 1 "UNDER_MIN_DUTY" 0 "OVER_MAX_DUTY" ;
VAL_ 1835 TAS_a035_PWMfaultFR 9 "NONE" 8 "COUNT" 7 "OPEN_CIRCUIT" 6 "SHORT_CIRCUIT" 5 "MIA" 4 "OVER_MAX_DELTA_DUTY" 3 "UNDER_MIN_PERIOD" 2 "OVER_MAX_PERIOD" 1 "UNDER_MIN_DUTY" 0 "OVER_MAX_DUTY" ;
VAL_ 1835 TAS_a036_PWMfaultRL 9 "NONE" 8 "COUNT" 7 "OPEN_CIRCUIT" 6 "SHORT_CIRCUIT" 5 "MIA" 4 "OVER_MAX_DELTA_DUTY" 3 "UNDER_MIN_PERIOD" 2 "OVER_MAX_PERIOD" 1 "UNDER_MIN_DUTY" 0 "OVER_MAX_DUTY" ;
VAL_ 1835 TAS_a037_PWMfaultRR 9 "NONE" 8 "COUNT" 7 "OPEN_CIRCUIT" 6 "SHORT_CIRCUIT" 5 "MIA" 4 "OVER_MAX_DELTA_DUTY" 3 "UNDER_MIN_PERIOD" 2 "OVER_MAX_PERIOD" 1 "UNDER_MIN_DUTY" 0 "OVER_MAX_DUTY" ;
VAL_ 1835 TAS_a038_PWMfaultFL 9 "NONE" 8 "COUNT" 7 "OPEN_CIRCUIT" 6 "SHORT_CIRCUIT" 5 "MIA" 4 "OVER_MAX_DELTA_DUTY" 3 "UNDER_MIN_PERIOD" 2 "OVER_MAX_PERIOD" 1 "UNDER_MIN_DUTY" 0 "OVER_MAX_DUTY" ;
VAL_ 1835 TAS_a039_PWMfaultFR 9 "NONE" 8 "COUNT" 7 "OPEN_CIRCUIT" 6 "SHORT_CIRCUIT" 5 "MIA" 4 "OVER_MAX_DELTA_DUTY" 3 "UNDER_MIN_PERIOD" 2 "OVER_MAX_PERIOD" 1 "UNDER_MIN_DUTY" 0 "OVER_MAX_DUTY" ;
VAL_ 1835 TAS_a040_PWMfaultRL 9 "NONE" 8 "COUNT" 7 "OPEN_CIRCUIT" 6 "SHORT_CIRCUIT" 5 "MIA" 4 "OVER_MAX_DELTA_DUTY" 3 "UNDER_MIN_PERIOD" 2 "OVER_MAX_PERIOD" 1 "UNDER_MIN_DUTY" 0 "OVER_MAX_DUTY" ;
VAL_ 1835 TAS_a041_PWMfaultRR 9 "NONE" 8 "COUNT" 7 "OPEN_CIRCUIT" 6 "SHORT_CIRCUIT" 5 "MIA" 4 "OVER_MAX_DELTA_DUTY" 3 "UNDER_MIN_PERIOD" 2 "OVER_MAX_PERIOD" 1 "UNDER_MIN_DUTY" 0 "OVER_MAX_DUTY" ;
VAL_ 1835 TAS_a164_detectedDamperSolenoid 4 "NC_COMPRESSION_NC_REBOUND" 3 "NC_COMPRESSION_NO_REBOUND" 2 "NO_COMPRESSION_NC_REBOUND" 1 "NO_COMPRESSION_NO_REBOUND" 0 "UNKNOWN" ;
VAL_ 1835 TAS_a164_expectedDamperSolenoid 4 "NC_COMPRESSION_NC_REBOUND" 3 "NC_COMPRESSION_NO_REBOUND" 2 "NO_COMPRESSION_NC_REBOUND" 1 "NO_COMPRESSION_NO_REBOUND" 0 "UNKNOWN" ;
VAL_ 1835 TAS_a165_damperValveFault 15 "REMOTE_VALVE_FAULTED" 14 "POSTIVE_TO_NEGATIVE_SHORT" 13 "DRIVER_OVER_TEMPERATURE" 12 "FEEDBACK_CURRENT_MIA" 11 "TARGET_CURRENT_MIA" 10 "LOW_SIDE_STATUS_IMPLAUSIBLE" 9 "CURRENT_MISMATCH" 8 "CURRENT_IMPLAUSIBLE" 7 "HIGH_RESISTANCE" 6 "LOW_RESISTANCE" 5 "CROSS_CONNECTION_SHORT" 4 "OPEN_CIRCUIT" 3 "VOLTAGE_ON_CIRCUIT" 2 "SHORT_TO_GND" 1 "SHORT_TO_VBAT" 0 "NONE_UNUSED" ;
VAL_ 1835 TAS_a166_damperValveFault 15 "REMOTE_VALVE_FAULTED" 14 "POSTIVE_TO_NEGATIVE_SHORT" 13 "DRIVER_OVER_TEMPERATURE" 12 "FEEDBACK_CURRENT_MIA" 11 "TARGET_CURRENT_MIA" 10 "LOW_SIDE_STATUS_IMPLAUSIBLE" 9 "CURRENT_MISMATCH" 8 "CURRENT_IMPLAUSIBLE" 7 "HIGH_RESISTANCE" 6 "LOW_RESISTANCE" 5 "CROSS_CONNECTION_SHORT" 4 "OPEN_CIRCUIT" 3 "VOLTAGE_ON_CIRCUIT" 2 "SHORT_TO_GND" 1 "SHORT_TO_VBAT" 0 "NONE_UNUSED" ;
VAL_ 1835 TAS_a167_damperValveFault 15 "REMOTE_VALVE_FAULTED" 14 "POSTIVE_TO_NEGATIVE_SHORT" 13 "DRIVER_OVER_TEMPERATURE" 12 "FEEDBACK_CURRENT_MIA" 11 "TARGET_CURRENT_MIA" 10 "LOW_SIDE_STATUS_IMPLAUSIBLE" 9 "CURRENT_MISMATCH" 8 "CURRENT_IMPLAUSIBLE" 7 "HIGH_RESISTANCE" 6 "LOW_RESISTANCE" 5 "CROSS_CONNECTION_SHORT" 4 "OPEN_CIRCUIT" 3 "VOLTAGE_ON_CIRCUIT" 2 "SHORT_TO_GND" 1 "SHORT_TO_VBAT" 0 "NONE_UNUSED" ;
VAL_ 1835 TAS_a168_damperValveFault 15 "REMOTE_VALVE_FAULTED" 14 "POSTIVE_TO_NEGATIVE_SHORT" 13 "DRIVER_OVER_TEMPERATURE" 12 "FEEDBACK_CURRENT_MIA" 11 "TARGET_CURRENT_MIA" 10 "LOW_SIDE_STATUS_IMPLAUSIBLE" 9 "CURRENT_MISMATCH" 8 "CURRENT_IMPLAUSIBLE" 7 "HIGH_RESISTANCE" 6 "LOW_RESISTANCE" 5 "CROSS_CONNECTION_SHORT" 4 "OPEN_CIRCUIT" 3 "VOLTAGE_ON_CIRCUIT" 2 "SHORT_TO_GND" 1 "SHORT_TO_VBAT" 0 "NONE_UNUSED" ;
VAL_ 1835 TAS_a169_damperValveFault 15 "REMOTE_VALVE_FAULTED" 14 "POSTIVE_TO_NEGATIVE_SHORT" 13 "DRIVER_OVER_TEMPERATURE" 12 "FEEDBACK_CURRENT_MIA" 11 "TARGET_CURRENT_MIA" 10 "LOW_SIDE_STATUS_IMPLAUSIBLE" 9 "CURRENT_MISMATCH" 8 "CURRENT_IMPLAUSIBLE" 7 "HIGH_RESISTANCE" 6 "LOW_RESISTANCE" 5 "CROSS_CONNECTION_SHORT" 4 "OPEN_CIRCUIT" 3 "VOLTAGE_ON_CIRCUIT" 2 "SHORT_TO_GND" 1 "SHORT_TO_VBAT" 0 "NONE_UNUSED" ;
VAL_ 1835 TAS_a170_damperValveFault 15 "REMOTE_VALVE_FAULTED" 14 "POSTIVE_TO_NEGATIVE_SHORT" 13 "DRIVER_OVER_TEMPERATURE" 12 "FEEDBACK_CURRENT_MIA" 11 "TARGET_CURRENT_MIA" 10 "LOW_SIDE_STATUS_IMPLAUSIBLE" 9 "CURRENT_MISMATCH" 8 "CURRENT_IMPLAUSIBLE" 7 "HIGH_RESISTANCE" 6 "LOW_RESISTANCE" 5 "CROSS_CONNECTION_SHORT" 4 "OPEN_CIRCUIT" 3 "VOLTAGE_ON_CIRCUIT" 2 "SHORT_TO_GND" 1 "SHORT_TO_VBAT" 0 "NONE_UNUSED" ;
VAL_ 1835 TAS_a171_damperValveFault 15 "REMOTE_VALVE_FAULTED" 14 "POSTIVE_TO_NEGATIVE_SHORT" 13 "DRIVER_OVER_TEMPERATURE" 12 "FEEDBACK_CURRENT_MIA" 11 "TARGET_CURRENT_MIA" 10 "LOW_SIDE_STATUS_IMPLAUSIBLE" 9 "CURRENT_MISMATCH" 8 "CURRENT_IMPLAUSIBLE" 7 "HIGH_RESISTANCE" 6 "LOW_RESISTANCE" 5 "CROSS_CONNECTION_SHORT" 4 "OPEN_CIRCUIT" 3 "VOLTAGE_ON_CIRCUIT" 2 "SHORT_TO_GND" 1 "SHORT_TO_VBAT" 0 "NONE_UNUSED" ;
VAL_ 1835 TAS_a172_damperValveFault 15 "REMOTE_VALVE_FAULTED" 14 "POSTIVE_TO_NEGATIVE_SHORT" 13 "DRIVER_OVER_TEMPERATURE" 12 "FEEDBACK_CURRENT_MIA" 11 "TARGET_CURRENT_MIA" 10 "LOW_SIDE_STATUS_IMPLAUSIBLE" 9 "CURRENT_MISMATCH" 8 "CURRENT_IMPLAUSIBLE" 7 "HIGH_RESISTANCE" 6 "LOW_RESISTANCE" 5 "CROSS_CONNECTION_SHORT" 4 "OPEN_CIRCUIT" 3 "VOLTAGE_ON_CIRCUIT" 2 "SHORT_TO_GND" 1 "SHORT_TO_VBAT" 0 "NONE_UNUSED" ;
VAL_ 1835 TAS_a190_a2bFaultType 8 "OTHER" 7 "DEVICE_RESET" 6 "NO_CLOCK_SYNC" 5 "MASTER_VENDOR_ID" 4 "NODE_DROP" 3 "FAILED_DISCOVERY" 2 "DATA" 1 "HARDWARE" 0 "NONE" ;
VAL_ 1835 TAS_a190_a2bInterruptType 255 "MSTR_RUNNING" 254 "STANDBY_DONE" 253 "SUB_READ_INTTYPE_ERROR" 252 "STARTUP_ERROR" 251 "NONE" 128 "INTERRUPT_MESSAGING_ERROR" 51 "MAILBOX_1_EMPTY" 50 "MAILBOX_1_FULL" 49 "MAILBOX_0_EMPTY" 48 "MAILBOX_0_FULL" 42 "NON_LOCALIZED_SHORT_TO_VBAT" 41 "NON_LOCALIZED_SHORT_TO_GROUND" 26 "INTERRUPT_CRC_ERROR" 25 "I2CERR" 24 "DSCDONE" 23 "IO7PND" 22 "IO6PND" 21 "IO5PND" 20 "IO4PND" 19 "IO3PND" 18 "IO2PND" 17 "IO1PND" 16 "IO0PND" 15 "UNDETERMINED_CABLE_FAULT" 14 "DISCONNECTED_WRONG_PORT_REVERSE" 13 "INTTYPE_REVERSE_CONNECTED_AD2428" 12 "INTTYPE_DISCONNECTED_AD2428" 11 "BP_SHORT_BN" 10 "BN_SHORT_VBAT" 9 "BP_SHORT_GND" 6 "SRF_CRC_ERROR" 5 "SRF_MISS_ERROR" 4 "BIT_ERROR_COUNT_OVERFLOW" 3 "DATA_SLOT_PARITY_ERROR" 2 "CRC_ERROR" 1 "DATA_SLOT_DECODING_ERROR" 0 "HEADER_COUNT_ERROR" ;
VAL_ 1835 TAS_a190_a2bFaultSource 3 "UNDETERMINED" 2 "MASTER" 1 "LEFT" 0 "RIGHT" ;
VAL_ 1835 TAS_a191_a2bFaultType 8 "OTHER" 7 "DEVICE_RESET" 6 "NO_CLOCK_SYNC" 5 "MASTER_VENDOR_ID" 4 "NODE_DROP" 3 "FAILED_DISCOVERY" 2 "DATA" 1 "HARDWARE" 0 "NONE" ;
VAL_ 1835 TAS_a191_a2bInterruptType 255 "MSTR_RUNNING" 254 "STANDBY_DONE" 253 "SUB_READ_INTTYPE_ERROR" 252 "STARTUP_ERROR" 251 "NONE" 128 "INTERRUPT_MESSAGING_ERROR" 51 "MAILBOX_1_EMPTY" 50 "MAILBOX_1_FULL" 49 "MAILBOX_0_EMPTY" 48 "MAILBOX_0_FULL" 42 "NON_LOCALIZED_SHORT_TO_VBAT" 41 "NON_LOCALIZED_SHORT_TO_GROUND" 26 "INTERRUPT_CRC_ERROR" 25 "I2CERR" 24 "DSCDONE" 23 "IO7PND" 22 "IO6PND" 21 "IO5PND" 20 "IO4PND" 19 "IO3PND" 18 "IO2PND" 17 "IO1PND" 16 "IO0PND" 15 "UNDETERMINED_CABLE_FAULT" 14 "DISCONNECTED_WRONG_PORT_REVERSE" 13 "INTTYPE_REVERSE_CONNECTED_AD2428" 12 "INTTYPE_DISCONNECTED_AD2428" 11 "BP_SHORT_BN" 10 "BN_SHORT_VBAT" 9 "BP_SHORT_GND" 6 "SRF_CRC_ERROR" 5 "SRF_MISS_ERROR" 4 "BIT_ERROR_COUNT_OVERFLOW" 3 "DATA_SLOT_PARITY_ERROR" 2 "CRC_ERROR" 1 "DATA_SLOT_DECODING_ERROR" 0 "HEADER_COUNT_ERROR" ;
VAL_ 1835 TAS_a191_a2bFaultSource 3 "UNDETERMINED" 2 "MASTER" 1 "LEFT" 0 "RIGHT" ;
VAL_ 1835 TAS_a226_PWMfaultFL 9 "NONE" 8 "COUNT" 7 "OPEN_CIRCUIT" 6 "SHORT_CIRCUIT" 5 "MIA" 4 "OVER_MAX_DELTA_DUTY" 3 "UNDER_MIN_PERIOD" 2 "OVER_MAX_PERIOD" 1 "UNDER_MIN_DUTY" 0 "OVER_MAX_DUTY" ;
VAL_ 1835 TAS_a227_PWMfaultFR 9 "NONE" 8 "COUNT" 7 "OPEN_CIRCUIT" 6 "SHORT_CIRCUIT" 5 "MIA" 4 "OVER_MAX_DELTA_DUTY" 3 "UNDER_MIN_PERIOD" 2 "OVER_MAX_PERIOD" 1 "UNDER_MIN_DUTY" 0 "OVER_MAX_DUTY" ;
VAL_ 1835 TAS_a228_PWMfaultRL 9 "NONE" 8 "COUNT" 7 "OPEN_CIRCUIT" 6 "SHORT_CIRCUIT" 5 "MIA" 4 "OVER_MAX_DELTA_DUTY" 3 "UNDER_MIN_PERIOD" 2 "OVER_MAX_PERIOD" 1 "UNDER_MIN_DUTY" 0 "OVER_MAX_DUTY" ;
VAL_ 1835 TAS_a229_PWMfaultRR 9 "NONE" 8 "COUNT" 7 "OPEN_CIRCUIT" 6 "SHORT_CIRCUIT" 5 "MIA" 4 "OVER_MAX_DELTA_DUTY" 3 "UNDER_MIN_PERIOD" 2 "OVER_MAX_PERIOD" 1 "UNDER_MIN_DUTY" 0 "OVER_MAX_DUTY" ;
VAL_ 1835 TAS_a232_detectedSuspensionType 6 "TESLA_ADAPTIVE" 5 "TESLA_PLUS" 4 "TESLA_STANDARD" 3 "CONTI_PLUS" 2 "CONTI_STANDARD" 1 "NONE" 0 "UNKNOWN" ;
VAL_ 1835 TAS_a232_expectedSuspensionType 6 "TESLA_ADAPTIVE" 5 "TESLA_PLUS" 4 "TESLA_STANDARD" 3 "CONTI_PLUS" 2 "CONTI_STANDARD" 1 "NONE" 0 "UNKNOWN" ;
VAL_ 1835 TAS_a234_detectedDamperHydraulic 2 "P3" 1 "V0" 0 "UNKNOWN" ;
VAL_ 1835 TAS_a234_expectedDamperHydraulic 2 "P3" 1 "V0" 0 "UNKNOWN" ;
VAL_ 1835 TAS_a240_adjustCountRatioSpring 4 "UNKNOWN" 3 "RR" 2 "RL" 1 "FR" 0 "FL" ;
VAL_ 1835 TAS_a240_adjustCountRatio 255 "SNA" ;
VAL_ 1835 TAS_a240_adjustTimeRatioSpring 4 "UNKNOWN" 3 "RR" 2 "RL" 1 "FR" 0 "FL" ;
VAL_ 1835 TAS_a240_adjustTimeRatio 255 "SNA" ;
VAL_ 1835 TAS_a296_detectedChassisType 4 "CYBERTRUCK" 3 "MODEL3" 2 "MODELX" 1 "MODELS" 0 "UNKNOWN" ;
VAL_ 1835 TAS_a296_expectedChassisType 4 "CYBERTRUCK" 3 "MODEL3" 2 "MODELX" 1 "MODELS" 0 "UNKNOWN" ;
VAL_ 1835 TAS_a319_detectedDrivetrainType 3 "AWD_DUAL_REAR" 2 "AWD" 1 "RWD" 0 "UNKNOWN" ;
VAL_ 1835 TAS_a319_expectedDrivetrainType 3 "AWD_DUAL_REAR" 2 "AWD" 1 "RWD" 0 "UNKNOWN" ;
VAL_ 852 TAS_matrixIndex 5 "AlertMatrix5" 4 "AlertMatrix4" 3 "AlertMatrix3" 2 "AlertMatrix2" 1 "AlertMatrix1" 0 "AlertMatrix0" ;
VAL_ 523 TAS_axleIndex 1 "axleRear" 0 "axleFront" ;
VAL_ 523 TAS_rawHeightFL 1023 "SNA" ;
VAL_ 523 TAS_staticHeightEstimateFL 1023 "SNA" ;
VAL_ 523 TAS_componentPressureFL 255 "SNA" ;
VAL_ 523 TAS_rawHeightFR 1023 "SNA" ;
VAL_ 523 TAS_staticHeightEstimateFR 1023 "SNA" ;
VAL_ 523 TAS_componentPressureFR 255 "SNA" ;
VAL_ 523 TAS_rawHeightRL 1023 "SNA" ;
VAL_ 523 TAS_staticHeightEstimateRL 1023 "SNA" ;
VAL_ 523 TAS_componentPressureRL 255 "SNA" ;
VAL_ 523 TAS_rawHeightRR 1023 "SNA" ;
VAL_ 523 TAS_staticHeightEstimateRR 1023 "SNA" ;
VAL_ 523 TAS_componentPressureRR 255 "SNA" ;
VAL_ 1398 TAS_endstopState 1 "TAS_DAMPING_STATE_ACTIVE" 0 "TAS_DAMPING_STATE_STANDBY" ;
VAL_ 1398 TAS_continuousControlState 1 "TAS_DAMPING_STATE_ACTIVE" 0 "TAS_DAMPING_STATE_STANDBY" ;
VAL_ 1398 TAS_activeTireTune 1 "TAS_TIRE_TUNE_MICHELIN_SUMMER_21" 0 "TAS_TIRE_TUNE_DEFAULT" ;
VAL_ 1398 TAS_roughnessRaiseReason 2 "TAS_ROUGHNESS_RAISE_REASON_LOOKAHEAD" 1 "TAS_ROUGHNESS_RAISE_REASON_LEGACY" 0 "TAS_ROUGHNESS_RAISE_REASON_NONE" ;
VAL_ 1398 TAS_frontMetricDrivesRear 3 "TAS_ACTION_ACTIVE" 2 "TAS_ACTION_ARMED" 1 "TAS_ACTION_STANDBY" 0 "TAS_ACTION_DISABLED" ;
VAL_ 1398 TAS_roadCondition 255 "SNA" ;
VAL_ 1398 TAS_bellyProtect 3 "TAS_ACTION_ACTIVE" 2 "TAS_ACTION_ARMED" 1 "TAS_ACTION_STANDBY" 0 "TAS_ACTION_DISABLED" ;
VAL_ 1398 TAS_frontMetricDrivesFront 3 "TAS_ACTION_ACTIVE" 2 "TAS_ACTION_ARMED" 1 "TAS_ACTION_STANDBY" 0 "TAS_ACTION_DISABLED" ;
VAL_ 1398 TAS_speedBumpAxleFront 4 "TAS_ACTION_CANCELED" 3 "TAS_ACTION_ACTIVE" 2 "TAS_ACTION_ARMED" 1 "TAS_ACTION_STANDBY" 0 "TAS_ACTION_DISABLED" ;
VAL_ 1398 TAS_speedBumpAxleRear 4 "TAS_ACTION_CANCELED" 3 "TAS_ACTION_ACTIVE" 2 "TAS_ACTION_ARMED" 1 "TAS_ACTION_STANDBY" 0 "TAS_ACTION_DISABLED" ;
VAL_ 1398 TAS_holeProtectFL 3 "TAS_ACTION_ACTIVE" 2 "TAS_ACTION_ARMED" 1 "TAS_ACTION_STANDBY" 0 "TAS_ACTION_DISABLED" ;
VAL_ 1398 TAS_holeProtectFR 3 "TAS_ACTION_ACTIVE" 2 "TAS_ACTION_ARMED" 1 "TAS_ACTION_STANDBY" 0 "TAS_ACTION_DISABLED" ;
VAL_ 1398 TAS_holeProtectRL 3 "TAS_ACTION_ACTIVE" 2 "TAS_ACTION_ARMED" 1 "TAS_ACTION_STANDBY" 0 "TAS_ACTION_DISABLED" ;
VAL_ 1398 TAS_holeProtectRR 3 "TAS_ACTION_ACTIVE" 2 "TAS_ACTION_ARMED" 1 "TAS_ACTION_STANDBY" 0 "TAS_ACTION_DISABLED" ;
VAL_ 1398 TAS_stepProtectFL 3 "TAS_ACTION_ACTIVE" 2 "TAS_ACTION_ARMED" 1 "TAS_ACTION_STANDBY" 0 "TAS_ACTION_DISABLED" ;
VAL_ 1398 TAS_stepProtectFR 3 "TAS_ACTION_ACTIVE" 2 "TAS_ACTION_ARMED" 1 "TAS_ACTION_STANDBY" 0 "TAS_ACTION_DISABLED" ;
VAL_ 1398 TAS_stepProtectRL 3 "TAS_ACTION_ACTIVE" 2 "TAS_ACTION_ARMED" 1 "TAS_ACTION_STANDBY" 0 "TAS_ACTION_DISABLED" ;
VAL_ 1398 TAS_stepProtectRR 3 "TAS_ACTION_ACTIVE" 2 "TAS_ACTION_ARMED" 1 "TAS_ACTION_STANDBY" 0 "TAS_ACTION_DISABLED" ;
VAL_ 1398 TAS_FDUTorqueCorruptionScale 15 "SNA" ;
VAL_ 1398 TAS_sprungMassEstimate 31 "SNA" ;
VAL_ 1357 TAS_infoIndex 255 "END" 41 "SUBCOMPONENT14" 40 "SUBCOMPONENT13" 39 "SUBCOMPONENT12" 38 "SUBCOMPONENT11" 37 "SUBCOMPONENT10" 36 "SUBCOMPONENT9" 35 "SUBCOMPONENT8" 34 "SUBCOMPONENT7" 33 "SUBCOMPONENT6" 32 "SUBCOMPONENT5" 31 "SUBCOMPONENT4" 24 "SUBCOMPONENT3" 23 "SUBCOMPONENT2" 20 "UDS_PROTOCOL_BOOTCRC" 19 "VERSION_DEPRECATED" 18 "BOOTLOADER_GITHASH" 17 "APP_GITHASH" 16 "SUBCOMPONENT1" 15 "BOOTLOADER_CRC" 14 "BOOTLOADER_SVN" 13 "APP_CRC" 11 "PCBAID_ASSYID_USAGEID" 10 "BUILD_HWID_COMPONENTID" 9 "DEPRECATED_9" 8 "DEPRECATED_8" 7 "DEPRECATED_7" 6 "DEPRECATED_6" 5 "DEPRECATED_5" 4 "DEPRECATED_4" 3 "DEPRECATED_3" 2 "DEPRECATED_2" 1 "DEPRECATED_1" 0 "DEPRECATED_0" ;
VAL_ 1357 TAS_infoBuildType 4 "INFO_MFG_BUILD" 3 "INFO_TRACEABLE_CI_BUILD" 2 "INFO_LOCAL_BUILD" 1 "INFO_PLATFORM_BUILD" 0 "INFO_UNKNOWN_BUILD" ;
VAL_ 1357 TAS_infoAssemblyId 255 "ASSEMBLY_SNA" 1 "ASSEMBLY1" ;
VAL_ 1357 TAS_infoMajorVersion 255 "SNA" 254 "LOCAL_BUILD" ;
VAL_ 1357 TAS_infoBranchOrigin 255 "SNA" 254 "LOCAL_BUILD" ;
VAL_ 1357 TAS_infoMaturity 255 "SNA" 254 "LOCAL_BUILD" ;
VAL_ 1357 TAS_infoHardwareRevision 255 "SNA" 254 "LOCAL_BUILD" ;
VAL_ 525 TAS_levelingState 15 "LEVELING_STATE_CROSSLINK" 14 "LEVELING_STATE_QUIET_EXHAUST" 13 "LEVELING_STATE_EXHAUST_RESERVOIR" 12 "LEVELING_STATE_LOWER_SPRING_WITH_COMPRESSOR" 11 "LEVELING_STATE_LOWER_SPRING" 10 "LEVELING_STATE_FILL_SPRING_RESERVOIR_FROM_COMPRESSOR" 9 "LEVELING_STATE_FILL_SPRING_FROM_RESERVOIR" 8 "LEVELING_STATE_FILL_SPRING_FROM_BOOST" 7 "LEVELING_STATE_FILL_SPRING_FROM_COMPRESSOR" 6 "LEVELING_STATE_FILL_RESERVOIR_FROM_COMPRESSOR" 5 "LEVELING_STATE_COMPRESSOR_PREFILL_GALLERY" 4 "LEVELING_STATE_COMPRESSOR_RAMPUP" 3 "LEVELING_STATE_EXHAUST_GALLERY" 2 "LEVELING_STATE_MEASURE_SPRING_PRESSURE" 1 "LEVELING_STATE_READ_P_RESERVOIR" 0 "LEVELING_STATE_IDLE" ;
VAL_ 525 TAS_levelingItem 7 "TAS_LEVELING_ITEM_ALL" 6 "TAS_LEVELING_ITEM_REAR_AXLE" 5 "TAS_LEVELING_ITEM_FRONT_AXLE" 4 "TAS_LEVELING_ITEM_RR" 3 "TAS_LEVELING_ITEM_RL" 2 "TAS_LEVELING_ITEM_FR" 1 "TAS_LEVELING_ITEM_FL" 0 "TAS_LEVELING_ITEM_NONE" ;
VAL_ 525 TAS_pressureGallery 255 "SNA" ;
VAL_ 525 TAS_pressureReservoir 255 "SNA" ;
VAL_ 525 TAS_runMode 7 "RUN_MODE_DYNO" 6 "RUN_MODE_LOW_POWER" 5 "RUN_MODE_NORMAL" 4 "RUN_MODE_DAN" 3 "RUN_MODE_ASSEMBLY" 2 "RUN_MODE_SERVICE" 1 "RUN_MODE_SYSTEM_CHECK" 0 "RUN_MODE_INIT" ;
VAL_ 525 TAS_filterMode 7 "MODE_STOPPING" 6 "MODE_DRIVE" 5 "MODE_LOADING" 4 "MODE_READY" 3 "MODE_TEST" 2 "MODE_CALIBRATE" 1 "MODE_INIT" 0 "MODE_NONE" ;
VAL_ 525 TAS_limpHomeMode 4 "LIMP_HOME_MODE_40" 3 "LIMP_HOME_MODE_30" 2 "LIMP_HOME_MODE_20" 1 "LIMP_HOME_MODE_10" 0 "LIMP_HOME_MODE_0" ;
VAL_ 525 TAS_targetLevel 4 "TAS_VERY_LOW" 3 "TAS_LOW" 2 "TAS_STANDARD" 1 "TAS_HIGH" 0 "TAS_VERY_HIGH" ;
VAL_ 525 TAS_currentLevel 4 "TAS_VERY_LOW" 3 "TAS_LOW" 2 "TAS_STANDARD" 1 "TAS_HIGH" 0 "TAS_VERY_HIGH" ;
VAL_ 409 TAS_adaptiveActivityFL_C 31 "SNA" ;
VAL_ 409 TAS_adaptiveActivityFL_R 31 "SNA" ;
VAL_ 409 TAS_adaptiveActivityFR_C 31 "SNA" ;
VAL_ 409 TAS_adaptiveActivityFR_R 31 "SNA" ;
VAL_ 409 TAS_adaptiveActivityRL_C 31 "SNA" ;
VAL_ 409 TAS_adaptiveActivityRL_R 31 "SNA" ;
VAL_ 409 TAS_adaptiveActivityRR_C 31 "SNA" ;
VAL_ 409 TAS_adaptiveActivityRR_R 31 "SNA" ;
VAL_ 409 TAS_uiHeightFL 63 "SNA" ;
VAL_ 409 TAS_uiHeightFR 63 "SNA" ;
VAL_ 409 TAS_uiHeightRL 63 "SNA" ;
VAL_ 409 TAS_uiHeightRR 63 "SNA" ;
VAL_ 410 TAS_bodyAccelFL 255 "SNA" ;
VAL_ 410 TAS_bodyAccelFR 255 "SNA" ;
VAL_ 410 TAS_bodyAccelRL 255 "SNA" ;
VAL_ 410 TAS_bodyAccelRR 255 "SNA" ;
VAL_ 538 TAS_adaptiveRideModeOverride 3 "TAS_ADAPTIVE_RIDE_MODE_SNA" 2 "TAS_ADAPTIVE_RIDE_MODE_SPORT" 1 "TAS_ADAPTIVE_RIDE_MODE_AUTO" 0 "TAS_ADAPTIVE_RIDE_MODE_COMFORT" ;
VAL_ 538 TAS_launchModeState 4 "TAS_LAUNCH_MODE_STATE_RAISE_SUSPENSION" 3 "TAS_LAUNCH_MODE_STATE_READY" 2 "TAS_LAUNCH_MODE_STATE_LOWER_SUSPENSION" 1 "TAS_LAUNCH_MODE_STATE_IDLE" 0 "TAS_LAUNCH_MODE_STATE_BLOCKED" ;
VAL_ 1410 TCU_alertID 6 "w006_MpssUnavailable" 5 "w005_SIMSlotError" 4 "w004_MSDTransmissionFailed" 3 "w003_ECallFailed" 2 "w002_CellRegRejected" 1 "w001_IMSRegistrationFailed" 0 "ALERT_DO_NOT_USE_ZERO" ;
VAL_ 1410 TCU_alertState 1 "SET" 0 "CLEARED" ;
VAL_ 1409 TCU_logMux 15 "mdmBusyActive" 14 "mdmSIMStatus" 13 "mdmIMSStatus" 12 "mdmServiceState" 11 "mdmUplinkAvgRage" 10 "mdmUplinkAllowedRate" 9 "mdmSINR" 8 "mdmRSRP" 7 "mdmUplinkQueueSize" 6 "totalResumes" 5 "pwmcap" 4 "pwm" 3 "availableMemory" 2 "mdmCoreTemperature" 1 "cpuUsage" 0 "cpuTemp" ;
VAL_ 1409 TCU_mdmBusyActive 4294967295 "SNA" ;
VAL_ 1408 TCU_statusMux 2 "goingToSleep" 1 "tcuCmdId" 0 "wakeUpReason" ;
VAL_ 1408 TCU_wakeUpReason 4294967295 "SNA" ;
VAL_ 1408 TCU_goingToSleep 4294967295 "SNA" ;
VAL_ 879 TPMS_learningStatus 3 "PASSED" 2 "STOPPED" 1 "ONGOING" 0 "FAILED" ;
VAL_ 879 TPMS_localisationStatus 3 "PASSED" 2 "STOPPED" 1 "ONGOING" 0 "FAILED" ;
VAL_ 802 TPMS_pressureFL 255 "SNA" 254 "OVER_RANGE" ;
VAL_ 802 TPMS_temperatureFL 255 "TPMS_TEMPERATURE_SNA" ;
VAL_ 802 TPMS_pressureFR 255 "SNA" 254 "OVER_RANGE" ;
VAL_ 802 TPMS_temperatureFR 255 "TPMS_TEMPERATURE_SNA" ;
VAL_ 802 TPMS_pressureRL 255 "SNA" 254 "OVER_RANGE" ;
VAL_ 802 TPMS_temperatureRL 255 "TPMS_TEMPERATURE_SNA" ;
VAL_ 802 TPMS_pressureRR 255 "SNA" 254 "OVER_RANGE" ;
VAL_ 802 TPMS_temperatureRR 255 "TPMS_TEMPERATURE_SNA" ;
VAL_ 1519 TPMS_infoIndex 255 "END" 31 "SUBCOMPONENT_GITHASH" 30 "PACKAGE_SN_8_14" 29 "PACKAGE_SN_1_7" 27 "PACKAGE_PN_15_20" 26 "PACKAGE_PN_8_14" 25 "PACKAGE_PN_1_7" 23 "SUBCOMPONENT2" 22 "VARIANTCRC" 20 "UDS_PROTOCOL_BOOTCRC" 19 "VERSION_DEPRECATED" 18 "BOOTLOADER_GITHASH" 17 "APP_GITHASH" 16 "SUBCOMPONENT" 15 "BOOTLOADER_CRC" 14 "BOOTLOADER_SVN" 13 "APP_CRC" 11 "PCBAID_ASSYID_USAGEID" 10 "BUILD_HWID_COMPONENTID" 9 "DEPRECATED_9" 8 "DEPRECATED_8" 7 "DEPRECATED_7" 6 "DEPRECATED_6" 5 "DEPRECATED_5" 4 "DEPRECATED_4" 3 "DEPRECATED_3" 2 "DEPRECATED_2" 1 "DEPRECATED_1" 0 "DEPRECATED_0" ;
